VERSION ""

NS_ :

BS_:

BU_: Sound_A Ladegeraet_PAG_PF Motor_EDC17_Pirol PSM_Ant_Derivate GW_Routing_Derivate GW_Applikation_Derivate BMS_Hybrid Getriebe_Derivate LEH_Hybrid Motor_MED17_Hybrid Sound_I Tool Airbag Waehlhebel
VAL_TABLE_ KBI_ASD_Ein_Aus 1 "An" 0 "Aus" ;
VAL_TABLE_ MO_Hybridfahrzeug 3 "PlugIn_Hybrid" 2 "Full_Hybrid" 1 "Mild_Hybrid" 0 "kein_Hybridfahrzeug" ;
VAL_TABLE_ KBI_Automem_inaktiv 1 "Automem nicht aktiv" 0 "Automem aktiv" ;
VAL_TABLE_ QBit 1 "Ersatz-, Init- oder Fehlerwert" 0 "gültiger Wert" ;
VAL_TABLE_ STH_Zusatzheizung 1 "Zuheizer ein" 0 "Zuheizer aus" ;
VAL_TABLE_ xT_Tuer_geoeffnet 1 "Tuer geoeffnet" 0 "Tuer nicht geoeffnet" ;
VAL_TABLE_ KL_Zuheizer_Freigabe 1 "Zuheizerfreigabe" 0 "keine Freigabe Zuheizer" ;
VAL_TABLE_ Fehler_7Bit 127 "Fehler" ;
VAL_TABLE_ AAG_Anhaenger_abgesteckt 1 "Anhaenger wurde bei Kl. 15 aus abgesteckt" ;
VAL_TABLE_ SI_QRS_Mode 0 "QRS_Messmodus_nicht_aktiv" 1 "QRS_Messmodus_aktiv" ;
VAL_TABLE_ KY_WFS_Safe 1 "WFS nicht deaktiviert" ;
VAL_TABLE_ KYL_Warn_kein_Schluessel 0 "kein Schlüssel erkannt" ;
VAL_TABLE_ KY_Keyless_Verbau 1 "Keyless verbaut" 0 "kein Keyless verbaut" ;
VAL_TABLE_ KY_Valet_Parking 1 "Valet Schlüssel erkannt" 0 "kein Valet Schlüssel erkannt" ;
VAL_TABLE_ BCM1_MH_WIV_Schalter 1 "MH offen" 0 "MH geschlossen" ;
VAL_TABLE_ GE_MMom_Status 3 "Änderung mit Sprung" 2 "erhöhender Getriebeeingriff" 1 "reduzierender Getriebeeingriff" 0 "keine Anforderung" ;
VAL_TABLE_ GE_MMom_Soll 1023 "Fehler" 1022 "kein Eingriff" ;
VAL_TABLE_ GE_Status_Kupplung 3 "Fehler" 2 "Kupplung geschlossen" 1 "Kupplung geregelt" 0 "Kupplung geöffnet" ;
VAL_TABLE_ GE_Schaltvorgang 1 "Schaltung aktiv" 0 "keine Schaltung" ;
VAL_TABLE_ WH_Warnung 1 "Waehlhebelfehler_Fahrstufenwechsel_moeglich_(gelbes_Getriebesymbol)" 0 "keine_Anzeige" ;
VAL_TABLE_ WBA_Lampe_Shift_Lock 1 "SL_Lampe_ein" 0 "SL_Lampe_aus" ;
VAL_TABLE_ WBA_Senderkennung 1 "Motor" 0 "Getriebe" ;
VAL_TABLE_ WBA_Getriebevariante 15 "9 Gang Automat Tiptronic" 14 "8 Gang Automat Tiptronic" 13 "7 Gang Automat Tiptronic" 12 "6 Gang Automat Tiptronic" 11 "5 Gang Automat Tiptronic" 10 "tbd." 9 "tbd." 8 "2x3 shift_by_wire" 7 "tbd." 6 "Automat PRNDS" 5 "tbd." 4 "Vorhalt für ASG (Selespeed)" 3 "tbd." 2 "tbd." 1 "Automat PRND" ;
VAL_TABLE_ WBA_eing_Gang 10 "9.Gang" 9 "8.Gang" 8 "7.Gang" 7 "6.Gang" 6 "5.Gang" 5 "4.Gang" 4 "3.Gang" 3 "2.Gang" 2 "1.Gang" 1 "Init" 0 "kein Gang eingelegt / kein Gang empfohlen" ;
VAL_TABLE_ WBA_Blinken 1 "WBA_Blinken" 0 "kein_WBA_Blinken" ;
VAL_TABLE_ WBA_GE_Warnung 7 "Kupplung ueberhitzt, Fahrzeug Stopp (+ rotes Getriebefehlersymbol)" 6 "Kupplung ueberhitzt, Fahrzeug Stopp (+ gelbes Getriebefehlersymbol)" 5 "Wegrollgefahr! P nicht möglich" 4 "Getriebefehler, Weiterfahrt nur in D moeglich, P bei Motor aus" 3 "nur DL-Getriebe: Weiterfahrt nur eingeschränkt möglich. Kein R-Gang" 2 "Weiterfahrt nur eingeschränkt möglich (+ gelbes Getriebefehlersymbol)" 1 "Weiterfahrt möglich (+ gelbes Getriebefehlersymbol)" 0 "keine Anzeige" ;
VAL_TABLE_ WBA_GE_Texte 4 "Achtung_Zeitueberschreitung_P_wird_eingelegt" 3 "Wegrollgefahr_bitte_P_einlegen" 2 "zum_Einlegen_von_R,N,D_Fussbremse_betaetigen_und_Motor_starten" 1 "zum_Einlegen_einer_Fahrstufe_Fussbremse_betaetigen__ShiftLock_Information" 0 "keine Anzeige" ;
VAL_TABLE_ Veraltet_Bit 1 "veraltet" 0 "aktuell" ;
VAL_TABLE_ KBI_Variante_USA 1 "USA-Variante" 0 "keine USA-Variante" ;
VAL_TABLE_ BCM2_Bremsl_durch_ECD 1 "Bremslicht_durch_ECD_aktiv" 0 "Bremslicht_ist_aus" ;
VAL_TABLE_ KL_Thermomanagement 3 "volle Freigabe TMM (kein Heizbedarf)" 2 "mittlere Freigabe TMM" 1 "kleine Freigabe TMM" 0 "keine Freigabe TMM (max. Heizbedarf)" ;
VAL_TABLE_ KL_Atemp_ungef 255 "Fehler" 0 "Initwert" ;
VAL_TABLE_ ACC_Abstandsindex 1023 "Sonderanzeige_Fahrbahn_mit_gruenem_roten_Bereich" 1022 "Sonderanzeige_graue_Fahrbahn" 0 "Sonderanzeige_graue_Fahrbahn" ;
VAL_TABLE_ DGN_Verlernzaehler 255 "ungültiger Zählerstand oder kein gültiger Fahrzyklus" ;
VAL_TABLE_ NMH_GE_N_Haltephase 1 "N_Haltephase_aktiv" 0 "keine_N_Haltephase" ;
VAL_TABLE_ WBA_Schaltschema_Aktiv 1 "Schaltschema_anzeigen" 0 "keine_Anzeige" ;
VAL_TABLE_ MO_HYB_IstStatusK0 3 "Fehler" 2 "zu" 1 "Uebergang" 0 "auf" ;
VAL_TABLE_ NMH_MO_NM_aktiv_HV_Abschaltung 1 "Abschaltung_aktiv" 0 "kein_Nachlauf" ;
VAL_TABLE_ MO_Text_Motorstart 11 "(Belegt bei VW/Audi)" 10 "(Belegt bei VW/Audi)" 9 "(Belegt bei VW/Audi)" 8 "(Vorhalt für Start/Stopp) " 7 "(Vorhalt für Start/Stopp) " 6 "(Vorhalt für Start/Stopp) " 5 "Start/Stopp temporär nicht verfügbar" 4 "Nicht belegt (Vorhalt AUDI)" 15 "Bremse treten" 14 "Waehlhebel in PN Position" 13 "Kupplung betaetigt" 12 "Motor startet" 3 "System fordert Wiederstart" 2 "StartStopp sicherheitsbedingt deaktiviert" 1 "Motor im Stoppbetrieb" 0 "keine Anzeige" ;
VAL_TABLE_ MO_StartStopp_Codiert 1 "StartStopp vorhanden/verbaut" 0 "StartStopp nicht vorhanden/verbaut" ;
VAL_TABLE_ KBI_WV_Entr_Kof 15 "80 Sek." 14 "75 Sek." 13 "70 Sek." 12 "65 Sek." 11 "60 Sek." 10 "55 Sek." 9 "50 Sek." 8 "45 Sek." 7 "40 Sek." 6 "35 Sek." 5 "30 Sek." 4 "25 Sek." 3 "20 Sek." 2 "15 Sek." 1 "10 Sek." 0 "Türen werden nicht entriegelt" ;
VAL_TABLE_ Basiscodierung 1 "Basiscodierung invertiert" 0 "Basiscodierung" ;
VAL_TABLE_ Fehler_Init_13Bit 8191 "Fehlerwert" 8190 "Initwert" ;
VAL_TABLE_ KBI_angez_Geschw 1023 "Fehlerwert" ;
VAL_TABLE_ ESP_SpannungsAnf 1 "Anforderung Spannungswert 1" 0 "keine Anforderung" ;
VAL_TABLE_ LS_Codierung 7 "nicht verwendet" 6 "nicht verwendet" 5 "ACC Hebel, Tiptronic am Lenkrad" 4 "ACC Hebel, keine Tiptronic am Lenkrad" 3 "GRA Hebel, Tiptronic am Lenkrad" 2 "GRA Hebel, keine Tiptronic am Lenkrad" 1 "kein Hebel, Tiptronic am Lenkrad" 0 "kein Hebel, keine Tiptronic am Lenkrad" ;
VAL_TABLE_ LS_Fehler 1 "Fehler Bedienteil" 0 "in Ordnung" ;
VAL_TABLE_ Tippschalter_betaetigt 1 "Tippschalter betaetigt" 0 "Tippschalter nicht betaetigt" ;
VAL_TABLE_ LS_Abbrechen 1 "Tippschalter betätigt" 0 "Tippschalter nicht betätigt" ;
VAL_TABLE_ LS_Hauptschalter 1 "Ein" 0 "Gerastet Aus" ;
VAL_TABLE_ AAG_Bremsl_durch_ECD 1 "Bremslicht durch ECD aktiv" 0 "Bremslicht ist aus" ;
VAL_TABLE_ HU_Fotosensor 511 "Fehler" 510 "Init" 0 "Sensor unbeleuchtet" ;
VAL_TABLE_ PDCC_Last_RKP 255 "Fehlerwert" 0 "Init" ;
VAL_TABLE_ KY_WFS_LZ 3 "LZ 3" 2 "LZ 2" 1 "LZ 1" 0 "nicht def." ;
VAL_TABLE_ Freigabe_angefordert 1 "Freigabe wird angefordert" 0 "Freigabe nicht angefordert" ;
VAL_TABLE_ entriegelt_nicht_entriegelt 1 "entriegelt" 0 "nicht entriegelt" ;
VAL_TABLE_ verriegelt_nicht_verriegelt 1 "verriegelt" 0 "nicht verriegelt" ;
VAL_TABLE_ KY_FFB_Frequenz 3 "868 MHz" 2 "315 MHz" 1 "433 MHz" ;
VAL_TABLE_ KY_ID_Geb_steckt 1 "Schlüssel steckt im Zündschloss" 0 "kein Schlüssel im Zündschloss" ;
VAL_TABLE_ FFB_Taste_betaetigt 1 "Taste am Funkschlüssel betätigt" 0 "Taste nicht betätigt" ;
VAL_TABLE_ authorisiert_nicht_authorisiert 1 "authorisiert" 0 "nicht authorisiert" ;
VAL_TABLE_ OK_Defekt 1 "defekt" 0 "OK" ;
VAL_TABLE_ KL_4_Zonen 1 "4_Zonen_Klimaanlage" 0 "2_Zonen_Klimaanlage" ;
VAL_TABLE_ AB_RGS_Anst 8 "deaktiviert" 7 "aktiv_Niveau_4" 6 "aktiv_Niveau_3" 5 "aktiv_Niveau_2" 4 "aktiv_Niveau_1" ;
VAL_TABLE_ AB_Texte_AKS 2 "AKS_Systemfehler" 1 "AKS_ausgeloest" 0 "keine_AKS_Ausloesung" ;
VAL_TABLE_ SI_NWDF_gueltig 1 "NWDF_wird_unterstuetzt" 0 "NWDF_wird_nicht_unterstuetzt" ;
VAL_TABLE_ SI_NWDF 1 "Ueberwachung_freigeben" 0 "Ueberwachung_nicht_freigeben" ;
VAL_TABLE_ MO_Ext_E_Fahrt_aktiv 1 "Rueckmeldung_E_Taster_ein" 0 "Rueckmeldung_E_Taster_aus" ;
VAL_TABLE_ KL_Geblaese_Status 15 "Fehler" 14 "Init" 10 "Geblaese Stufe 100%" 9 "Geblaese Stufe 90%" 8 "Geblaese Stufe 80%" 7 "Geblaese Stufe 70%" 6 "Geblaese Stufe 60%" 5 "Geblaese Stufe 50%" 4 "Geblaese Stufe 40%" 3 "Geblaese Stufe 30%" 2 "Geblaese Stufe 20%" 1 "Geblaese Stufe 10%" 0 "Geblaese aus" ;
VAL_TABLE_ KBI_Kilometerstand 1048575 "Fehlerwert" 1048574 "Initwert" ;
VAL_TABLE_ Warnmeldung 1 "Warnmeldung" 0 "keine Warnmeldung" ;
VAL_TABLE_ EPB_Anfahrwunsch_erkannt 1 "Anfahrwunsch erkannt" 0 "kein Anfahrwunsch erkannt" ;
VAL_TABLE_ BEM_n_LLA 3 "Stufe 3" 2 "Stufe 2" 1 "Stufe 1" 0 "keine Erhöhung" ;
VAL_TABLE_ ACC_Anhalten 1 "Anhalten gewünscht" 0 "kein Anhalten gewünscht" ;
VAL_TABLE_ ACC_Beeinflussung_ESP 1 "ESP Zwangszuschaltung" 0 "keine ESP Zwangszuschaltung" ;
VAL_TABLE_ ACC_Betaetigung_EPB 1 "EPB Aktuator schliessen" 0 "keine EPB Anforderung" ;
VAL_TABLE_ ACC_Status_ACC 7 "irreversibler_Fehler_im_ACC_System" 6 "reversibler_Fehler_im_ACC_System" 5 "nicht_definiert" 4 "ACC_OVERRIDE" 3 "ACC_AKTIV_regelt" 2 "ACC_STANDBY" 1 "ACC_INIT" 0 "ACC_OFF_Hauptschalter_aus" ;
VAL_TABLE_ ACC_Loeseanforderung 1 "Löseanforderung" 0 "keine Löseanforderung" ;
VAL_TABLE_ ACC_limitierte_Anfahrdyn 1 "Limitierung Anfahrdynamik angefordert" 0 "keine Limitierung" ;
VAL_TABLE_ ACC_Getriebestellung_P 1 "Anforderung P Stellung" 0 "P Stellung nicht angefordert" ;
VAL_TABLE_ ACC_Freigabe_Verzanf 1 "Verzögerungsanforderung freigegeben" 0 "Verzögerungsanforderung nicht freigegeben" ;
VAL_TABLE_ ACC_Freigabe_Momentenanf 1 "Momentenanforderung freigegeben" 0 "Momentenanforderung nicht freigegeben" ;
VAL_TABLE_ SI_T_Mode 1 "Transportmode aktiv" 0 "Transportmode nicht aktiv" ;
VAL_TABLE_ Betaetigt 1 "betätigt" 0 "nicht betätigt" ;
VAL_TABLE_ KBI_MFA_v_Einheit_02 1 "mph" 0 "kmh" ;
VAL_TABLE_ KBI_Einheit_Druck 3 "tbd" 2 "Druckangabe in kPa" 1 "Druckangabe in psi" 0 "Druckangabe in bar" ;
VAL_TABLE_ KL_MSG_valid 1 "Message valid" 0 "Message not valid" ;
VAL_TABLE_ MO_StartStopp_Motorstopp 1 "Motor_Stop_aktiv" 0 "Motor_Stop_inaktiv" ;
VAL_TABLE_ MO_StartStopp_Wiederstart 1 "Wiederstart_aktiv" 0 "Wiederstart_inaktiv" ;
VAL_TABLE_ KBI_Aussen_Temp_gef 255 "Fehler" 254 "Init" 253 "nicht verbaut" ;
VAL_TABLE_ MO_Kraftstoffart 4 "Wasserstoff" 3 "Erdgas" 2 "CNG" 1 "Benzin" 0 "Diesel" ;
VAL_TABLE_ AB_Sitzpos_Sens 3 "Sitz vorne" 2 "Sitz nicht vorne" 1 "Fehler" 0 "nicht verfügbar" ;
VAL_TABLE_ AB_Gurtschloss 3 "gesteckt" 2 "nicht_gesteckt" 1 "nicht_verfügbar (Fehler oder Init)" 0 "nicht_verbaut" ;
VAL_TABLE_ FAS_Wunschgeschw 1023 "nicht definiert" 1022 "keine Anzeige" ;
VAL_TABLE_ FAS_Texte_Primaeranz 66 "ESP PASSIV !" 65 "Bremse haelt !" 64 "Bremse ueberhitzt !" 63 "LIM FEHLER" 62 "LIM PASSIV" 61 "LIM AKTIV " 60 "LIM AUS" 59 "Kupplung betaetigt" 58 "Bremse betaetigen !" 57 "ACC haelt an !" 56 "ACC Fehler" 55 "ACC reinigen" 54 "ACC startet" 53 "ACC aus" 52 "SET / 'GRA Symbol' xxx km/h / mph" 51 "SET / 'GRA Symbol'___xxx km/h / mph" 50 "Stehendes Objekt voraus" 49 "Steigung zu gross" 48 "Uebernehmen !" 47 "braking guard aus" 46 "braking guard aus " 45 "braking guard Bremsruck" 44 "HDC aktiv" 43 "Tempolimit Ende XXX km/h / mph" 42 "Ortsende XXX km/h / mph" 41 "Ortsanfang XXX km/h / mph" 40 "Abbiegeassistent" 39 "Tempolimit aus" 38 "Kurvenassistent aus" 37 "Drehzahl !" 36 "Schalthebelposition !" 35 "Fahrer Gurtschloss offen !" 34 "Tuer offen !" 33 "Ungueltiger Anfahrbefehl" 32 "Im Stand nicht moeglich" 31 "Fahrzeug verloren" 30 "Anfahren bestaetigen" 29 "Lenkradwinkel" 28 "XXX km/h / mph (Schriftart 2)" 27 "--- km/h / mph" 26 "!" 25 "Symbol 'Eieruhr'" 24 "ACC Abschaltung" 23 "Kurve XXX km/h / mph" 22 "Tempolimit XXX km/h / mph" 21 "VDA ACC-Symbol YYY km/h / mph" 20 "Waehlhebelposition !" 19 "Geschwindigkeitsgrenze" 18 "Parkbremse !" 17 "Herunterschalten" 16 "ESP Eingriff" 15 "Hochschalten" 14 "o  o  o" 13 "ACC nicht verfuegbar" 12 "ACC Sensor Sicht !" 11 "keine Abstandsregelung" 10 "ACC bereit" 9 "Auto_ _ _ _Auto Gong (durchgestrichen)" 8 "Auto_ _ _Auto_ Gong (durchgestrichen)" 7 "Auto_ _Auto_ _ Gong (durchgestrichen)" 6 "Auto_Auto_ _ _ Gong (durchgestrichen)" 5 "Auto_ _ _ _Auto" 4 "Auto_ _ _Auto_" 3 "Auto_ _Auto_ _" 2 "Auto_Auto_ _ _" 1 "ACC nicht verfuegbar !" 0 "keine Anzeige " ;
VAL_TABLE_ FAS_Status_Prim_Anz 3 "Farbe 3 (typisch 'gelb')" 2 "Farbe 2 (typisch 'rot')" 1 "Farbe 1 (typisch 'grün')" 0 "Symbol nicht beleuchtet" ;
VAL_TABLE_ FAS_Status_Anzeige 7 "ACC/GRA irreversibel aus" 6 "ACC reversibel aus (nicht bei GRA)" 5 "frei" 4 "ACC/GRA im Hintergrund (übertreten)" 3 "ACCGRA aktiv" 2 "ACC/GRA passiv" 1 "ACC in Init (nicht bei GRA)" 0 "ACC/GRA Hauptschalter aus" ;
VAL_TABLE_ KD_Fehler 1 "mind. ein KD-Fehler vorhanden" 0 "kein KD-Fehler" ;
VAL_TABLE_ AB_Crashdaten 1 "Crashdaten gespeichert" 0 "keine Daten gespeichert" ;
VAL_TABLE_ GE_poshebel_VAG 15 "Fehler" 14 "Tippfunktion" 13 "frei" 12 "frei" 11 "frei" 10 "frei" 9 "Position S" 8 "Position D" 7 "Position N" 6 "Position R" 5 "Position P" 4 "frei" 3 "frei" 2 "frei" 1 "Init" 0 "Zwischenstellung" ;
VAL_TABLE_ KL_St_Heizkreis 1 "Wasserventil geschlossen" 0 "Wasserventil geoeffnet" ;
VAL_TABLE_ FSAktivBit 1 "Fehler speichern" 0 "keine Fehler speichern" ;
VAL_TABLE_ KL_St_Atemp 3 "Unterbrechung" 4 "Sensorsignal unplausibel" 2 "Kurzschluss gegen Spg > 5V" 1 "Kurzschluss nach Masse" 0 "Kein Fehler" ;
VAL_TABLE_ MO_Handshake_STH 1 "EKP-Ansteuerung durch STH-Anforderung" 0 "keine EKP-Ansteuerung durch STH-Anforderung" ;
VAL_TABLE_ MO_StSt_Status 3 "Mindestens ein weiches oder hartes Veto liegt vor" 2 "Alle Vetos besagen,dass langfristig kein Motorlauf notwendig ist" 1 "Reversible Abschaltung aufgrund sicherheitsrelevanter Funktionen oder über einen Taster" 0 "Fehlerstatus erkannt oder Sicherheitsabschaltung aktiv" ;
VAL_TABLE_ StSt_Info 3 "Systemfehler" 2 "Motoranlauf zwingend notwendig (Startanforderung)" 1 "Motoranlauf nicht zwingend notwendig (Stoppverbot, keine Startanforderung, evtl. Komforteinbussen)" 0 "Motorlauf langfristig nicht notwendig (Stoppfreigabe)" ;
VAL_TABLE_ GW_STH_Anf 3 "STH Timer aktiv" 2 "Standheizung AUS" 1 "Standheizung EIN" 0 "keine EIN/AUS-Anf/kein Timer akt" ;
VAL_TABLE_ KBI_Einheit_Verbrauch 1 "mpg USA" 2 "Liter/100km" 0 "mpg UK" 3 "km/Liter" ;
VAL_TABLE_ KBI_Einheit_Volumen 3 "reserviert" 0 "Liter" 1 "Gallonen_UK" 2 "Gallonen_USA" ;
VAL_TABLE_ St_PAO_Leuchte 3 "ungültig" 2 "defekt" 1 "ein" 0 "aus" ;
VAL_TABLE_ verfuegbar 1 "verfuegbar" 0 "nicht verfuegbar" ;
VAL_TABLE_ EPB_Freig_Verzoeg_Anf 0 "Verzögerungsanforderung nicht freigegeben" 1 "Verzögerungsanforderung freigegeben" ;
VAL_TABLE_ EPB_Fehlerstatus 2 "EPB temporär nicht verfügbar - Spannen nicht möglich da Fzg. in Fahrt" 1 "EPB temporär nicht verfügbar - AVH darf nicht aktiv werden, sondern muss bei AVH-Anforderung warnen" 3 "Fehler in EPB - AVH darf von ESP nicht ausgeführt werden" 0 "kein Fehler in EPB - AVH darf von ESP ausgeführt werden" ;
VAL_TABLE_ AB_W_AWS_S 1 "Störung AWS (Sitz verspannt)" 0 "keine Störung" ;
VAL_TABLE_ Gurtwarnung 1 "Gurtwarnung auslösen" 0 "keine Warnung" ;
VAL_TABLE_ AB_PAO_Info 7 "AB BF akt.d.AWS,Schalt. a. AUTO" 6 "AB BF deakt.d.AWS,Schalt.a. AUTO" 5 "AB BF deakt.d.Schalt,AWS o.Einf." 4 "AB BF akt.d. AWS,kein Schalt.v." 3 "AB BF deakt.d.AWS,kein Schalt.v." 2 "AB BF akt.d.Schalt,kein AWS verb" 1 "AB BF deakt.d.Schalt,kein AWS v." 0 "Default / Initialwert" ;
VAL_TABLE_ AB_AWS_Zustand 7 "Fehler" 6 "Störung (Sitz verspannt)" 5 "schwerer Erwachsener" 4 "mittelschwerer Erwachsener" 3 "leichter Erwachener" 2 "Kind" 1 "Sitz leer" 0 "Default / Initialwert" ;
VAL_TABLE_ Klimastyles 3 "nicht definiert" 2 "strong" 1 "medium" 0 "soft" ;
VAL_TABLE_ Ein_Aus 1 "ein" 0 "aus" ;
VAL_TABLE_ KBI_Tankwarnung 1 "Tankwarnung aktiv" 0 "Tankwarnung nicht aktiv" ;
VAL_TABLE_ STH_Ansteuerung 3 "Heizleistung reduziert" 2 "Ein mit Motorvorwaermung" 1 "Ein" 0 "Aus" ;
VAL_TABLE_ Fzg_Antrieb 15 "Reserve" 14 "Reserve" 13 "Reserve" 12 "Reserve" 11 "Reserve" 10 "Reserve" 9 "Reserve" 8 "Reserve" 7 "Reserve" 6 "Reserve" 5 "Reserve" 4 "Reserve" 3 "Reserve" 2 "Reserve" 1 "Vierradantrieb" 0 "Zweiradantrieb" ;
VAL_TABLE_ SI_CAN_ 1 "Busruhe" 0 "keine Busruhe" ;
VAL_TABLE_ Diag_Rx_PCItype 3 "FlowControl (FC)" 2 "ConsecutiveFrame (CF)" 1 "FirstFrame (FF)" 0 "SingleFrame (SF)" ;
VAL_TABLE_ S_Brems 3 "betätigt" 2 "unplausibel" 1 "Reserve" 0 "nicht betätigt" ;
VAL_TABLE_ GE_poshebel 15 "Fehler" 14 "Manuellprog." 13 "kurzz. Manuellprog." 12 "frei" 11 "frei" 10 "frei" 9 "frei" 8 "Pos_P" 7 "Pos_R" 6 "Pos_N" 5 "Pos_D" 4 "Blinken_Pos_P" 3 "Blinken_Pos_R" 2 "Blinken_Pos_N" 1 "Blinken_Pos_D" 0 "Zwischenst." ;
VAL_TABLE_ magnet_pos 3 "nicht definiert" 2 "aktive Magnetstellung" 1 "Zwischenstellung" 0 "passive Magnetstellung" ;
VAL_TABLE_ KBI_Einheit_Sprache 255 "Fehler" 13 "Russisch" 12 "Portugiesisch" 11 "Türkisch" 10 "Schwedisch" 9 "Dänisch" 8 "Holländisch" 7 "Chinesisch (Simplified Chinese)" 6 "Japanisch (Katakana)" 5 "Italienisch" 4 "Spanisch" 3 "Französisch" 2 "US-Englisch" 1 "Englisch" 0 "Deutsch" ;
VAL_TABLE_ Sollverbau 1 "SG verbaut" 0 "SG nicht verbaut" ;
VAL_TABLE_ Schaltbeinfl 1 "Schaltverbot" 0 "keine_Beeinflussung" ;
VAL_TABLE_ Leuchten 1 "Leuchte an" 0 "Leuchte aus" ;
VAL_TABLE_ Lenker 1 "Rechtslenker" 0 "Linkslenker" ;
VAL_TABLE_ Karosserie_Typ 15 "Reserve" 14 "Reserve" 13 "Reserve" 12 "Reserve" 11 "Reserve" 10 "Reserve" 9 "Reserve" 8 "Reserve" 7 "Reserve" 6 "Reserve" 5 "Reserve" 4 "Reserve" 3 "Reserve" 2 "Targa" 1 "Cabrio" 0 "Coupe" ;
VAL_TABLE_ Baureihe 15 "Reserve" 14 "Reserve" 13 "Reserve" 12 "Reserve" 11 "Reserve" 10 "Reserve" 9 "Reserve" 8 "Reserve" 7 "Reserve" 6 "Reserve" 5 "Reserve" 4 "Reserve" 3 "Boxster" 2 "Carrera" 1 "Cayenne" 0 "Panamera" ;
VAL_TABLE_ Fehler_8Bit 255 "Fehler" ;
VAL_TABLE_ Fehler_1Bit 1 "Fehler" 0 "kein Fehler" ;
VAL_TABLE_ An_Aus 1 "an" 0 "aus" ;
VAL_TABLE_ Aktiv 1 "Aktiv" 0 "Inaktiv" ;
VAL_TABLE_ Taster 1 "Taster betätigt" 0 "Taster nicht betätigt" ;
VAL_TABLE_ B_Notbrems 1 "Notbremsung aktiv" 0 "Notbremsung nicht aktiv" ;

BO_ 3221225472 VECTOR__INDEPENDENT_SIG_MSG: 0 Vector__XXX
 SG_ KBI_Trip_E_Std : 0|15@1+ (1,0) [0|9999] "Unit_Hours" Vector__XXX
 SG_ KBI_Trip_E_Min : 0|6@1+ (1,0) [0|59] "Unit_Minut" Vector__XXX
 SG_ KBI_Service_km : 0|10@1+ (100,0) [0|102100] "" Vector__XXX
 SG_ KBI_Service_Zeit : 0|11@1+ (1,0) [0|2045] "" Vector__XXX
 SG_ KBI_Service_Typ : 0|2@1+ (1,0) [0|3] "" Vector__XXX
 SG_ DEV_BMS_Resp_07_Data : 0|64@1+ (1,0) [0|1.84467440737096E+019] "" Vector__XXX
 SG_ DEV_BMS_Resp_06_Data : 0|64@1+ (1,0) [0|1.84467440737096E+019] "" Vector__XXX
 SG_ DEV_BMS_Resp_05_Data : 0|64@1+ (1,0) [0|1.84467440737096E+019] "" Vector__XXX
 SG_ Mo_HVEM_HV_Abschaltanf : 0|1@1+ (1,0) [0|1] "" Vector__XXX
 SG_ MO_HVEM_HV_Maxleistung : 0|8@1+ (0.05,0) [0|12.5] "Unit_KiloWatt" Vector__XXX
 SG_ HVEM_Istleistung_Nebenverbrauch : 0|8@1+ (0.05,0) [0|12.5] "Unit_KiloWatt" Vector__XXX
 SG_ BMS_TauKuehlmittel__Temp_ : 0|8@1+ (1,0) [0|0] "" Vector__XXX
 SG_ SVB_IVB_FS_Fond : 0|1@1+ (1,0) [0|1] "" Vector__XXX
 SG_ SVB_IVB_FS : 0|1@1+ (1,0) [0|1] "" Vector__XXX
 SG_ SVB_IVB_BFS_Fond : 0|1@1+ (1,0) [0|1] "" Vector__XXX
 SG_ SVB_IVB_BFS : 0|1@1+ (1,0) [0|1] "" Vector__XXX
 SG_ SVB_KameraLow_FLA : 0|1@1+ (1,0) [0|1] "" Vector__XXX
 SG_ AWV_Halten : 0|1@1+ (1,0) [0|1] "" Vector__XXX
 SG_ ISO_Getriebe_01_Req_Data : 0|64@1+ (1,0) [0|1] "" Vector__XXX
 SG_ NMH_GW_VNSM_VC5 : 0|1@1+ (1,0) [0|1] "" Vector__XXX
 SG_ NMH_GW_VNSM_Wfpf : 0|1@1+ (1,0) [0|1] "" Vector__XXX

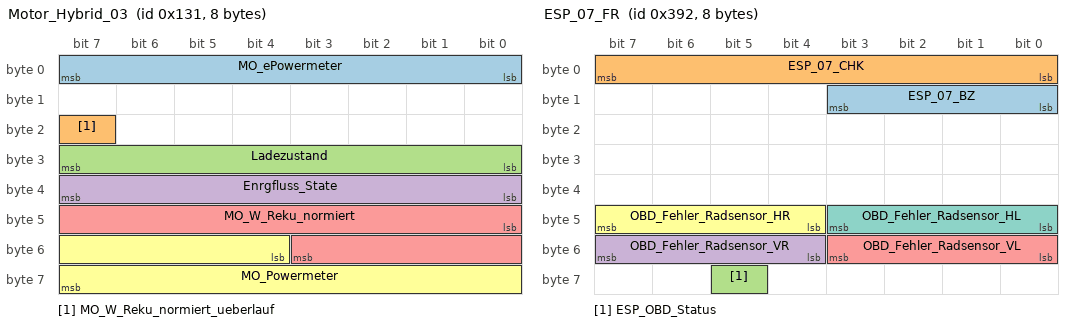
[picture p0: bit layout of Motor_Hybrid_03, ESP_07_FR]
BO_ 305 Motor_Hybrid_03: 8 Motor_MED17_Hybrid
 SG_ MO_ePowermeter : 0|8@1+ (0.4,-0.4) [0|100.8] "Unit_PerCent"  GW_Routing_Derivate
 SG_ MO_W_Reku_normiert_ueberlauf : 23|1@1+ (1,0) [0|1] ""  GW_Routing_Derivate
 SG_ Ladezustand : 24|8@1+ (1,0) [0|100] "Unit_PerCent"  Ladegeraet_PAG_PF,GW_Routing_Derivate,GW_Applikation_Derivate
 SG_ Enrgfluss_State : 32|8@1+ (1,0) [0|255] ""  GW_Routing_Derivate
 SG_ MO_W_Reku_normiert : 40|12@1+ (10,0) [0|40950] "Unit_WattSecond"  GW_Routing_Derivate
 SG_ MO_Powermeter : 52|12@1+ (1,0) [0|4092] ""  GW_Routing_Derivate

BO_ 914 ESP_07_FR: 8 PSM_Ant_Derivate
 SG_ ESP_07_BZ : 8|4@1+ (1,0) [0|15] ""  Motor_MED17_Hybrid
 SG_ ESP_07_CHK : 0|8@1+ (1,0) [0|255] ""  Motor_MED17_Hybrid
 SG_ ESP_OBD_Status : 61|1@1+ (1,0) [0|1] ""  Motor_MED17_Hybrid
 SG_ OBD_Fehler_Radsensor_VR : 52|4@1+ (1,0) [0|15] ""  Motor_MED17_Hybrid
 SG_ OBD_Fehler_Radsensor_VL : 48|4@1+ (1,0) [0|15] ""  Motor_MED17_Hybrid
 SG_ OBD_Fehler_Radsensor_HR : 44|4@1+ (1,0) [0|15] ""  Motor_MED17_Hybrid
 SG_ OBD_Fehler_Radsensor_HL : 40|4@1+ (1,0) [0|15] ""  Motor_MED17_Hybrid

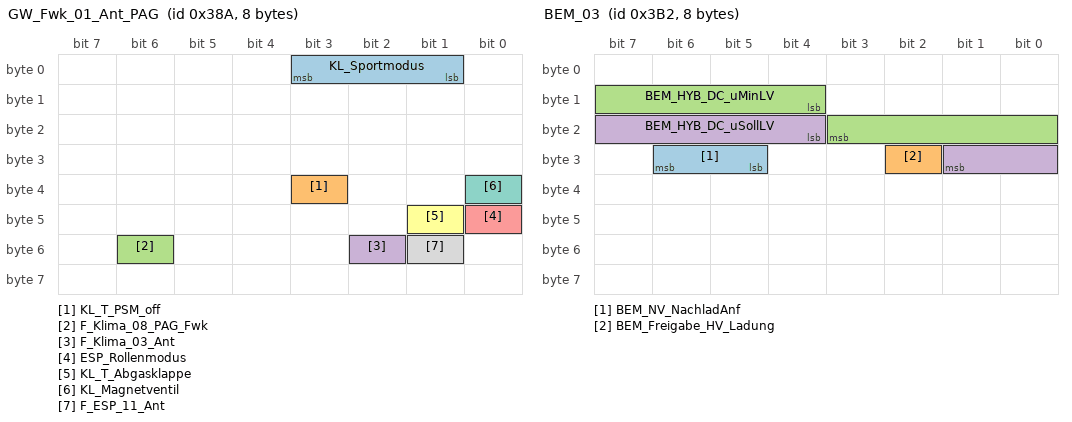
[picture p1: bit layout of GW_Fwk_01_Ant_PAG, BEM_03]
BO_ 906 GW_Fwk_01_Ant_PAG: 8 GW_Routing_Derivate
 SG_ KL_Sportmodus : 1|3@1+ (1,0) [0|7] "" Vector__XXX
 SG_ KL_T_PSM_off : 35|1@1+ (1,0) [0|1] ""  Getriebe_Derivate
 SG_ F_Klima_08_PAG_Fwk : 54|1@1+ (1,0) [0|1] ""  Motor_EDC17_Pirol,Getriebe_Derivate
 SG_ F_Klima_03_Ant : 50|1@1+ (1,0) [0|1] "" Vector__XXX
 SG_ ESP_Rollenmodus : 40|1@1+ (1,0) [0|1] "" Vector__XXX
 SG_ KL_T_Abgasklappe : 41|1@1+ (1,0) [0|1] ""  Motor_EDC17_Pirol
 SG_ KL_Magnetventil : 32|1@1+ (1,0) [0|1] "" Vector__XXX
 SG_ F_ESP_11_Ant : 49|1@1+ (1,0) [0|1] "" Vector__XXX

BO_ 1731 NMH_ESP: 7 PSM_Ant_Derivate
 SG_ NMH_ESP_Start_1 : 0|1@1+ (1,0) [0|1] ""  GW_Applikation_Derivate,Getriebe_Derivate,Motor_MED17_Hybrid,Motor_EDC17_Pirol,LEH_Hybrid,Ladegeraet_PAG_PF,BMS_Hybrid
 SG_ NMH_ESP_Start_2 : 1|1@1+ (1,0) [0|1] "" Vector__XXX
 SG_ NMH_ESP_Normal_Mode_1 : 2|1@1+ (1,0) [0|1] "" Vector__XXX
 SG_ NMH_ESP_Normal_Mode_2 : 3|1@1+ (1,0) [0|1] "" Vector__XXX
 SG_ NMH_ESP_Car_WakeUp : 6|1@1+ (1,0) [0|1] "" Vector__XXX
 SG_ NMH_ESP_Per_WakeUp : 8|5@1+ (1,0) [0|31] "" Vector__XXX
 SG_ NMH_ESP_Fkt_WakeUp : 13|3@1+ (1,0) [0|7] "" Vector__XXX
 SG_ NMH_ESP_NM_aktiv_Klemme_15 : 16|1@1+ (1,0) [0|1] "" Vector__XXX
 SG_ NMH_ESP_NM_aktiv_Diagnose : 17|1@1+ (1,0) [0|1] "" Vector__XXX
 SG_ NMH_ESP_NM_aktiv_Start : 18|1@1+ (1,0) [0|1] "" Vector__XXX
 SG_ NMH_ESP_NM_aktiv_v_groesser_Null : 19|1@1+ (1,0) [0|1] "" Vector__XXX
 SG_ NMH_ESP_Mindestaktivzeit : 21|1@1+ (1,0) [0|1] "" Vector__XXX
 SG_ NMH_ESP_kein_NL : 24|1@1+ (1,0) [0|1] "" Vector__XXX
 SG_ NMH_ESP_NL_Daten_EEPROM : 25|1@1+ (1,0) [0|1] "" Vector__XXX
 SG_ NMH_ESP_TimeOut_Fehler : 33|1@1+ (1,0) [0|1] "" Vector__XXX
 SG_ NMH_ESP_CAN_Diag_deaktiv : 34|1@1+ (1,0) [0|1] "" Vector__XXX
 SG_ NMH_ESP_KompSchutz : 35|1@1+ (1,0) [0|1] "" Vector__XXX
 SG_ NMH_ESP_Mute_Mode : 36|1@1+ (1,0) [0|1] "" Vector__XXX
 SG_ NMH_ESP_Transport_Mode : 37|1@1+ (1,0) [0|1] "" Vector__XXX
 SG_ NMH_ESP_Abschaltstufe_aktiv : 38|1@1+ (1,0) [0|1] "" Vector__XXX
 SG_ NMH_ESP_Eindraht_Fehler : 39|1@1+ (1,0) [0|1] "" Vector__XXX
 SG_ NMH_ESP_interne_Zust : 40|8@1+ (1,0) [0|255] "" Vector__XXX
 SG_ NMH_ESP_Lokalaktiv : 48|1@1+ (1,0) [0|1] "" Vector__XXX
 SG_ NMH_ESP_Subsystemaktiv : 49|1@1+ (1,0) [0|1] "" Vector__XXX

BO_ 946 BEM_03: 8 GW_Applikation_Derivate
 SG_ BEM_NV_NachladAnf : 29|2@1+ (1,0) [0|3] ""  Ladegeraet_PAG_PF
 SG_ BEM_Freigabe_HV_Ladung : 26|1@1+ (1,0) [0|1] "" Vector__XXX
 SG_ BEM_HYB_DC_uMinLV : 12|8@1+ (0.1,0) [0|25.3] "Unit_Volt"  LEH_Hybrid
 SG_ BEM_HYB_DC_uSollLV : 20|6@1+ (0.1,10.6) [10.6|16] "Unit_Volt"  LEH_Hybrid

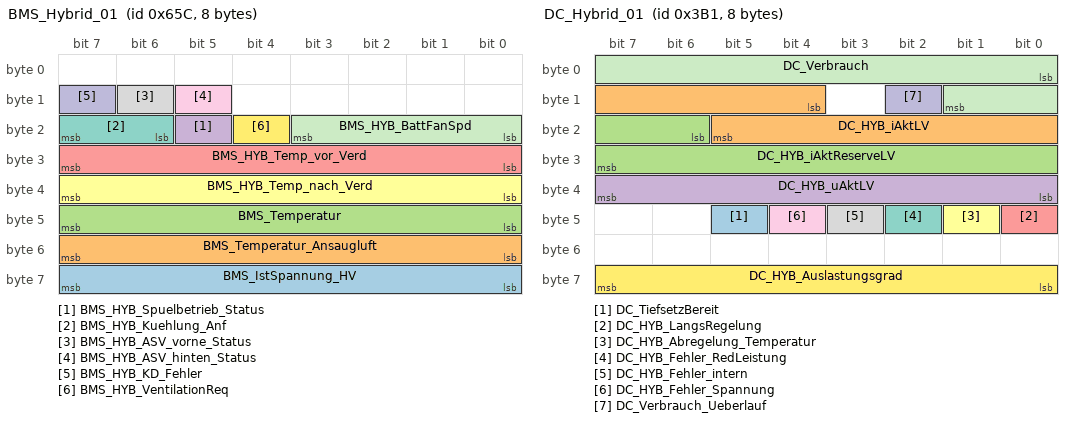
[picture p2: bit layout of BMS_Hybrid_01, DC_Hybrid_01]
BO_ 1628 BMS_Hybrid_01: 8 BMS_Hybrid
 SG_ BMS_IstSpannung_HV : 56|8@1+ (1,100) [100|350] "Unit_Volt"  GW_Routing_Derivate
 SG_ BMS_Temperatur_Ansaugluft : 48|8@1+ (0.5,-40) [-40|86.5] "Unit_DegreCelsi"  GW_Routing_Derivate
 SG_ BMS_Temperatur : 40|8@1+ (0.5,-40) [-40|86.5] "Unit_DegreCelsi"  GW_Routing_Derivate
 SG_ BMS_HYB_Spuelbetrieb_Status : 21|1@1+ (1,0) [0|1] ""  GW_Routing_Derivate
 SG_ BMS_HYB_Temp_vor_Verd : 24|8@1+ (0.5,-40) [-40|86.5] "Unit_DegreCelsi"  GW_Routing_Derivate
 SG_ BMS_HYB_Temp_nach_Verd : 32|8@1+ (0.5,-40) [-40|86.5] "Unit_DegreCelsi"  GW_Routing_Derivate
 SG_ BMS_HYB_Kuehlung_Anf : 22|2@1+ (1,0) [0|3] ""  GW_Applikation_Derivate,GW_Routing_Derivate
 SG_ BMS_HYB_ASV_vorne_Status : 14|1@1+ (1,0) [0|1] ""  GW_Routing_Derivate
 SG_ BMS_HYB_ASV_hinten_Status : 13|1@1+ (1,0) [0|1] ""  GW_Routing_Derivate
 SG_ BMS_HYB_KD_Fehler : 15|1@1+ (1,0) [0|1] ""  GW_Applikation_Derivate,GW_Routing_Derivate
 SG_ BMS_HYB_BattFanSpd : 16|4@1+ (10,0) [0|100] "Unit_PerCent"  GW_Routing_Derivate
 SG_ BMS_HYB_VentilationReq : 20|1@1+ (1,0) [0|1] ""  GW_Routing_Derivate

BO_ 490 CCP_GE_DTO_01: 8 Getriebe_Derivate
 SG_ CCP_GE_DTO_01_Data : 0|64@1+ (1,0) [0|1] ""  Tool

BO_ 488 CCP_MO_DTO_01: 8 Motor_MED17_Hybrid
 SG_ CCP_MO_DTO_01_Data : 0|64@1+ (1,0) [0|1] ""  Tool

BO_ 2616986625 CCP_MO_DTO_02: 8 Motor_MED17_Hybrid
 SG_ CCP_MO_DTO_02_Data : 0|64@1+ (1,0) [0|1] ""  Tool

BO_ 945 DC_Hybrid_01: 8 LEH_Hybrid
 SG_ DC_TiefsetzBereit : 45|1@1+ (1,0) [0|1] ""  GW_Applikation_Derivate
 SG_ DC_HYB_iAktLV : 12|10@1+ (1,-511) [-511|512] "Unit_Amper"  GW_Applikation_Derivate
 SG_ DC_HYB_iAktReserveLV : 22|10@1+ (1,-511) [-511|512] "Unit_Amper"  GW_Applikation_Derivate
 SG_ DC_HYB_uAktLV : 32|8@1+ (0.1,0) [0|25.3] "Unit_Volt"  GW_Applikation_Derivate
 SG_ DC_HYB_LangsRegelung : 40|1@1+ (1,0) [0|1] "" Vector__XXX
 SG_ DC_HYB_Abregelung_Temperatur : 41|1@1+ (1,0) [0|1] ""  GW_Applikation_Derivate
 SG_ DC_HYB_Fehler_RedLeistung : 42|1@1+ (1,0) [0|1] ""  GW_Applikation_Derivate
 SG_ DC_HYB_Fehler_intern : 43|1@1+ (1,0) [0|1] ""  GW_Applikation_Derivate
 SG_ DC_HYB_Fehler_Spannung : 44|1@1+ (1,0) [0|1] ""  GW_Applikation_Derivate
 SG_ DC_Verbrauch_Ueberlauf : 10|1@1+ (1,0) [0|1] "" Vector__XXX
 SG_ DC_Verbrauch : 0|10@1+ (1,0) [0|1023] "Unit_WattSecond" Vector__XXX
 SG_ DC_HYB_Auslastungsgrad : 56|8@1+ (0.4,0) [0|100] "Unit_PerCent"  GW_Applikation_Derivate

BO_ 1627 EM_Hybrid_01: 8 LEH_Hybrid
 SG_ EM_HYB_KD_Fehler : 15|1@1+ (1,0) [0|1] "" Vector__XXX

BO_ 256 ESP_01_VW: 8 PSM_Ant_Derivate
 SG_ ESP_v_Signal : 32|16@1+ (0.01,0) [0|655.32] "km/h"  Motor_EDC17_Pirol,GW_Routing_Derivate,Getriebe_Derivate,Motor_MED17_Hybrid,LEH_Hybrid,BMS_Hybrid,GW_Applikation_Derivate
 SG_ ESP_01_CHK : 0|8@1+ (1,0) [0|255] ""  Motor_EDC17_Pirol,GW_Routing_Derivate,BMS_Hybrid,LEH_Hybrid,Getriebe_Derivate,Motor_MED17_Hybrid
 SG_ ESP_01_BZ : 8|4@1+ (1,0) [0|15] ""  Motor_EDC17_Pirol,GW_Routing_Derivate,LEH_Hybrid,Getriebe_Derivate,Motor_MED17_Hybrid,BMS_Hybrid
 SG_ ASR_Moment_langsam : 12|10@1+ (1,0) [0|1021] ""  Motor_EDC17_Pirol,GW_Routing_Derivate,Motor_MED17_Hybrid
 SG_ ASR_MSR_Moment_schnell : 22|10@1+ (1,0) [0|1021] ""  Motor_EDC17_Pirol,GW_Routing_Derivate,Motor_MED17_Hybrid
 SG_ ASR_Tastung_passiv : 48|1@1+ (1,0) [0|1] ""  Motor_EDC17_Pirol,GW_Routing_Derivate,Getriebe_Derivate,Motor_MED17_Hybrid
 SG_ ESP_Tastung_passiv : 49|1@1+ (1,0) [0|1] ""  Motor_EDC17_Pirol,GW_Routing_Derivate,Getriebe_Derivate,Motor_MED17_Hybrid
 SG_ ESP_Systemstatus : 50|1@1+ (1,0) [0|1] ""  Motor_EDC17_Pirol,GW_Routing_Derivate,Motor_MED17_Hybrid,Getriebe_Derivate
 SG_ ASR_Schalteingriff : 51|2@1+ (1,0) [0|3] ""  GW_Routing_Derivate,Getriebe_Derivate
 SG_ OBD_Schlechtweg : 53|1@1+ (1,0) [0|1] ""  GW_Routing_Derivate
 SG_ OBD_QBit_Schlechtweg : 54|1@1+ (1,0) [0|1] ""  GW_Routing_Derivate
 SG_ ESP_QBit_v_Signal : 55|1@1+ (1,0) [0|1] ""  BMS_Hybrid,Motor_EDC17_Pirol,GW_Routing_Derivate,LEH_Hybrid,Motor_MED17_Hybrid
 SG_ ABS_Bremsung : 56|1@1+ (1,0) [0|1] ""  Motor_EDC17_Pirol,GW_Routing_Derivate,Getriebe_Derivate,Motor_MED17_Hybrid
 SG_ ASR_Anf : 57|1@1+ (1,0) [0|1] ""  Motor_EDC17_Pirol,GW_Routing_Derivate,Getriebe_Derivate,Motor_MED17_Hybrid
 SG_ MSR_Anf : 58|1@1+ (1,0) [0|1] ""  Motor_EDC17_Pirol,GW_Routing_Derivate,Getriebe_Derivate,Motor_MED17_Hybrid
 SG_ EBV_Eingriff : 59|1@1+ (1,0) [0|1] ""  Motor_EDC17_Pirol,GW_Routing_Derivate,Motor_MED17_Hybrid
 SG_ EDS_Eingriff : 60|1@1+ (1,0) [0|1] ""  Motor_EDC17_Pirol,GW_Routing_Derivate,Getriebe_Derivate,Motor_MED17_Hybrid
 SG_ ESP_Eingriff : 61|1@1+ (1,0) [0|1] ""  Motor_EDC17_Pirol,GW_Routing_Derivate,Getriebe_Derivate,Motor_MED17_Hybrid
 SG_ ESP_ASP : 62|1@1+ (1,0) [0|1] ""  Motor_EDC17_Pirol,GW_Routing_Derivate,Motor_MED17_Hybrid
 SG_ ESP_KD_Fehler : 63|1@1+ (1,0) [0|1] ""  GW_Applikation_Derivate,GW_Routing_Derivate

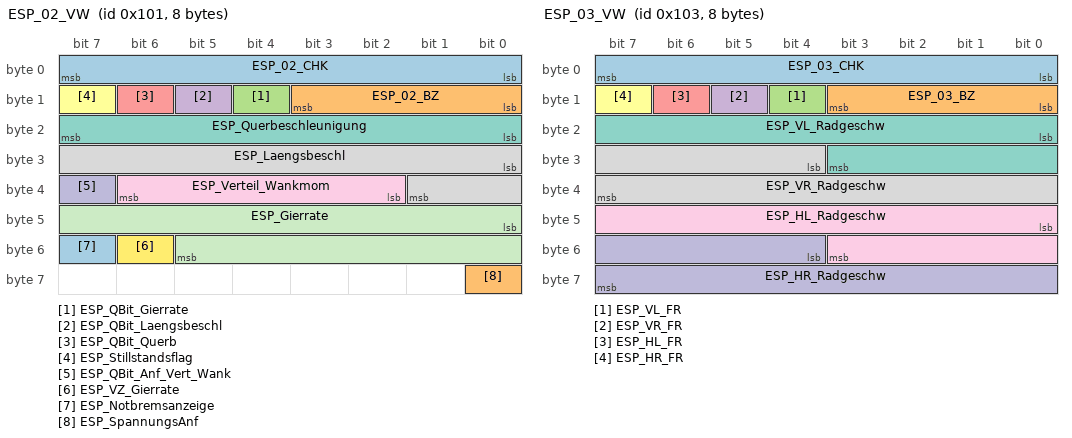
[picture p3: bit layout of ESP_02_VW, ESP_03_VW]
BO_ 257 ESP_02_VW: 8 PSM_Ant_Derivate
 SG_ ESP_02_CHK : 0|8@1+ (1,0) [0|255] ""  Motor_EDC17_Pirol,GW_Routing_Derivate,Getriebe_Derivate,Motor_MED17_Hybrid
 SG_ ESP_02_BZ : 8|4@1+ (1,0) [0|15] ""  Motor_EDC17_Pirol,GW_Routing_Derivate,Getriebe_Derivate,Motor_MED17_Hybrid
 SG_ ESP_QBit_Gierrate : 12|1@1+ (1,0) [0|1] ""  GW_Routing_Derivate
 SG_ ESP_QBit_Laengsbeschl : 13|1@1+ (1,0) [0|1] ""  Motor_EDC17_Pirol,GW_Routing_Derivate,Motor_MED17_Hybrid
 SG_ ESP_QBit_Querb : 14|1@1+ (1,0) [0|1] ""  Motor_EDC17_Pirol,GW_Routing_Derivate,Motor_MED17_Hybrid
 SG_ ESP_Stillstandsflag : 15|1@1+ (1,0) [0|1] ""  Motor_EDC17_Pirol,GW_Routing_Derivate,Motor_MED17_Hybrid
 SG_ ESP_Querbeschleunigung : 16|8@1+ (0.01,-1.27) [-1.27|1.27] "Unit_ForceOfGravi"  Motor_EDC17_Pirol,GW_Routing_Derivate,Getriebe_Derivate,Motor_MED17_Hybrid
 SG_ ESP_Laengsbeschl : 24|10@1+ (0.03125,-16) [-16|15.90625] ""  Motor_EDC17_Pirol,GW_Routing_Derivate,Getriebe_Derivate,Motor_MED17_Hybrid
 SG_ ESP_Verteil_Wankmom : 34|5@1+ (0.1,-1) [-1|1] ""  GW_Routing_Derivate
 SG_ ESP_QBit_Anf_Vert_Wank : 39|1@1+ (1,0) [0|1] ""  GW_Routing_Derivate
 SG_ ESP_Gierrate : 40|14@1+ (0.01,0) [0|163.82] "Unit_DegreOfArcPerSecon"  GW_Routing_Derivate
 SG_ ESP_VZ_Gierrate : 54|1@1+ (1,0) [0|1] ""  GW_Routing_Derivate
 SG_ ESP_Notbremsanzeige : 55|1@1+ (1,0) [0|1] ""  GW_Routing_Derivate
 SG_ ESP_SpannungsAnf : 56|1@1+ (1,0) [0|1] ""  GW_Routing_Derivate

BO_ 1795 ISO_Funktionaler_Req_Abgas: 8 GW_Routing_Derivate
 SG_ ISO_Functionaler_Req_Abgas : 0|64@1+ (1,0) [0|1] ""  Ladegeraet_PAG_PF,BMS_Hybrid,Motor_EDC17_Pirol,Motor_MED17_Hybrid,Getriebe_Derivate,LEH_Hybrid

BO_ 482 CCP_GE_CR0_01: 8 GW_Routing_Derivate
 SG_ CCP_GE_CRO_01_Data : 0|64@1+ (1,0) [0|1] ""  Getriebe_Derivate

BO_ 259 ESP_03_VW: 8 PSM_Ant_Derivate
 SG_ ESP_03_CHK : 0|8@1+ (1,0) [0|255] ""  Motor_EDC17_Pirol,GW_Routing_Derivate,Getriebe_Derivate,Motor_MED17_Hybrid
 SG_ ESP_03_BZ : 8|4@1+ (1,0) [0|15] ""  Motor_EDC17_Pirol,GW_Routing_Derivate,Getriebe_Derivate,Motor_MED17_Hybrid
 SG_ ESP_VL_FR : 12|1@1+ (1,0) [0|1] ""  Motor_EDC17_Pirol,GW_Routing_Derivate,Getriebe_Derivate,Motor_MED17_Hybrid
 SG_ ESP_VR_FR : 13|1@1+ (1,0) [0|1] ""  Motor_EDC17_Pirol,GW_Routing_Derivate,Getriebe_Derivate,Motor_MED17_Hybrid
 SG_ ESP_HL_FR : 14|1@1+ (1,0) [0|1] ""  Motor_EDC17_Pirol,GW_Routing_Derivate,Getriebe_Derivate,Motor_MED17_Hybrid
 SG_ ESP_HR_FR : 15|1@1+ (1,0) [0|1] ""  Motor_EDC17_Pirol,GW_Routing_Derivate,Getriebe_Derivate,Motor_MED17_Hybrid
 SG_ ESP_VL_Radgeschw : 16|12@1+ (0.1,0) [0|409.2] "Unit_KiloMeterPerHour"  Motor_MED17_Hybrid,GW_Routing_Derivate,Motor_EDC17_Pirol,Getriebe_Derivate
 SG_ ESP_VR_Radgeschw : 28|12@1+ (0.1,0) [0|409.2] "Unit_KiloMeterPerHour"  Motor_MED17_Hybrid,GW_Routing_Derivate,Motor_EDC17_Pirol,Getriebe_Derivate
 SG_ ESP_HL_Radgeschw : 40|12@1+ (0.1,0) [0|409.2] "Unit_KiloMeterPerHour"  Motor_MED17_Hybrid,GW_Routing_Derivate,Motor_EDC17_Pirol,Getriebe_Derivate
 SG_ ESP_HR_Radgeschw : 52|12@1+ (0.1,0) [0|409.2] "Unit_KiloMeterPerHour"  Motor_MED17_Hybrid,Motor_EDC17_Pirol,GW_Routing_Derivate,Getriebe_Derivate

BO_ 776 ESP_04_VW: 8 PSM_Ant_Derivate
 SG_ ESP_HDC_FktLampe : 3|1@1+ (1,0) [0|1] "" Vector__XXX
 SG_ ESP_ASR_Lampe : 31|1@1+ (1,0) [0|1] "" Vector__XXX
 SG_ ESP_Meldungen : 0|3@1+ (1,0) [0|7] "" Vector__XXX
 SG_ ESP_Lampe : 4|1@1+ (1,0) [0|1] "" Vector__XXX
 SG_ ABS_Lampe : 5|1@1+ (1,0) [0|1] "" Vector__XXX
 SG_ BK_Lampe : 6|1@1+ (1,0) [0|1] "" Vector__XXX
 SG_ ESP_Akustik : 7|2@1+ (1,0) [0|3] "" Vector__XXX
 SG_ ESP_Diagnose : 9|1@1+ (1,0) [0|1] ""  GW_Routing_Derivate,GW_Applikation_Derivate
 SG_ ESP_Textanzeigen_02 : 10|5@1+ (1,0) [0|31] "" Vector__XXX
 SG_ ESP_Off_Lampe : 15|1@1+ (1,0) [0|1] "" Vector__XXX
 SG_ ESP_m_Raddrehz : 16|15@1+ (0.002,0) [0|65.278] "Unit_Hertz" Vector__XXX
 SG_ ESP_Wegimp_VA : 32|11@1+ (1,0) [0|2047] ""  Getriebe_Derivate
 SG_ ESP_Fehlerstatus_Wegimp : 43|1@1+ (1,0) [0|1] "" Vector__XXX
 SG_ ESP_Wegimp_Ueberlauf : 44|1@1+ (1,0) [0|1] "" Vector__XXX
 SG_ ESP_QBit_Wegimp_VA : 45|1@1+ (1,0) [0|1] "" Vector__XXX
 SG_ ESP_Displaywarnungen : 46|2@1+ (1,0) [0|3] "" Vector__XXX
 SG_ ESP_HDC_Regelgeschw : 48|7@1+ (0.32,0) [0.32|39.68] "Unit_KiloMeterPerHour" Vector__XXX
 SG_ ESP_BKV_Warnung : 55|1@1+ (1,0) [0|1] "" Vector__XXX
 SG_ ESP_Zaehnezahl : 56|8@1+ (1,0) [0|255] ""  Getriebe_Derivate

BO_ 262 ESP_05_VW: 8 PSM_Ant_Derivate
 SG_ ESP_Status_Anfahrhilfe : 40|1@1+ (1,0) [0|1] ""  Motor_EDC17_Pirol,Motor_MED17_Hybrid,GW_Routing_Derivate
 SG_ ESP_Anforderung_EPB : 62|2@1+ (1,0) [0|3] ""  GW_Routing_Derivate
 SG_ ESP_Lenkeingriff_ADS : 28|1@1+ (1,0) [0|1] ""  GW_Routing_Derivate
 SG_ ESP_Bremsruck_AWV2 : 30|1@1+ (1,0) [0|1] ""  GW_Routing_Derivate
 SG_ ESP_Konsistenz_AWV2 : 31|1@1+ (1,0) [0|1] ""  GW_Routing_Derivate
 SG_ ESP_05_CHK : 0|8@1+ (1,0) [0|255] ""  Motor_EDC17_Pirol,Motor_MED17_Hybrid,GW_Routing_Derivate,Getriebe_Derivate
 SG_ ESP_05_BZ : 8|4@1+ (1,0) [0|15] ""  Motor_EDC17_Pirol,Motor_MED17_Hybrid,GW_Routing_Derivate,Getriebe_Derivate
 SG_ ESP_QBit_Bremsdruck : 12|1@1+ (1,0) [0|1] ""  Motor_EDC17_Pirol,Motor_MED17_Hybrid,GW_Routing_Derivate,Getriebe_Derivate
 SG_ ESP_QBit_Fahrer_bremst : 13|1@1+ (1,0) [0|1] ""  Motor_EDC17_Pirol,Motor_MED17_Hybrid,GW_Routing_Derivate
 SG_ ESP_Schwelle_Unterdruck : 14|2@1+ (1,0) [0|3] ""  Motor_EDC17_Pirol,Motor_MED17_Hybrid,GW_Routing_Derivate
 SG_ ESP_Bremsdruck : 16|10@1+ (0.3,-30) [-30|276.6] "Unit_Bar"  Motor_EDC17_Pirol,Motor_MED17_Hybrid,GW_Routing_Derivate,Getriebe_Derivate
 SG_ ESP_Fahrer_bremst : 26|1@1+ (1,0) [0|1] ""  Motor_EDC17_Pirol,Motor_MED17_Hybrid,GW_Routing_Derivate
 SG_ ESP_Verz_TSK_aktiv : 27|1@1+ (1,0) [0|1] ""  Motor_EDC17_Pirol,Getriebe_Derivate,Motor_MED17_Hybrid,GW_Routing_Derivate
 SG_ ESP_Konsistenz_TSK : 29|1@1+ (1,0) [0|1] ""  Motor_EDC17_Pirol,Motor_MED17_Hybrid,GW_Routing_Derivate
 SG_ ECD_Fehler : 32|1@1+ (1,0) [0|1] ""  Motor_EDC17_Pirol,Motor_MED17_Hybrid,GW_Routing_Derivate
 SG_ ECD_nicht_verfuegbar : 33|1@1+ (1,0) [0|1] ""  Motor_EDC17_Pirol,Motor_MED17_Hybrid,GW_Routing_Derivate
 SG_ ESP_Status_Bremsentemp : 34|1@1+ (1,0) [0|1] ""  Motor_EDC17_Pirol,Motor_MED17_Hybrid,GW_Routing_Derivate
 SG_ ESP_Autohold_Standby : 35|1@1+ (1,0) [0|1] ""  GW_Routing_Derivate
 SG_ ESP_HDC_Standby : 36|1@1+ (1,0) [0|1] ""  Motor_EDC17_Pirol,Motor_MED17_Hybrid,GW_Routing_Derivate
 SG_ ESP_HBA_aktiv : 37|1@1+ (1,0) [0|1] ""  GW_Routing_Derivate
 SG_ ESP_Prefill_ausgeloest : 38|1@1+ (1,0) [0|1] ""  GW_Routing_Derivate
 SG_ ESP_Rueckwaertsfahrt_erkannt : 39|1@1+ (1,0) [0|1] ""  GW_Routing_Derivate
 SG_ ESP_StartStopp_Info : 42|2@1+ (1,0) [0|3] ""  Motor_EDC17_Pirol,Motor_MED17_Hybrid,GW_Routing_Derivate
 SG_ ESP_Eingr_HL : 44|1@1+ (1,0) [0|1] ""  GW_Routing_Derivate
 SG_ ESP_Eingr_HR : 45|1@1+ (1,0) [0|1] ""  GW_Routing_Derivate
 SG_ ESP_Eingr_VL : 46|1@1+ (1,0) [0|1] ""  GW_Routing_Derivate
 SG_ ESP_Eingr_VR : 47|1@1+ (1,0) [0|1] ""  GW_Routing_Derivate
 SG_ ESP_BKV_Unterdruck : 48|8@1+ (4,0) [0|256] "Unit_MilliBar"  Motor_EDC17_Pirol,Motor_MED17_Hybrid,GW_Routing_Derivate
 SG_ ESP_Autohold_aktiv : 56|1@1+ (1,0) [0|1] ""  Motor_EDC17_Pirol,Motor_MED17_Hybrid,GW_Routing_Derivate
 SG_ ESP_FStatus_Anfahrhilfe : 57|1@1+ (1,0) [0|1] ""  GW_Routing_Derivate
 SG_ ESP_Verz_EPB_aktiv : 58|1@1+ (1,0) [0|1] ""  GW_Routing_Derivate,Getriebe_Derivate
 SG_ ECD_Bremslicht : 59|1@1+ (1,0) [0|1] ""  Motor_EDC17_Pirol,Motor_MED17_Hybrid,GW_Routing_Derivate
 SG_ ESP_Verzoeg_EPB_verf : 60|1@1+ (1,0) [0|1] ""  GW_Routing_Derivate
 SG_ ESP_Status_Bremsdruck : 61|1@1+ (1,0) [0|1] ""  Motor_EDC17_Pirol,Motor_MED17_Hybrid,GW_Routing_Derivate

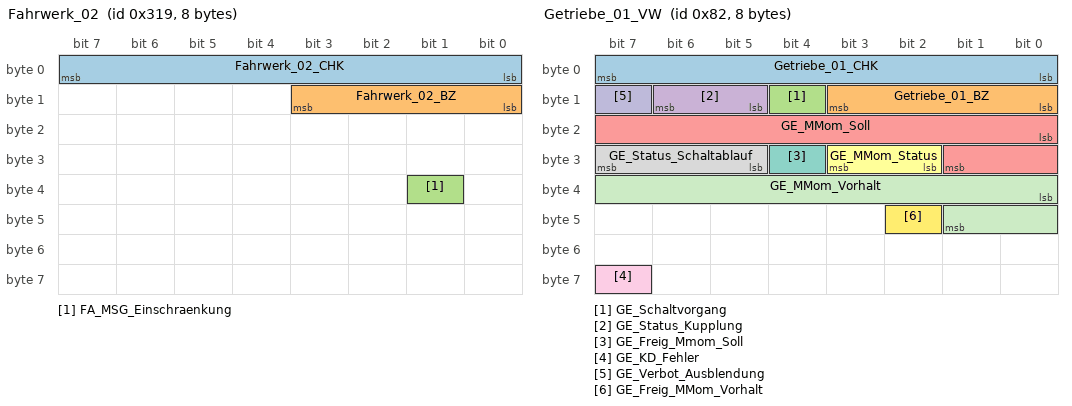
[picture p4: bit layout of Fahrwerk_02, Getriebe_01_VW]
BO_ 793 Fahrwerk_02: 8 GW_Routing_Derivate
 SG_ Fahrwerk_02_CHK : 0|8@1+ (1,0) [0|255] ""  Motor_EDC17_Pirol,Motor_MED17_Hybrid
 SG_ Fahrwerk_02_BZ : 8|4@1+ (1,0) [0|15] ""  Motor_EDC17_Pirol,Motor_MED17_Hybrid
 SG_ FA_MSG_Einschraenkung : 33|1@1+ (1,0) [0|1] ""  Motor_EDC17_Pirol,Motor_MED17_Hybrid

BO_ 924 Gateway_05_VW: 8 GW_Routing_Derivate
 SG_ KL_Beschlagsgefahr : 30|1@1+ (1,0) [0|1] "" Vector__XXX
 SG_ ESP_07_alt : 4|1@1+ (1,0) [0|1] "" Vector__XXX
 SG_ BCM1_GLW_Fernlicht_Anf : 31|1@1+ (1,0) [0|1] "" Vector__XXX
 SG_ BCM1_Gleitende_Leuchtw_Anf : 54|1@1+ (1,0) [0|1] "" Vector__XXX
 SG_ BCM1_Adaptive_Lichtvert_Anf : 53|1@1+ (1,0) [0|1] "" Vector__XXX
 SG_ ESP_Offroad_Modus : 56|1@1+ (1,0) [0|1] ""  Getriebe_Derivate
 SG_ Wischer_vorne_aktiv : 17|1@1+ (1,0) [0|1] ""  Motor_EDC17_Pirol,Motor_MED17_Hybrid
 SG_ HR_Tuer_geoeffnet : 52|1@1+ (1,0) [0|1] ""  Motor_EDC17_Pirol,Motor_MED17_Hybrid
 SG_ HL_Tuer_geoeffnet : 51|1@1+ (1,0) [0|1] ""  Motor_EDC17_Pirol,Motor_MED17_Hybrid
 SG_ FT_Sperrklinke : 35|1@1+ (1,0) [0|1] ""  Motor_EDC17_Pirol,Motor_MED17_Hybrid
 SG_ BT_Tuer_geoeffnet : 50|1@1+ (1,0) [0|1] ""  Motor_EDC17_Pirol,Motor_MED17_Hybrid
 SG_ BCM1_02_alt : 0|1@1+ (1,0) [0|1] ""  Motor_EDC17_Pirol,Motor_MED17_Hybrid
 SG_ BCM1_01_alt : 3|1@1+ (1,0) [0|1] ""  Motor_EDC17_Pirol,Motor_MED17_Hybrid
 SG_ FT_Tuer_geoeffnet : 33|1@1+ (1,0) [0|1] ""  Motor_EDC17_Pirol,Getriebe_Derivate,Motor_MED17_Hybrid
 SG_ BCM1_Rueckfahrlicht_Schalter : 18|1@1+ (1,0) [0|1] ""  Motor_EDC17_Pirol,Motor_MED17_Hybrid
 SG_ BCM1_MH_WIV_Schalter : 16|1@1+ (1,0) [0|1] ""  Motor_EDC17_Pirol,Motor_MED17_Hybrid
 SG_ BCM1_Aussen_Temp_ungef : 40|8@1+ (0.5,-50) [-50|76] "Unit_DegreCelsi"  LEH_Hybrid,BMS_Hybrid,Motor_EDC17_Pirol,Motor_MED17_Hybrid
 SG_ BCM2_03_PAG_alt : 11|1@1+ (1,0) [0|1] "" Vector__XXX
 SG_ Klima_02_alt : 2|1@1+ (1,0) [0|1] "" Vector__XXX
 SG_ KL_Zuheizer_Freigabe : 20|1@1+ (1,0) [0|1] "" Vector__XXX
 SG_ BCM_Handshake_STH : 34|1@1+ (1,0) [0|1] "" Vector__XXX
 SG_ Wischer_01_alt : 1|1@1+ (1,0) [0|1] ""  Motor_EDC17_Pirol,Motor_MED17_Hybrid
 SG_ TSG_BT_1_alt : 5|1@1+ (1,0) [0|1] ""  Motor_EDC17_Pirol,Motor_MED17_Hybrid
 SG_ TSG_HL_1_alt : 6|1@1+ (1,0) [0|1] ""  Motor_EDC17_Pirol,Motor_MED17_Hybrid
 SG_ TSG_HR_1_alt : 7|1@1+ (1,0) [0|1] ""  Motor_EDC17_Pirol,Motor_MED17_Hybrid
 SG_ Klima_Sensor_02_alt : 9|1@1+ (1,0) [0|1] ""  LEH_Hybrid,BMS_Hybrid,Motor_EDC17_Pirol,Motor_MED17_Hybrid
 SG_ TSG_FT_1_alt : 10|1@1+ (1,0) [0|1] ""  Motor_EDC17_Pirol,Getriebe_Derivate,Motor_MED17_Hybrid
 SG_ Parkhilfe_01_alt : 13|1@1+ (1,0) [0|1] ""  Motor_EDC17_Pirol,Motor_MED17_Hybrid
 SG_ Fahrwerk_02_alt : 14|1@1+ (1,0) [0|1] ""  Motor_EDC17_Pirol,Motor_MED17_Hybrid
 SG_ FA_StartStopp_Info : 26|2@1+ (1,0) [0|3] ""  Motor_EDC17_Pirol,Motor_MED17_Hybrid
 SG_ PH_StartStopp_Info : 28|2@1+ (1,0) [0|3] ""  Motor_EDC17_Pirol,Motor_MED17_Hybrid
 SG_ BCM1_OBD_FStatus_ATemp : 36|4@1+ (1,0) [0|15] ""  Motor_EDC17_Pirol,Motor_MED17_Hybrid
 SG_ BCM1_Schalter_StartStopp : 55|1@1+ (1,0) [0|1] ""  Motor_EDC17_Pirol,Motor_MED17_Hybrid

BO_ 1604 Gateway_11_VW: 8 GW_Routing_Derivate
 SG_ ESP_Diagnose : 38|1@1+ (1,0) [0|1] "" Vector__XXX
 SG_ ESP_04_alt : 7|1@1+ (1,0) [0|1] "" Vector__XXX
 SG_ ZV_Tankklappe_offen : 45|1@1+ (1,0) [0|1] "" Vector__XXX
 SG_ BCM_Tankwunsch : 43|2@1+ (1,0) [0|3] "" Vector__XXX
 SG_ ZV_verriegelt_extern_ist : 42|1@1+ (1,0) [0|1] ""  Ladegeraet_PAG_PF
 SG_ BCM2_02_alt : 4|1@1+ (1,0) [0|1] "" Vector__XXX
 SG_ Kessy_01_alt : 8|1@1+ (1,0) [0|1] ""  Ladegeraet_PAG_PF
 SG_ FFB_CarFinder : 41|1@1+ (1,0) [0|1] ""  Ladegeraet_PAG_PF
 SG_ FFB_Auf_Taste : 40|1@1+ (1,0) [0|1] ""  Ladegeraet_PAG_PF
 SG_ Dummy_Blinkmodi_01_alt : 15|1@1+ (1,0) [0|1] "" Vector__XXX
 SG_ BCM1_01_alt : 2|1@1+ (1,0) [0|1] "" Vector__XXX
 SG_ LV_Nebelschlusslicht_Anzeige : 30|1@1+ (1,0) [0|1] "" Vector__XXX
 SG_ LV_Abblendlicht_re_def : 26|1@1+ (1,0) [0|1] "" Vector__XXX
 SG_ LV_Abblendlicht_li_def : 25|1@1+ (1,0) [0|1] "" Vector__XXX
 SG_ BM_Autobahn : 18|1@1+ (1,0) [0|1] "" Vector__XXX
 SG_ BCM1_Touristen_Licht_Anf : 24|1@1+ (1,0) [0|1] "" Vector__XXX
 SG_ BCM1_Linksverkehr : 31|1@1+ (1,0) [0|1] "" Vector__XXX
 SG_ BCM1_Licht_Dunkelheit_aktiv : 29|1@1+ (1,0) [0|1] "" Vector__XXX
 SG_ BCM1_Allwetterlicht_Anf : 36|1@1+ (1,0) [0|1] "" Vector__XXX
 SG_ BCM1_MH_Schalter : 21|1@1+ (1,0) [0|1] ""  Motor_EDC17_Pirol,Motor_MED17_Hybrid
 SG_ BH_Blinker_re : 17|1@1+ (1,0) [0|1] ""  Motor_EDC17_Pirol,Motor_MED17_Hybrid
 SG_ BH_Blinker_li : 16|1@1+ (1,0) [0|1] ""  Motor_EDC17_Pirol,Motor_MED17_Hybrid
 SG_ SMLS_01_alt : 0|1@1+ (1,0) [0|1] ""  Motor_EDC17_Pirol,Motor_MED17_Hybrid
 SG_ BCM1_02_alt : 3|1@1+ (1,0) [0|1] ""  Ladegeraet_PAG_PF,Motor_EDC17_Pirol,Motor_MED17_Hybrid
 SG_ HYB_Anf_E_Mode_alt : 5|1@1+ (1,0) [0|1] ""  Motor_MED17_Hybrid
 SG_ HYB_Anf_E_Mode : 22|1@1+ (1,0) [0|1] ""  Motor_MED17_Hybrid

BO_ 130 Getriebe_01_VW: 8 Getriebe_Derivate
 SG_ Getriebe_01_CHK : 0|8@1+ (1,0) [0|255] ""  Motor_EDC17_Pirol,PSM_Ant_Derivate,GW_Routing_Derivate,Motor_MED17_Hybrid
 SG_ Getriebe_01_BZ : 8|4@1+ (1,0) [0|15] ""  Motor_EDC17_Pirol,PSM_Ant_Derivate,GW_Routing_Derivate,Motor_MED17_Hybrid
 SG_ GE_Schaltvorgang : 12|1@1+ (1,0) [0|1] ""  Motor_EDC17_Pirol,PSM_Ant_Derivate,GW_Routing_Derivate,Motor_MED17_Hybrid
 SG_ GE_Status_Kupplung : 13|2@1+ (1,0) [0|3] ""  Motor_EDC17_Pirol,PSM_Ant_Derivate,GW_Routing_Derivate,Motor_MED17_Hybrid
 SG_ GE_MMom_Soll : 16|10@1+ (1,0) [0|1021] ""  Motor_EDC17_Pirol,PSM_Ant_Derivate,GW_Routing_Derivate,Motor_MED17_Hybrid
 SG_ GE_MMom_Status : 26|2@1+ (1,0) [0|3] ""  Motor_EDC17_Pirol,PSM_Ant_Derivate,GW_Routing_Derivate,Motor_MED17_Hybrid
 SG_ GE_Freig_Mmom_Soll : 28|1@1+ (1,0) [0|1] ""  PSM_Ant_Derivate,GW_Routing_Derivate
 SG_ GE_Status_Schaltablauf : 29|3@1+ (1,0) [0|7] ""  PSM_Ant_Derivate,GW_Routing_Derivate
 SG_ GE_KD_Fehler : 63|1@1+ (1,0) [0|1] ""  PSM_Ant_Derivate,GW_Applikation_Derivate,GW_Routing_Derivate
 SG_ GE_Verbot_Ausblendung : 15|1@1+ (1,0) [0|1] ""  GW_Routing_Derivate,Motor_EDC17_Pirol,Motor_MED17_Hybrid
 SG_ GE_MMom_Vorhalt : 32|10@1+ (1,0) [0|1021] ""  GW_Routing_Derivate,Motor_EDC17_Pirol,Motor_MED17_Hybrid
 SG_ GE_Freig_MMom_Vorhalt : 42|1@1+ (1,0) [0|1] ""  GW_Routing_Derivate,Motor_EDC17_Pirol,Motor_MED17_Hybrid

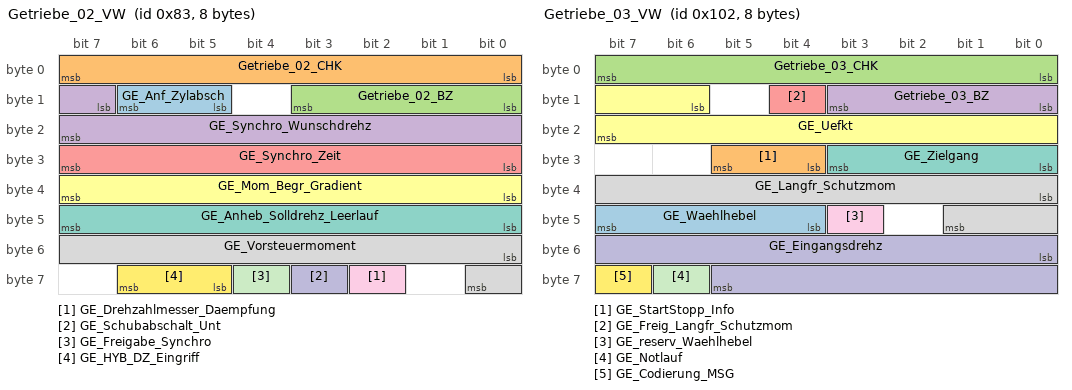
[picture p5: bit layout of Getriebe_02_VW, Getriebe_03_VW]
BO_ 131 Getriebe_02_VW: 8 Getriebe_Derivate
 SG_ GE_Anf_Zylabsch : 13|2@1+ (1,0) [0|3] "" Vector__XXX
 SG_ Getriebe_02_CHK : 0|8@1+ (1,0) [0|255] ""  Motor_EDC17_Pirol,Motor_MED17_Hybrid
 SG_ Getriebe_02_BZ : 8|4@1+ (1,0) [0|15] ""  Motor_EDC17_Pirol,Motor_MED17_Hybrid
 SG_ GE_Synchro_Wunschdrehz : 15|9@1+ (25,0) [0|12750] "Unit_MinutInver"  Motor_EDC17_Pirol,Motor_MED17_Hybrid
 SG_ GE_Synchro_Zeit : 24|8@1+ (20,0) [0|5080] "Unit_MilliSecon"  Motor_EDC17_Pirol,Motor_MED17_Hybrid
 SG_ GE_Mom_Begr_Gradient : 32|8@1+ (10,0) [0|2540] "Unit_NewtoMeterPerSecon"  Motor_EDC17_Pirol,Motor_MED17_Hybrid
 SG_ GE_Anheb_Solldrehz_Leerlauf : 40|8@1+ (10,0) [0|2540] "Unit_MinutInver"  Motor_EDC17_Pirol,Motor_MED17_Hybrid
 SG_ GE_Vorsteuermoment : 48|9@1+ (1,0) [0|509] ""  Motor_EDC17_Pirol,Motor_MED17_Hybrid
 SG_ GE_Drehzahlmesser_Daempfung : 58|1@1+ (1,0) [0|1] ""  Motor_EDC17_Pirol,Motor_MED17_Hybrid
 SG_ GE_Schubabschalt_Unt : 59|1@1+ (1,0) [0|1] ""  Motor_EDC17_Pirol,Motor_MED17_Hybrid
 SG_ GE_Freigabe_Synchro : 60|1@1+ (1,0) [0|1] ""  Motor_EDC17_Pirol,Motor_MED17_Hybrid
 SG_ GE_HYB_DZ_Eingriff : 61|2@1+ (1,0) [0|3] ""  Motor_MED17_Hybrid

BO_ 258 Getriebe_03_VW: 8 Getriebe_Derivate
 SG_ GE_Waehlhebel : 44|4@1+ (1,0) [0|15] ""  Motor_EDC17_Pirol,GW_Routing_Derivate,PSM_Ant_Derivate,Motor_MED17_Hybrid
 SG_ GE_StartStopp_Info : 28|2@1+ (1,0) [0|3] ""  Motor_EDC17_Pirol,GW_Routing_Derivate,PSM_Ant_Derivate,Motor_MED17_Hybrid
 SG_ Getriebe_03_CHK : 0|8@1+ (1,0) [0|255] ""  Motor_EDC17_Pirol,PSM_Ant_Derivate,GW_Routing_Derivate,Motor_MED17_Hybrid
 SG_ Getriebe_03_BZ : 8|4@1+ (1,0) [0|15] ""  Motor_EDC17_Pirol,PSM_Ant_Derivate,GW_Routing_Derivate,Motor_MED17_Hybrid
 SG_ GE_Freig_Langfr_Schutzmom : 12|1@1+ (1,0) [0|1] ""  Motor_EDC17_Pirol,PSM_Ant_Derivate,GW_Routing_Derivate,Motor_MED17_Hybrid
 SG_ GE_Uefkt : 14|10@1+ (0.1,0) [0|102.2] ""  Motor_EDC17_Pirol,PSM_Ant_Derivate,GW_Routing_Derivate,Motor_MED17_Hybrid
 SG_ GE_Zielgang : 24|4@1+ (1,0) [0|15] ""  Motor_EDC17_Pirol,PSM_Ant_Derivate,GW_Routing_Derivate,Motor_MED17_Hybrid
 SG_ GE_Langfr_Schutzmom : 32|10@1+ (1,0) [0|1021] ""  Motor_EDC17_Pirol,PSM_Ant_Derivate,GW_Routing_Derivate,Motor_MED17_Hybrid
 SG_ GE_reserv_Waehlhebel : 43|1@1+ (1,0) [0|1] ""  PSM_Ant_Derivate,GW_Routing_Derivate
 SG_ GE_Eingangsdrehz : 48|14@1+ (1,0) [0|16381] "Unit_MinutInver"  Motor_EDC17_Pirol,PSM_Ant_Derivate,GW_Routing_Derivate,Motor_MED17_Hybrid
 SG_ GE_Notlauf : 62|1@1+ (1,0) [0|1] ""  Motor_EDC17_Pirol,PSM_Ant_Derivate,GW_Routing_Derivate,Motor_MED17_Hybrid
 SG_ GE_Codierung_MSG : 63|1@1+ (1,0) [0|1] ""  PSM_Ant_Derivate,GW_Routing_Derivate

BO_TX_BU_ 488 : Motor_EDC17_Pirol,Motor_MED17_Hybrid;
BO_TX_BU_ 2616986625 : Motor_EDC17_Pirol,Motor_MED17_Hybrid;

CM_ "Version 7.2 Release (G1 II)";
CM_ BU_ Sound_A "Soundaktuator (Außen)";
CM_ BU_ Ladegeraet_PAG_PF "Ladegerät PAG";
CM_ BU_ Motor_EDC17_Pirol "Motor EDC17 Pirol";
CM_ BU_ PSM_Ant_Derivate "Porsche Stability Management Hybrid";
CM_ BU_ GW_Routing_Derivate "Gateway Routing (Derivate)";
CM_ BU_ GW_Applikation_Derivate "Gateway Applikation (Derivate)";
CM_ BU_ BMS_Hybrid "Batteriemanagementsystem Hybrid  (Einsatz nur im Hybrid)";
CM_ BU_ Getriebe_Derivate "Getriebe Aisin 8-Gang";
CM_ BU_ LEH_Hybrid "Leistungselektronik Hybrid  (Einsatz nur im Hybrid)";
CM_ BU_ Motor_MED17_Hybrid "Motor MED17 Hybrid";
CM_ BU_ Sound_I "Soundaktuator (Innen)";
CM_ BU_ Tool "Tool";
CM_ BU_ Airbag "Airbag Steuergerät";
CM_ BU_ Waehlhebel "Wählhebel";
CM_ BO_ 3221225472 "This is a message for not used signals, created by Vector CANdb++ DBC OLE DB Provider.";
CM_ SG_ 3221225472 KBI_Trip_E_Std "Trip-Daten(seit): Stunden
";
CM_ SG_ 3221225472 KBI_Trip_E_Min "Trip-Daten(seit): Minuten
";
CM_ SG_ 3221225472 KBI_Service_km "Anzeige der verbleibenden km bis zum nächsten Service
";
CM_ SG_ 3221225472 KBI_Service_Zeit "Anzeige der verbleibenden Zeit bis zum nächsten Service
";
CM_ SG_ 3221225472 KBI_Service_Typ "Anzeige, ob nächster Service eine Zwischen-, Hauptwartung oder ein Ölservice ist
";
CM_ SG_ 3221225472 Mo_HVEM_HV_Abschaltanf "Maximale vom MSG freigegebene Leistung für alle HV-Komfortverbraucher.
(ausgenommen DC/DC-Wandler).";
CM_ SG_ 3221225472 MO_HVEM_HV_Maxleistung "Maximale vom MSG freigegebene Leistung für alle HV-Komfortverbraucher.
(ausgenommen DC/DC-Wandler).";
CM_ SG_ 3221225472 HVEM_Istleistung_Nebenverbrauch "Istleistung der HV-Nebenverbraucher";
CM_ SG_ 3221225472 BMS_TauKuehlmittel__Temp_ "Zeitkonstante Tau Kühlmittel zur Bestimmung der Soll-Vorlauftemperatur als Integral über diese Zeit.";
CM_ SG_ 3221225472 SVB_IVB_FS_Fond "Sollverbau Verdeck SG
";
CM_ SG_ 3221225472 SVB_IVB_FS "Sollverbau Verdeck SG
";
CM_ SG_ 3221225472 SVB_IVB_BFS_Fond "Sollverbau Verdeck SG
";
CM_ SG_ 3221225472 SVB_IVB_BFS "Sollverbau Verdeck SG
";
CM_ SG_ 3221225472 SVB_KameraLow_FLA "Sollverbau Kamera Low";
CM_ SG_ 3221225472 AWV_Halten "Anforderung an das ESP, das Fahrzeug nach erfolgter automatischer Bremsung bis in den Stillstand im Stillstand zu halten und eine Fahrer-Überwachung zu aktivieren.";
CM_ SG_ 3221225472 NMH_GW_VNSM_VC5 "NMH Gateway Byte 6 
VC5, Komfort bus activation from diagnostic command";
CM_ SG_ 3221225472 NMH_GW_VNSM_Wfpf "NMH Gateway Byte 6 
VNSM, Weckfortpflanzung VNSM (general)
GW wakes bus due to WFP (e.g. from Komfort, MMI, ...)";
CM_ SG_ 305 MO_ePowermeter "Anzeige ePowermeter (Fahrreserve elektrisch bis Start Verbrennungsmotor (Verbrenner startet bei 100%))";
CM_ SG_ 305 MO_W_Reku_normiert_ueberlauf "Motorsteuergeräteinterner Rekuperationszähler, der vom Kombi ausgewertet wird, um die Rekuperierte Arbeit/Leistung zu erfassen.";
CM_ SG_ 305 Ladezustand "Ladezustand der Batterie
";
CM_ SG_ 305 Enrgfluss_State "Energiefluss zwischen den Achsen, Batterie, Elektromotor und Verbrennungsmotor";
CM_ SG_ 305 MO_W_Reku_normiert "Motorsteuergeräteinterner Rekuperationszähler, der vom Kombi ausgewertet wird, um die Rekuperierte Arbeit/Leistung zu erfassen.";
CM_ SG_ 305 MO_Powermeter "Anzeigewerte im Kombi
0       = Unteres Ende Bremsen/grau;
340   = Unteres Ende CHARGE;
1020 = READY;
1870 = Oberes Ende EFFICIENCY;
3400 = 100%;
4080 = MAX;";
CM_ SG_ 914 ESP_07_CHK "Berechnung siehe Lastenheft 'Kommunikationsabsicherung für FlexRay und CAN'
Endwerte siehe 'Kommunikationsabsicherung für FlexRay und CAN / Anhang C: Tabelle S-PDU Kennungen'";
CM_ SG_ 914 ESP_OBD_Status "Dieses Bit steuert die MIL-Lampe an (Motorsteuergerät reicht diese Info an Kombi weiter).";
CM_ SG_ 914 OBD_Fehler_Radsensor_VR "Für Motor-SG (gesetzliche Vorgabe)";
CM_ SG_ 914 OBD_Fehler_Radsensor_VL "Für Motor-SG (gesetzliche Vorgabe)";
CM_ SG_ 914 OBD_Fehler_Radsensor_HR "Für Motor-SG (gesetzliche Vorgabe)";
CM_ SG_ 914 OBD_Fehler_Radsensor_HL "Für Motor-SG (gesetzliche Vorgabe)";
CM_ SG_ 906 KL_Sportmodus "Sportmodus";
CM_ SG_ 906 KL_T_PSM_off "PSM-Off Taster (Anforderung ESP passiv schalten)";
CM_ SG_ 906 F_Klima_08_PAG_Fwk "Ungueltige Signale: KL_Sportmodus,KL_T_Lift,KL_T_PASM_1,KL_T_PASM_2, KL_T_PASM_3, KL_St_FSM, KL_Niv_up, KL_Niv_down, KL_T_Sport, KL_T_PSM_Off, KL_T_Range, KL_T_Sperre, KL_Atemp_ungef, KL_T_HDC,KL_T_Abgasklappe




";
CM_ SG_ 906 F_Klima_03_Ant "Ungueltige Signale: KL_Magnetventil,KL_STH_aktiv,KL_STH_Ansteuerung";
CM_ SG_ 906 ESP_Rollenmodus "Rollenmodus aktiv, Fzg auf Rollenpruefstand
";
CM_ SG_ 906 KL_T_Abgasklappe "Taster Sportabgasklappenanlage";
CM_ SG_ 906 KL_Magnetventil "Wasserventil zum Waermetauscher geoeffnet/geschlossen";
CM_ SG_ 906 F_ESP_11_Ant "Ungueltige Signale: ESP_Rollenmodus";
CM_ BO_ 1731 "200ms";
CM_ SG_ 1731 NMH_ESP_Start_1 "Zustand Start (<--Sleep)";
CM_ SG_ 1731 NMH_ESP_Start_2 "Zustand Start (<--Prepare to Sleep)";
CM_ SG_ 1731 NMH_ESP_Normal_Mode_1 "Zustand Normal Mode (<-- Start)";
CM_ SG_ 1731 NMH_ESP_Normal_Mode_2 "Zustand Normal Mode (<-- Ready to Sleep)";
CM_ SG_ 1731 NMH_ESP_Car_WakeUp "Car WakeUp (optional), wird vom ESP nicht gesendet";
CM_ SG_ 1731 NMH_ESP_Per_WakeUp "Weckurasche Peripherie
";
CM_ SG_ 1731 NMH_ESP_Fkt_WakeUp "Weckursache Funktion
";
CM_ SG_ 1731 NMH_ESP_NM_aktiv_Klemme_15 "Kl.15 EIN (Nachlaufursache, nicht 'Ready To Sleep')";
CM_ SG_ 1731 NMH_ESP_NM_aktiv_Diagnose "Diagnose bei Kl 15 aus (Nachlaufursache, nicht 'Ready To Sleep')";
CM_ SG_ 1731 NMH_ESP_NM_aktiv_Start "Mindestaktivzeit Zustand 'Start' (Nachlaufursache, nicht 'Ready To Sleep')";
CM_ SG_ 1731 NMH_ESP_NM_aktiv_v_groesser_Null "v>0 (wird im Initfall mit 1 gesendet, da die Drehzahlfuehler erst nach ca. 1,1s diagnostizierbar ist --> aus Sicherheitsgruenden wird von v>0 in diesem Fall ausgegangen)
(Nachlaufursache, nicht 'Ready To Sleep')";
CM_ SG_ 1731 NMH_ESP_Mindestaktivzeit "Mindestaktivzeit ESP (ca. 1,1s --> Diagnose Drehzahlfuehler)
(Nachlaufursache, nicht 'Ready To Sleep')";
CM_ SG_ 1731 NMH_ESP_kein_NL "kein lokaler / SG interner Nachlauf vor Wakeup";
CM_ SG_ 1731 NMH_ESP_NL_Daten_EEPROM "EEPROM Datenspeicherung (kein lokaler / SG interner Nachlauf vor Wakeup)";
CM_ SG_ 1731 NMH_ESP_TimeOut_Fehler "Aktiver Timeout Fehlerspeichereintrag";
CM_ SG_ 1731 NMH_ESP_CAN_Diag_deaktiv "CAN Bus bezogene Eigendiagnose deaktiviert (Überspannung, Unterspannung, Hochlaufphase, ...) ";
CM_ SG_ 1731 NMH_ESP_KompSchutz "Funktionseinschränung aufgrund Komponentenschutz aktiv";
CM_ SG_ 1731 NMH_ESP_Mute_Mode "Funktionseinschränung aufgrund Mute Mode aktiv, nur VW";
CM_ SG_ 1731 NMH_ESP_Transport_Mode "Funktionseinschränung aufgrund Transport Mode aktiv";
CM_ SG_ 1731 NMH_ESP_Abschaltstufe_aktiv "Funktionsabschaltung wegen Abschaltschaltstufe";
CM_ SG_ 1731 NMH_ESP_Eindraht_Fehler "Erkennung Eindrahtfehler";
CM_ SG_ 1731 NMH_ESP_interne_Zust "interne ESP-Systemzustände";
CM_ SG_ 1731 NMH_ESP_Lokalaktiv "Zeigt an ob das SG nach Klemme15 AUS und nach entsprechender MAX Aktivzeit noch aktiv war";
CM_ SG_ 1731 NMH_ESP_Subsystemaktiv "Zeigt an ob ein Subsystem des SGs nach Klemme15 AUS und nach entsprechender MAX Aktivzeit noch aktiv war";
CM_ SG_ 946 BEM_NV_NachladAnf "Bei Energiedefizit auf der Niedervoltseite wird der Lademanager aufgefordert, die Niedervoltseite nachzuladen.";
CM_ SG_ 946 BEM_Freigabe_HV_Ladung "Signalisierung, dass ein Aufladen der HV-Batterie aus der 12V-Seite heraus möglich ist.
Prämissen: 
Ladegerät an 12V-Seite oder
guter Ladezustand der 12V-Batterie";
CM_ SG_ 946 BEM_HYB_DC_uMinLV "Abregelgrenze: minimal erlaubte Bordnetzspannung im Hochsetzbetrieb";
CM_ SG_ 946 BEM_HYB_DC_uSollLV "Sollwert für die Bordnetzspannung im Tiefsetzbetrieb vom Traktionsnetz ins Bordnetz";
CM_ SG_ 1628 BMS_IstSpannung_HV "HV Spannungswert";
CM_ SG_ 1628 BMS_Temperatur_Ansaugluft "Temperature of inlet air / Momentanwert: Ansauglufttemperatur der Batteriekühlung";
CM_ SG_ 1628 BMS_Temperatur "battery temperature / Momentanwert: Temperatur der Traktionsbatterie";
CM_ SG_ 1628 BMS_HYB_Spuelbetrieb_Status "Status Betriebsart der Batterielüftung (Umluft-/Spülbetrieb)";
CM_ SG_ 1628 BMS_HYB_Temp_vor_Verd "Lufttemperatur im Klimagerät BMS vor Verdampfer";
CM_ SG_ 1628 BMS_HYB_Temp_nach_Verd "Lufttemperatur im Klimagerät BMS nach Verdampfer";
CM_ SG_ 1628 BMS_HYB_Kuehlung_Anf "Anforderung für aktive Batteriekühlung in vier Stufen:
Stufe 0: keine Kühlanforderung
Stufe 1: 10 °C Verdampfertemperatur Klima
Stufe 2: 3 °C Verdampfertemperatur Klima
Stufe 3: maximale Kühlleistung Klima";
CM_ SG_ 1628 BMS_HYB_ASV_vorne_Status "Status Absperrventil des Kältemittelkreislaufs zur Innenraumklimatisierung";
CM_ SG_ 1628 BMS_HYB_ASV_hinten_Status "Status Absperrventil des Kältemittelkreislaufs zur Batteriekühlung";
CM_ SG_ 1628 BMS_HYB_KD_Fehler "Bei gesetztem Bit ist mindestens ein Kundendienstfehler eingetragen";
CM_ SG_ 1628 BMS_HYB_BattFanSpd "Relativwert der Batterielüfter-Ansteuerung bezogen auf Maximalwert";
CM_ SG_ 1628 BMS_HYB_VentilationReq "BMS fordert bei Climatronic die Öffnung der Umluftklappe an";
CM_ BO_ 490 "CCP in Serie mit 11Bit - Sendekanal";
CM_ BO_ 488 "CCP in Serie mit 11Bit - Sendekanal";
CM_ SG_ 945 DC_TiefsetzBereit "Kennzeichnung, dass der DC/DC-Wandler im Sollmodus Tiefsetzbetrieb ist und auf Spannungsvorgabe wartet. Fehler werden über das Signal DC_HYB_Fehler_intern signalisiert.";
CM_ SG_ 945 DC_HYB_iAktLV "Momentanwert: Strom vom DC/DC-Wandler in das Bordnetz";
CM_ SG_ 945 DC_HYB_iAktReserveLV "Momentanwert: Stromreserve vom DC/DC-Wandler in Richtung 12V-Bordnetz";
CM_ SG_ 945 DC_HYB_uAktLV "Momentanwert: NV-Bordnetzspannung am DC/DC-Wandler";
CM_ SG_ 945 DC_HYB_LangsRegelung "aktueller Regelmode des DC/DC-Wandlers.
1: langsame Regelung
0: normale Regelung";
CM_ SG_ 945 DC_HYB_Abregelung_Temperatur "Abregelung aufgrund Übertemperatur im Leistungsteil (Hochtemperatur-Abregelung)";
CM_ SG_ 945 DC_HYB_Fehler_RedLeistung "Fehler: eingeschränkte Leistungsfähigkeit des DC/DC-Wandlers aufgrund eines internen Fehlers";
CM_ SG_ 945 DC_HYB_Fehler_intern "Fehler: DC/DC-Wandler ist aufgrund eines internen Hardware-Fehlers abgeschaltet";
CM_ SG_ 945 DC_HYB_Fehler_Spannung "Abschaltung aufgrund Unter-/Überspannung auf der Ein-/Ausgangsseite";
CM_ SG_ 945 DC_Verbrauch_Ueberlauf "Überlauf-Bit für das Signal DC_Verbrauch";
CM_ SG_ 945 DC_Verbrauch "Energieverbrauch vom DCDC für Versorgung 12V-Bordnetz inkl. seines eigenen Wirkungsgrads (bspw.: HV_Strom*HV_Spannung*t)";
CM_ SG_ 945 DC_HYB_Auslastungsgrad "Momentanwert: Auslastung DC/DC (DFM Signal), entspricht I_akt / I_max
(Vorhalt für MQB)";
CM_ SG_ 1627 EM_HYB_KD_Fehler "Bei gesetztem Bit ist mindestens ein Kundendienstfehler eingetragen";
CM_ SG_ 256 ESP_v_Signal "Geschwindigkeitssignal vom PSM. Mittelwert der angetriebenen Räder.
";
CM_ SG_ 256 ESP_01_CHK "Berechnung siehe Lastenheft 'Kommunikationsabsicherung für FlexRay und CAN'
Endwerte siehe 'Kommunikationsabsicherung für FlexRay und CAN / Anhang C: Tabelle S-PDU Kennungen'";
CM_ SG_ 256 ASR_Moment_langsam "Achtung:
Einheitenloser CAN-Wert.
Faktor in MO_Faktor_Momente in Motor_Code_01 beachten!

Langsame reduzierende (ASR) Momentenanforderung an der Motor";
CM_ SG_ 256 ASR_MSR_Moment_schnell "Achtung:
Einheitenloser CAN-Wert.
Faktor in MO_Faktor_Momente in Motor_Code_01 beachten!

Schnelle reduzierende (ASR) oder erhöhende (MSR) Momentanforderung an den Motor, Eingriffsart wird über das Signal 'ASR_MSR_Eingriffsart' qualifiziert";
CM_ SG_ 256 ASR_Tastung_passiv "ASR passiv getastet.
AUDI B8 front: Ab 70km/h wird das Bit automatisiert zurückgesetzt.
AUDI B8 quattro: Ab 70km/h wird das Bit automatisiert zurückgesetzt, ab 50km/h wieder zugeschalten.

Im B8 gilt die Funktionsspezifikation: LAH 8K0614D_V1.0.pdf - ";
CM_ SG_ 256 ESP_Tastung_passiv "ESP passiv getastet

Im B8 gilt die Funktionsspezifikation: LAH 8K0614D_V1.0.pdf - Passivtasterkonzept";
CM_ SG_ 256 ESP_Systemstatus "Fehler steht für Stillegung ESP mit Fehlereintrag.
AUDI B8: Flag wird bei Unterspannung im Stand bis einmalig 6km/h überschritten wurden nicht gesetzt (Ausblendung Startvorgang)";
CM_ SG_ 256 ASR_Schalteingriff "Wunsch an das Getriebe während einer ASR Regelung, bei Audi nur 0x0 und 0x1 genutzt

";
CM_ SG_ 256 OBD_Schlechtweg "Für Ausblendung der Zündaussetzererkennung im Motorsteuergerät (Otto). Bit wird gesetzt, wenn Rad-Drehbeschleunigung im ESP > Grenzwert ist. Vorteil gegenüber Radgeschwindigkeiten, dass ESP alle 2 ms dynamisch die Rad-Drehbeschleunigung errechnet und dem ";
CM_ SG_ 256 ESP_QBit_v_Signal "Geschwindigkeit wird vom ESP aus Ersatzwerten errechnet, wenn Bit gesetzt ist. Güte des Signals ist verändert.

Im B8 gilt die Signalspezifikation: LAH 8K0907AG_V1.3.pdf - Geschwindigkeitausgabe BOSCH ESP ";
CM_ SG_ 256 ABS_Bremsung "Antiblockiersystem, Bit zeigt auch Druckabbau an (z.B. ESP hat zuviel Druck aufgebaut oder ungebremste Regelung auf Bahnübergang)";
CM_ SG_ 256 ASR_Anf "Die Momentenanforderung 'ASR_MSR_Moment_schnell' und 'ASR_Moment_langsam' sind auszuführen";
CM_ SG_ 256 MSR_Anf "Die Momentenanforderung 'ASR_MSR_Moment_schnell' ist auszuführen.";
CM_ SG_ 256 EBV_Eingriff "Elektronische Bremskraftverteilung, aktueller Eingriff (Druckhalten, Druckabbau), kein ABS / ESP-Eingriff";
CM_ SG_ 256 EDS_Eingriff "Elektronische Differentialsperre";
CM_ SG_ 256 ESP_Eingriff "Eingriff des Fahrdynamikreglers";
CM_ SG_ 256 ESP_ASP "Gilt nicht für PAG G1 Hybrid.
ASP = Anhaenger-Stabilisierungs-Programm";
CM_ SG_ 257 ESP_02_CHK "Berechnung siehe Lastenheft 'Kommunikationsabsicherung für FlexRay und CAN'
Endwerte siehe 'Kommunikationsabsicherung für FlexRay und CAN / Anhang C: Tabelle S-PDU Kennungen'";
CM_ SG_ 257 ESP_QBit_Gierrate "QBit der Giergeschwindigkeit, keine Filterung; ungültiger Wert kann bspw. aufgrund einer Unterspannung oder in der Initialisierungsphase ausgegeben werden.

Im D4 gilt das Dokument: 'Signaldefinition zwischen SARA und ESP im D4'";
CM_ SG_ 257 ESP_QBit_Laengsbeschl "Vorhalt VW / nicht AUDI:
QBit der Längsbeschleunigung

Im D4 gilt das Dokument: 'Signaldefinition zwischen SARA und ESP im D4'";
CM_ SG_ 257 ESP_QBit_Querb "Querbeschleunigung wird vom ESP aus Ersatzwerten errechnet, wenn Bit gesetzt ist. Güte des Signals ist verändert.

AUDI B8: Es wird kein Ersatzwert berechnet

Im D4 gilt das Dokument: 'Signaldefinition zwischen SARA und ESP im D4'";
CM_ SG_ 257 ESP_Stillstandsflag "Bei RB-Projekten wird das Stillstandsflag gesetzt, wenn der absolute Stillstand der Raddrehzahlsensoren erkannt wurde, d.h. kein Zahn bewegt sich mehr. Dieses Bit wird bspw. im MOST für TV-Tuner-Abschaltung Australien verwendet, d.h. leichte Erschütterung";
CM_ SG_ 257 ESP_Querbeschleunigung "In ESP-Projekten bspw. ContiTEVES und RB wird ein Sensor-Cluster verwendet, welcher den gemessenen Sensorwert ausgibt. 0xFF bedeutet hier die Größe kann nicht errechnet werden.

Im D4 erfolgt die Bereitstellung der Sensorwerte durch SARA-SG!";
CM_ SG_ 257 ESP_Laengsbeschl "Sensorwert Längsbeschleunigung vom Sensorcluster
Im D4 erfolgt die Bereitstellung der Sensorwerte durch SARA-SG!";
CM_ SG_ 257 ESP_Verteil_Wankmom "Gilt nicht für PAG G1 Hybrid.
Anforderung einer Wankmomentenverteilung an CDC (Exklusivnutzung!)";
CM_ SG_ 257 ESP_QBit_Anf_Vert_Wank "Gilt nicht für PAG G1 Hybrid.
QBit der Wankmomentenverteilung";
CM_ SG_ 257 ESP_Gierrate "Winkelgeschwindigkeit um die z-Achse

MLB: gemessener Wert
tatsächliche Auflösung Bosch ESP: 0,27 Grad/s";
CM_ SG_ 257 ESP_VZ_Gierrate "Vorzeichen der Gierrate";
CM_ SG_ 257 ESP_Notbremsanzeige "Im B8 gilt das Lastenheft Adaptives Bremslicht V18.0.doc

Im D4 gilt das Konzern-Funktions-LAH 'Notbremsanzeige Spezifikation V3.0 070620.doc'. In Pata0 setzt das ESP das NBA-Bit generell bei Vorliegen der definierten Eintrittsbedingungen (in Pata1 wird";
CM_ SG_ 257 ESP_SpannungsAnf "Die Rekuperation kann mit der Anforderung einer höheren Spannung eingeschränkt werden.";
CM_ BO_ 482 "CCP in Serie mit 11Bit - Empfangskanal";
CM_ SG_ 259 ESP_03_CHK "Berechnung siehe Lastenheft 'Kommunikationsabsicherung für FlexRay und CAN'
Endwerte siehe 'Kommunikationsabsicherung für FlexRay und CAN / Anhang C: Tabelle S-PDU Kennungen'";
CM_ SG_ 259 ESP_VL_FR "Fahrtrichtungserkennung Rad Vorne Links

Im B8 gilt die Signalspezifikation: LAH 8K0907AG_V1.3.pdf - Geschwindigkeitausgabe BOSCH ESP

Im D4 gilt die Spezifikation v-Signal im D4 v1.1";
CM_ SG_ 259 ESP_VR_FR "Fahrtrichtungserkennung Rad Vorne Rechts

Im B8 gilt die Signalspezifikation: LAH 8K0907AG_V1.3.pdf - Geschwindigkeitausgabe BOSCH ESP

Im D4 gilt die Spezifikation v-Signal im D4 v1.1";
CM_ SG_ 259 ESP_HL_FR "Fahrtrichtungserkennung Rad Hinten Links

Im B8 gilt die Signalspezifikation: LAH 8K0907AG_V1.3.pdf - Geschwindigkeitausgabe BOSCH ESP

Im D4 gilt die Spezifikation v-Signal im D4 v1.1";
CM_ SG_ 259 ESP_HR_FR "Fahrtrichtungserkennung Rad Hinten Rechts

Im B8 gilt die Signalspezifikation: LAH 8K0907AG_V1.3.pdf - Geschwindigkeitausgabe BOSCH ESP

Im D4 gilt die Spezifikation v-Signal im D4 v1.1";
CM_ SG_ 259 ESP_VL_Radgeschw "Im B8 gilt die Signalspezifikation: LAH 8K0907AG_V1.3.pdf - Geschwindigkeitausgabe BOSCH ESP

Im D4 gilt die Spezifikation v-Signal im D4 v1.1";
CM_ SG_ 259 ESP_VR_Radgeschw "Im B8 gilt die Signalspezifikation: LAH 8K0907AG_V1.3.pdf - Geschwindigkeitausgabe BOSCH ESP

Im D4 gilt die Spezifikation v-Signal im D4 v1.1";
CM_ SG_ 259 ESP_HL_Radgeschw "Im B8 gilt die Signalspezifikation: LAH 8K0907AG_V1.3.pdf - Geschwindigkeitausgabe BOSCH ESP

Im D4 gilt die Spezifikation v-Signal im D4 v1.1";
CM_ SG_ 259 ESP_HR_Radgeschw "Im B8 gilt die Signalspezifikation: LAH 8K0907AG_V1.3.pdf - Geschwindigkeitausgabe BOSCH ESP

Im D4 gilt die Spezifikation v-Signal im D4 v1.1";
CM_ SG_ 776 ESP_HDC_FktLampe "Funktionslampe Bergabfahrassistent.
(Sender blinkt mit dem Bit 3,3Hz)";
CM_ SG_ 776 ESP_ASR_Lampe "Signal wir nur im B8/Q5 verwendet um den Fehlerzustand des ESPs darzustellen.
In allen nachfolge Projekten werden für diese Funktion die alten Signale verwendet und dieses Signal ist ungültig. 

ESP_ASR_Lampe == 0
kein Stabilisierungseingriff, kein Fe";
CM_ SG_ 776 ESP_Meldungen "Gilt nicht für PAG G1 Hybrid (Kombischittstelle über CAN Fwk wie G1 Basisfzg.)
ESP sendet im Hinweis- /Störungsfall an das Kombi Informationen zum Anzeigen (Text + Akustik)";
CM_ SG_ 776 ESP_Lampe "Zustand der Fahrdynamikregelungslampe (ASR und/oder ESP)

Im B8 gilt LAH 8T0.907.B.pdf - Warn-Anzeigekonzept Bremssysteme

Im D4 gilt die Spezifikation Warn-Anzeige-LH D4";
CM_ SG_ 776 ABS_Lampe "Sicherheitswarnlampe

Im B8 gilt LAH 8T0.907.B.pdf - Warn-Anzeigekonzept Bremssysteme

Im D4 gilt die Spezifikation Warn-Anzeige-LH D4";
CM_ SG_ 776 BK_Lampe "Rote Lampe wird angesteuert, bspw. bei EBV-Ausfall; Sicherheitswarnlampe im Audi C6/D3/AU716. (Blinktakt wird wie bisher vom Kombi generiert). Separate Bremskontroll-Lampe (Audi ab D3/C6) wird als Sicherheitswarnlampe aufgeprüft (Initwert 1); Kombinierte ";
CM_ SG_ 776 ESP_Akustik "Gilt nicht für PAG G1 Hybrid (Kombischittstelle über CAN Fwk wie G1 Basisfzg.)
Akustik der Fahrdynamikregelung im Kombiinstrument";
CM_ SG_ 776 ESP_Diagnose "Nach Diagnoseende wird ein SW-Reset ausgelöst welcher einen Kommunikatiosausfall für max. 150ms verursacht. Dies ist bei SG mit verschärfter Timeoutüberwachung (nicht nach Konzern-LH) zu beachten.";
CM_ SG_ 776 ESP_Textanzeigen_02 "Gilt nicht für PAG G1 Hybrid (Kombischittstelle über CAN Fwk wie G1 Basisfzg.)
Textanzeigen der Fahrdynamikregelung im Kombiinstrument";
CM_ SG_ 776 ESP_Off_Lampe "Bit zur Ansteuerung der separaten ESP-off-Lampe im Kombi (Gesetzesforderung USA)";
CM_ SG_ 776 ESP_m_Raddrehz "Exklusiver Empfänger ist das Kombiinstrument! Radumdrehungen pro Sekunde sind Eingangsgröße für die Geschwindigkeitsberechnung im Kombi. Aus dieser Raddrehzahl und dem Radumfang wird die Fahrzeuggeschwindigkeit errechnet.

Im B8 gilt die Signalspezifika";
CM_ SG_ 776 ESP_Wegimp_VA "Die Wegimpulse Vorderachse sind die gemittelten Werte (reine mathematische Operation: Addition und Division durch zwei, keine Filterung) der Wegimpulse der Ränder VL und VR.

Im B8 gilt die Signalspezifikation: LAH 8K0907AG_V1.3.pdf - Geschwindigkeitaus";
CM_ SG_ 776 ESP_Fehlerstatus_Wegimp "Fehler wird gesetzt, wenn beide ESP-Drehzahlfühler an der Vorderachse defekt sind.

Im B8 gilt die Signalspezifikation: LAH 8K0907AG_V1.3.pdf - Geschwindigkeitausgabe BOSCH ESP

Im D4 gilt die Spezifikation v-Signal im D4 v1.1";
CM_ SG_ 776 ESP_Wegimp_Ueberlauf "Der Wegimpulszähler ist mindestens einmal übergelaufen

Im B8 gilt die Signalspezifikation: LAH 8K0907AG_V1.3.pdf - Geschwindigkeitausgabe BOSCH ESP

Im D4 gilt die Spezifikation v-Signal im D4 v1.1";
CM_ SG_ 776 ESP_QBit_Wegimp_VA "Im B8 gilt die Signalspezifikation: LAH 8K0907AG_V1.3.pdf - Geschwindigkeitausgabe BOSCH ESP

Im D4 gilt die Spezifikation v-Signal im D4 v1.1";
CM_ SG_ 776 ESP_Displaywarnungen "Prio1-Warnungen
Automatisch gekoppelt an diese Bremsenwarnung ist ein dreimaliger Warnton, der durch das Kombi selbstständig angesteuert wird, sobald eines der belegten Bits gesetzt ist.

0x2 - 0x3 = tbd.

Im B8 gilt LAH 8T0.907.B.pdf - Warn-Anzeigek";
CM_ SG_ 776 ESP_HDC_Regelgeschw "Gilt nicht für PAG G1 Hybrid (Kombischittstelle über CAN Fwk wie G1 Basisfzg.)
HDC-Geschwindigkeit
Dient der Anzeige der HDC-Geschwindigkeit und eines Bergabfahrsymbols im Kombi.";
CM_ SG_ 776 ESP_BKV_Warnung "ESP sendet im Hinweis- /Störungsfall an das Kombi Informationen zum Anzeigen (Text + Akustik)

- der Signalwert 1 wurde aus dem Signal ESP_Textanzeigen_02 (Wert 0xA) extrahiert und soll 
zukünftig über dieses Signal angezeigt werden  (ESP kann dadurch ";
CM_ SG_ 776 ESP_Zaehnezahl "Konstanter Wert der Zähnezahl des verwendeten Impulsrades wird ausgegeben, jeder Empfänger der Wegimpulse muss die Zähnezahl einlesen, um eine volle Umdrehung des Rades zu erkennen. 

Im B8 gilt die Signalspezifikation: LAH 8K0907AG_V1.3.pdf - Geschwind";
CM_ SG_ 262 ESP_Status_Anfahrhilfe "Funktionsstatus des Berganfahrassistenten
MQB: Auswertung im Getriebe zwecks Standabkopplung";
CM_ SG_ 262 ESP_Anforderung_EPB "ESP fordert von der EPB Öffnen bzw. Schliessen an. Notwendig wegen Hillholder-Funktion im ESP.
";
CM_ SG_ 262 ESP_Lenkeingriff_ADS "Gilt nicht für PAG G1 Hybrid.
Im Falle eines fahrzeugstabilisierenden Lenkeingriffs des ADS-Systems soll ACC/GRA deaktiviert werden.";
CM_ SG_ 262 ESP_Bremsruck_AWV2 "Das Signal dient als Rückmeldung zum ACC, dass ein angeforderter AWV2-Bremsruck durchgeführt wird. Die positive Rückmeldung löst u.a. eine entsprechende Fahrerinformation im Kombiinstrument aus";
CM_ SG_ 262 ESP_Konsistenz_AWV2 "Rückmeldung zum Sender einer AWV-Anforderung (ACC-Steuergerät) bezüglich Prüfung der Checksumme, des Botschaftszählers, des langen Timeout und DLC.
";
CM_ SG_ 262 ESP_05_CHK "Berechnung siehe Lastenheft 'Kommunikationsabsicherung für FlexRay und CAN'
Endwerte siehe 'Kommunikationsabsicherung für FlexRay und CAN / Anhang C: Tabelle S-PDU Kennungen'";
CM_ SG_ 262 ESP_QBit_Bremsdruck "QBit des Bremsdrucks";
CM_ SG_ 262 ESP_QBit_Fahrer_bremst "Gültigkeit der redundanten Bremspedalinformation vom ESP SG

0x1 = eingeschränkte Signalgüte

Im B8 gilt die Signalspezifikation LAH8K0907AF: 05-08-23_Lastenheft_Bremslichtinfo_B8_V6.4_yellow.pdf - Bremslichtinfo

Im D4 gilt die Signalspezifikation ";
CM_ SG_ 262 ESP_Schwelle_Unterdruck "Gilt nicht für PAG G1 Hybrid.
Vorhalt VW für HBV-Projekte";
CM_ SG_ 262 ESP_Bremsdruck "Bremsdruck / Vordruck durch Fahrervorgabe (Pvor). Bei aktivem Druckaufbau (Stabilisierungseingriffe) kein Pvor
";
CM_ SG_ 262 ESP_Fahrer_bremst "Bit gibt die Information aus, ob der Fahrer gebremst hat oder nicht. Redundante Bremsinformation vom ESP, wird bei Audi im B8 bedient!

Schwelle außerhalb Regelung 12bar, in Regelung 30bar

Im B8 gilt die Signalspezifikation LAH8K0907AF: 05-08-23_Last";
CM_ SG_ 262 ESP_Verz_TSK_aktiv "Rückmeldeinformation an den Triebsstrangkoordinator/ACC, dass die ECD-Verzögerungsanforderung aktuell umgesetzt wird";
CM_ SG_ 262 ESP_Konsistenz_TSK "Rückmeldung zum Sender einer Verzögerungsanforderung (Triebstrangskoordinator) bezüglich Prüfung der Checksumme, des Botschaftszählers, des langen Timeout und DLC. Wird auch gesetzt bei Verzögerungsanforderung größer einer applizierbaren Schwelle.
";
CM_ SG_ 262 ECD_Fehler "ESP kann die Verzögerungsregelung/Bremsenregelung aufgrund eines internen Fehlers nicht ausführen, mit Fehlereintrag im ESP.
";
CM_ SG_ 262 ECD_nicht_verfuegbar "ESP kann die Verzögerungsregelung/Bremsenregelung temporär nicht ausführen (z.B. Netzwerkmanagement-Betriebe - KL15 Aus; v<18km/h; ESP in Diagnose, ...), ohne Fehlereintrag im ESP.

";
CM_ SG_ 262 ESP_Status_Bremsentemp "ECD-Bremsscheibentemperaturmodell. Rückmeldung für Sender einer ECD Verzögerungsanforderung, ohne Fehlereintrag im ESP";
CM_ SG_ 262 ESP_Autohold_Standby "Rückmeldung an EPB, dass der Fahrer die Funktion Autohold mindestens einmal angefordert hat. Im Fall eines ESP-Ausfalles oder einer Übernahmeaufforderung erfolgt die EPB-Zuschaltung nur nach Setzen dieses Bits. Bit wird gesetzt nach Betätigung des Autohol";
CM_ SG_ 262 ESP_HDC_Standby "für Q5 und B8 allroad:
Flag wird vom ESP gesetzt, wenn über den HDC-Taster die HDC-Funktion eingeschalten wurde";
CM_ SG_ 262 ESP_HBA_aktiv "Signal gibt an, ob der hydraulische Bremsassistent im Regler aktiviert wurde";
CM_ SG_ 262 ESP_Prefill_ausgeloest "zeigt, ob die Funktion Prefill (aufgrund Fahrpedalgradient) ausgelöst wird; zeigt keinen Funktionszustand bezüglich Fehlerstilllegung";
CM_ SG_ 262 ESP_Rueckwaertsfahrt_erkannt "nur im Q5: ESP gibt Info, ob Rückwärtsfahrt über internen Algorithmus sicher erkannt";
CM_ SG_ 262 ESP_StartStopp_Info "Stopp-Freigabe und Start-Anforderung an den Start-Stopp-Koordinator";
CM_ SG_ 262 ESP_Eingr_HL "Flag wird vom ESP gesetzt, sobald aufgrund eines ESP-Eingriffs am Rad aktiv Druck aufgebaut wird.
Frühestens mit öffnen des Ventils und spätestens bei einem Bremsmoment von 100Nm. Flag bleibt solange gesetzt wie ein Bremsmoment von mehr als 100Nm anliegt";
CM_ SG_ 262 ESP_Eingr_HR "Flag wird vom ESP gesetzt, sobald aufgrund eines ESP-Eingriffs am Rad aktiv Druck aufgebaut wird.
Frühestens mit öffnen des Ventils und spätestens bei einem Bremsmoment von 100Nm. Flag bleibt solange gesetzt wie ein Bremsmoment von mehr als 100Nm anliegt";
CM_ SG_ 262 ESP_Eingr_VL "Flag wird vom ESP gesetzt, sobald aufgrund eines ESP-Eingriffs am Rad aktiv Druck aufgebaut wird.
Frühestens mit öffnen des Ventils und spätestens bei einem Bremsmoment von 100Nm. Flag bleibt solange gesetzt wie ein Bremsmoment von mehr als 100Nm anliegt";
CM_ SG_ 262 ESP_Eingr_VR "Flag wird vom ESP gesetzt, sobald aufgrund eines ESP-Eingriffs am Rad aktiv Druck aufgebaut wird.
Frühestens mit öffnen des Ventils und spätestens bei einem Bremsmoment von 100Nm. Flag bleibt solange gesetzt wie ein Bremsmoment von mehr als 100Nm anliegt";
CM_ SG_ 262 ESP_BKV_Unterdruck "Der maximale Wert wird auf 1016 mbar begrenzr (Vorhalt für HBV-Projekte VW)";
CM_ SG_ 262 ESP_Autohold_aktiv "Rückmeldung an EPB, dass Autohold aktiv ist. Einführung mit Hillholder-Konzept im B8.";
CM_ SG_ 262 ESP_FStatus_Anfahrhilfe "Bei gesetztem Fehler steht die Hillhold-Funktion nicht zur Verfügung
B8: Bit wird nur im Fehlerfall HHC in VL300-Fzg. gesetzt";
CM_ SG_ 262 ESP_Verz_EPB_aktiv "Bei gesetztem Bit wird die Verzögerungsanforderung von EPB umgesetzt.";
CM_ SG_ 262 ECD_Bremslicht "Bremslichtansteuerung durch ECD-Funktion.
Im B8 gilt die Signalspezifikation LAH8K0907AF: 05-08-23_Lastenheft_Bremslichtinfo_B8_V6.4_yellow.pdf - Bremslichtinfo
(in Gateway_01_VW: Signal wird nur im Panamera H/P bedient)";
CM_ SG_ 262 ESP_Verzoeg_EPB_verf "Bei gesetztem Bit ist der Verzögerungsregeler für EPB verfügbar.";
CM_ SG_ 262 ESP_Status_Bremsdruck "Bei gesetztem Bit liegt p > ca. 2 bar an, hervorgerufen durch Fahrer, ASR, FZR, ECD, Bremsregler ... bei Abfall des Bits ist p < X bar, bei aktivem ECD-Eingriff Ende des Eingriffs 
";
CM_ BO_ 793 "wird im G1P+G1H von MED/EDC nicht verwendet";
CM_ SG_ 793 Fahrwerk_02_CHK "Berechnung siehe Lastenheft 'Kommunikationsabsicherung für FlexRay und CAN'
Endwerte siehe 'Kommunikationsabsicherung für FlexRay und CAN / Anhang C: Tabelle S-PDU Kennungen'";
CM_ SG_ 793 FA_MSG_Einschraenkung "Eingriff im Motor-SG (z.B.: v-Begrenzung im Hochniveau)

Wird im D4 nicht bedient";
CM_ SG_ 924 KL_Beschlagsgefahr "Beschlagsgefahr auf der Frontscheibe im Bereich des Spiegelfusses. Dient zur präventiven Ansteuerung der  Kamera-Scheibenheizung, um Kamera-Blindheit zu vermeiden
PHEV: volle Leistungsfreigabe HV Heizer und HV EKK bei Scheibenbeschlag ";
CM_ SG_ 924 ESP_07_alt "Veraltet Bit für die Signale:

Botschaft Gateway_05:
ESP_Codierung_ADS

Botschaft Gateway_06:
ESP_Codierung_ADS
";
CM_ SG_ 924 BCM1_GLW_Fernlicht_Anf "Harte Fernlichtanforderung von BCM1 an die Funktion 'gleitende Leuchtweite' im AFS-SG
(Signal wird im Panamera nicht bedient)";
CM_ SG_ 924 BCM1_Gleitende_Leuchtw_Anf "Funktion 'Gleitende Leuchtweite' im AFS-SG  freischalten
(Signal wird im Panamera nicht bedient)";
CM_ SG_ 924 BCM1_Adaptive_Lichtvert_Anf "Funktion 'Adaptive Lichtverteilung' im AFS-SG  Ein- und Ausschalten
(Signal wird im Panamera nicht bedient)";
CM_ SG_ 924 ESP_Offroad_Modus "Nur VW526: Bei Offroad-Fahrzeugen kann über einen Schalter ein Offroadmodus gewählt werden, dieser wird hier angezeigt. Bei Offroad Plus- Fahrzeugen wird hier der Offroadmodus indirekt durch das Verteilergetriebe vorgegeben (ALR_Offroad = 1) und eingespie";
CM_ SG_ 924 Wischer_vorne_aktiv "Status: Wischer vorne";
CM_ SG_ 924 HR_Tuer_geoeffnet "Tuer HR geoeffnet";
CM_ SG_ 924 HL_Tuer_geoeffnet "Tuer HL geoeffnet";
CM_ SG_ 924 BT_Tuer_geoeffnet "Beifahrertuer geoeffnet";
CM_ SG_ 924 BCM1_02_alt "Veraltet Bit für die Signale:

Botschaft Gateway_05:
BCM1_MH_WIV_Schalter
BCM1_Oeldruck_Schalter
BCM1_Oeldruck_Schalter_2

Botschaft Gateway_11:
LV_Abblendlicht_Anzeige
LV_Abblendlicht_li_def
LV_Abblendlicht_re_def

Botschaft Gateway_07:
LV_F";
CM_ SG_ 924 BCM1_01_alt "Veraltet Bit für die Signale:

Botschaft Gateway_04:
BCM1_Charisma_Text_1
BCM1_Charisma_Text_2

Botschaft Gateway_05:
BCM1_Rueckfahrlicht_Schalter
BCM1_Vorwaertsgang_eingelegt
BCM1_RFahrlicht_Fzg_Anf

Botschaft Gateway_07:
BCM1_Rueckfahrlicht_";
CM_ SG_ 924 FT_Tuer_geoeffnet "Fahrertuer geoeffnet";
CM_ SG_ 924 BCM1_Rueckfahrlicht_Schalter "Rückwärtsganginformation (unabhängig von Automatikgetriebe oder Handschalter)
(Quellsignal ist das Signal 'S_RF_Licht' vom BCM2. Es wird im BCM2 aus dem Signal 'Poshebel' und dem HW-Eingang S_RF_Licht gebildet.)";
CM_ SG_ 924 BCM1_MH_WIV_Schalter "Gilt nicht für PAG Panamera Basis. Wird konstant mit 0 gesendet.
Bewerteter Motorhaubenkontakt fuer WIV";
CM_ SG_ 924 BCM1_Aussen_Temp_ungef "ungefilterter Wert des Aussentemperatursensors
Quelle der Information ist die Bedien-Klimaeinheit BKE mit dem Signal 'KL_Atemp_ungef'
Das BCM1 muss dieses Signal weiterverarbeiten um die Wohlfühlumgebung für die Empfänger (TSG) zu ermöglichen";
CM_ SG_ 924 BCM2_03_PAG_alt "Ungültige Signale

für Botschaft: Gateway_05
BCM_Handshake_STH";
CM_ SG_ 924 Klima_02_alt "Ungueltige Signale:  KL_Zuheizer_Freigabe";
CM_ SG_ 924 KL_Zuheizer_Freigabe "Freigabe Zuheizer";
CM_ SG_ 924 BCM_Handshake_STH "Bestätigung für Kraftstoffpumpenanst
CAN Antr. im G1 nicht weckfähig->Handshake mit STH kann nicht stattfinden
Workaround für Panamera: Signal wird vom BCM2 gesendet
Zum E2 ist CAN Antrieb weckfähig->Signal kann direkt von der DME gesendet werden";
CM_ SG_ 924 Wischer_01_alt "Veraltet Bit für die Signale:

Botschaft Gateway_04:
Wischer_vorne_defekt

Botschaft Gateway_05:
Wischer_vorne_aktiv

Botschaft Gateway_07:
Wischer_vorne_aktiv";
CM_ SG_ 924 TSG_BT_1_alt "Veraltet Bit für die Signale:

Botschaft Gateway_05:
BT_Tuer_geoeffnet";
CM_ SG_ 924 TSG_HL_1_alt "Veraltet Bit für die Signale:

Botschaft Gateway_05:
HL_Tuer_geoeffnet";
CM_ SG_ 924 TSG_HR_1_alt "Veraltet Bit für die Signale:

Botschaft Gateway_05:
HR_Tuer_geoeffnet

MOST:";
CM_ SG_ 924 Klima_Sensor_02_alt "Veraltet Bit für die Signale:
Gateway_04:
BCM1_FStatus_Aussentemp_ungef
BCM1_Aussen_Temp_ungef
Gateway_05:
BCM1_FStatus_Aussentemp_ungef
BCM1_Aussen_Temp_ungef
BCM1_OBD_FStatus_ATemp
Gateway_07:
BCM1_Aussen_Temp_ungef
BCM1_FStatus_Au..";
CM_ SG_ 924 TSG_FT_1_alt "Veraltet Bit für die Signale:

Botschaft Gateway_04:
FT_Kisi_Fehler

Botschaft Gateway_05:
FT_Tuer_geoeffnet
FT_Sperrklinke

Botschaft Gateway_09:
FT_Tuer_geoeffnet";
CM_ SG_ 924 Parkhilfe_01_alt "Veraltet Bit für die Signale:

Botschaft Gateway_09:
PH_Anf_Audioabsenkung
";
CM_ SG_ 924 Fahrwerk_02_alt "Veraltet-Bit für die Signale:

Botschaft Charisma_02:
QS_Charisma_FahrPr
QS_Charisma_Status
QS_Charisma_Umschaltung";
CM_ SG_ 924 FA_StartStopp_Info "Stopp-Freigabe und Start-Anforderung an den Start-Stopp-Koordinator";
CM_ SG_ 924 PH_StartStopp_Info "Stopp-Freigabe und Start-Anforderung an den Start-Stopp-Koordinator";
CM_ SG_ 924 BCM1_OBD_FStatus_ATemp "Fehlerstatus Umgebungstemperatursensor (OBD relevanter Sensor)
";
CM_ SG_ 924 BCM1_Schalter_StartStopp "Deaktivierung Start/Stopp über Fahrer";
CM_ BO_ 1604 "langsame Gatewaybotschaft für den ACAN";
CM_ SG_ 1604 ESP_Diagnose "Nach Diagnoseende wird ein SW-Reset ausgelöst welcher einen Kommunikatiosausfall für max. 150ms verursacht. Dies ist bei SG mit verschärfter Timeoutüberwachung (nicht nach Konzern-LH) zu beachten.";
CM_ SG_ 1604 ESP_04_alt "Veraltet Bit für die Signale:

Botschaft Gateway_02:
ESP_Wegimp_VA
ESP_QBit_Wegimp_VA
ESP_Wegimp_Ueberlauf
ESP_Zaehnezahl
ESP_Diagnose
";
CM_ SG_ 1604 ZV_Tankklappe_offen "Öffnungsstatus der Tankklappe";
CM_ SG_ 1604 BCM_Tankwunsch "Tankwunsch (Fahrer betätigt Tankdeckeltaster)";
CM_ SG_ 1604 ZV_verriegelt_extern_ist "Istzustand: Verriegelung Fahrzeug aussen";
CM_ SG_ 1604 BCM2_02_alt "Veraltet Bit für die Signale:

Botschaft Gateway_11:
BCM2_P_verriegelt
ZV_verriegelt_extern_ist
ZV_Tankklappe_offen
BCM_Tankwunsch";
CM_ SG_ 1604 Kessy_01_alt "Veraltet Bit für die Signale: FFB_Auf_Taste, FFB_CarFinder
";
CM_ SG_ 1604 FFB_CarFinder "Car Finder Funktion (Blinken ohne zu entriegeln)";
CM_ SG_ 1604 FFB_Auf_Taste "Auf-Taste Funkschluessel";
CM_ SG_ 1604 Dummy_Blinkmodi_01_alt "Dummy-Veraltet-Bit für Ausfall Signal BM_Autobahn.
Grund: PAG Gateway benötigt Veraltet-Bit für Ausfall Botschaft Blinkmodi_01, die aber nicht zyklisch gesendet wird
";
CM_ SG_ 1604 BCM1_01_alt "Veraltet Bit für die Signale:

Botschaft Gateway_04:
BCM1_Charisma_Text_1
BCM1_Charisma_Text_2

Botschaft Gateway_05:
BCM1_Rueckfahrlicht_Schalter
BCM1_Vorwaertsgang_eingelegt
BCM1_RFahrlicht_Fzg_Anf

Botschaft Gateway_07:
BCM1_Rueckfahrlicht_";
CM_ SG_ 1604 LV_Nebelschlusslicht_Anzeige "Nebelschlusslicht aktiv";
CM_ SG_ 1604 LV_Abblendlicht_re_def "Fehlerstatus Abblendlicht vorne rechts";
CM_ SG_ 1604 LV_Abblendlicht_li_def "Fehlerstatus Abblendlicht vorne links";
CM_ SG_ 1604 BM_Autobahn "Status Autobahnblinken";
CM_ SG_ 1604 BCM1_Touristen_Licht_Anf "Anforderung: Touristenlicht (Sollzustand)
(Signal wird im Panamera nicht bedient)";
CM_ SG_ 1604 BCM1_Linksverkehr "Information über Aufbauzustand des Fzg:
(Signal wird im Panamera nicht bedient)";
CM_ SG_ 1604 BCM1_Licht_Dunkelheit_aktiv "Licht aktiv aufgrund von Dunkelheit (nicht bei Autobahn-, Tagfahr- oder Regenlicht)
(Signal wird im Panamera nicht bedient)";
CM_ SG_ 1604 BCM1_Allwetterlicht_Anf "Anforderung eines Allwetterlichts (über AFS-SG realisiert) bei AUDI: Licht für schlechte Sichtverhältnisse
(Signal wird im Panamera nicht bedient)";
CM_ SG_ 1604 BCM1_MH_Schalter "Motorhaubenkontakt";
CM_ SG_ 1604 BH_Blinker_re "Blinkerhebel Richtung rechts";
CM_ SG_ 1604 BH_Blinker_li "Blinkerhebel Richtung links";
CM_ SG_ 1604 SMLS_01_alt "Veraltet Bit für die Signale:

Botschaft Gateway_07:
BH_Blinker_li
BH_Blinker_re
LDW_Taster
LDW_Taster_Fehler
LDW_Vib_Lenkrad_Fehler
BH_Fernlicht

Botschaft Gateway_11:
BH_Blinker_li
BH_Blinker_re
";
CM_ SG_ 1604 BCM1_02_alt "Veraltet Bit für die Signale:

Botschaft Gateway_05:
BCM1_MH_WIV_Schalter
BCM1_Oeldruck_Schalter
BCM1_Oeldruck_Schalter_2

Botschaft Gateway_11:
LV_Abblendlicht_Anzeige
LV_Abblendlicht_li_def
LV_Abblendlicht_re_def

Botschaft Gateway_07:
LV_F";
CM_ SG_ 1604 HYB_Anf_E_Mode_alt "funktionales Veraltet-Bit für Hybrid-Taster
Ungueltige Signale: HYB_Anf_E_Mode
";
CM_ SG_ 1604 HYB_Anf_E_Mode "E-Taste (Hybrid)
(Signal wird im Panamera nicht vom BCM1 bedient, sondern von der BKE (Klima_08_PAG))";
CM_ SG_ 130 Getriebe_01_CHK "Berechnung siehe Lastenheft 'Kommunikationsabsicherung für FlexRay und CAN'
Endwerte siehe 'Kommunikationsabsicherung für FlexRay und CAN / Anhang C: Tabelle S-PDU Kennungen'";
CM_ SG_ 130 GE_Status_Kupplung "Auch für Anfahrkupplung beim VL30 und Kupplung beim Ecodrive (geregelt bedeutet in diesem Fall die Kupplung ist nicht vollständig getrennt bzw. hat Schlupf) genutzt; bei starken Verstellwegen wird 'geöffnet' gesendet (VQ250)";
CM_ SG_ 130 GE_MMom_Soll "Achtung:
Einheitenloser CAN-Wert.
Faktor in MO_Faktor_Momente in Motor_Code_01 beachten!

Getriebeeingriff an den Motor. Indiziertes Moment.";
CM_ SG_ 130 GE_MMom_Status "Qualifiziert GE_MMom_Soll";
CM_ SG_ 130 GE_Freig_Mmom_Soll "Entfall des Signals in v698, da nicht mehr benötigt";
CM_ SG_ 130 GE_Verbot_Ausblendung "Verbot Einspritzausblendung für komfortable Schaltungen";
CM_ SG_ 130 GE_MMom_Vorhalt "Anforderung einer Momentenreserve durch das Getriebe, inneres Moment, gilt nur mit Freigabe durch 
GE_Freig_MMom_Vorhalt

Achtung!
Einheitenloser CAN-Wert.
Faktor in MO_Faktor_Momente in Motor_Code_01 beachten!";
CM_ SG_ 130 GE_Freig_MMom_Vorhalt "Freigabe für die Anforderung einer Momentenreserve durch das Getriebe über das Signal GE_MMom_Vorhalt";
CM_ SG_ 131 GE_Anf_Zylabsch "GE_Anforderung_Zylinderabschaltung
Getriebe-Koordination Zylinderumschaltung TMB / VMB (Teilmotorbetrieb / Vollmotorbetrieb)";
CM_ SG_ 131 Getriebe_02_CHK "Berechnung siehe Lastenheft 'Kommunikationsabsicherung für FlexRay und CAN'
Endwerte siehe 'Kommunikationsabsicherung für FlexRay und CAN / Anhang C: Tabelle S-PDU Kennungen'";
CM_ SG_ 131 GE_Mom_Begr_Gradient "Drehmomenten-Gradientenbegrenzung für Teillastanfahrten mit dem VL30-Getriebe und Standabkopplung beim 5HPx, 6HPx. Wird auch während Schaltungen verwendet.";
CM_ SG_ 131 GE_Anheb_Solldrehz_Leerlauf "Wunschvorgabewert des Getriebes an den Motor, die Leerlaufdrehzahl auf den gesendeten Betrag x anzuheben (Vorgabe des Absolutwertes)";
CM_ SG_ 131 GE_Vorsteuermoment "Achtung:
Einheitenloser CAN-Wert.
Faktor in MO_Faktor_Momente in Motor_Code_01 beachten!

Vorsteuermoment für Leerlaufdrehzahlregler im Motor";
CM_ SG_ 131 GE_Drehzahlmesser_Daempfung "Beim DQ-Getriebe kann die Anzeigedämpfung des Drehzahlmessers beim Schalten geändert werden.";
CM_ SG_ 131 GE_Schubabschalt_Unt "Wenn die Schubabschalt-Unterstützung aktiv ist, wird vom VL300-Steuergerät sichergestellt, daß die Kupplung nicht schlagartig geöffnet wird.";
CM_ SG_ 131 GE_Freigabe_Synchro "Freigabe Synchronisations-Wunschdrehzahl und Synchronisationszeit";
CM_ SG_ 131 GE_HYB_DZ_Eingriff "Freigabebedingung für Drehzahleingriff-Hybrid";
CM_ SG_ 258 GE_Waehlhebel "Getriebeposition (Nicht Wählhebelposition!)
Die im Getriebe aktive Fahrstufe entspricht nicht unter allen Umständen der phy. Wählhebelpos.
Unterschied zu 'GE_poshebel' in Getriebe_01 ist die Wertetabelle (= wie VW/Audi für Wohlfuehlumgebung Komf.-SG)";
CM_ SG_ 258 GE_StartStopp_Info "Start/Stop-Info, Veto";
CM_ SG_ 258 Getriebe_03_CHK "Berechnung siehe Lastenheft 'Kommunikationsabsicherung für FlexRay und CAN'
Endwerte siehe 'Kommunikationsabsicherung für FlexRay und CAN / Anhang C: Tabelle S-PDU Kennungen'";
CM_ SG_ 258 GE_Freig_Langfr_Schutzmom "Freigabeflag für das langfristige Schutzmoment";
CM_ SG_ 258 GE_Uefkt "Übertragungsfunktion vom Getriebe

Wandlerverstärkung x Drehzahlverhältnis

Beim Kupplungsautomat (VL, DL) ist der Faktor 1";
CM_ SG_ 258 GE_Zielgang "Zielgang, wenn Schaltung aktiv ist. Ansonsten wird der aktuell eingelegte Gang ausgegeben. 

0x9 - 0xA = tbd
0xD = tbd.
";
CM_ SG_ 258 GE_Langfr_Schutzmom "Achtung:
Einheitenloser CAN-Wert.
Faktor in MO_Faktor_Momente in Motor_Code_01 beachten!

geführter Getriebeschutz";
CM_ SG_ 258 GE_reserv_Waehlhebel "reserviert falls künftig Erweiterung von GE_Waehlhebel nötig";
CM_ SG_ 258 GE_Eingangsdrehz "Wird gesendet, um das Lastschlagverhalten bei Schaltvorgängen zu verbessern.";
CM_ SG_ 258 GE_Codierung_MSG "Wenn das Getriebe bei der Codierplausibilisierung zum Motor einen Fehler erkennt wird das Bit auf 0x1 gesetzt. ESP wirft daraufhin die Funktion ab.";
BA_DEF_  "BusType" STRING ;
BA_DEF_ SG_  "DERIVATE_Pruefung" ENUM  "offen","geprüft";
BA_DEF_ SG_  "HYB_Rx_Baureihe" ENUM  "G1+Derivate","nur G1","nur Derivate";
BA_DEF_ SG_  "HYB_Rx_Verwendung" ENUM  "DERIV_Rout","DERIV_Calc","DERIV_Rout+DERIV_Calc";
BA_DEF_ SG_  "GenSigSwitchedByIgnition" ENUM  "No","Yes";
BA_DEF_ SG_  "GenSigEnvVarType" ENUM  "int","float","undef";
BA_DEF_ SG_  "GenSigAutoGenSnd" ENUM  "No","Yes";
BA_DEF_ SG_  "GenSigAutoGenDsp" ENUM  "No","Yes";
BA_DEF_ SG_  "GenSigActiveRepetitions" INT -2147483648 2147483647;
BA_DEF_ SG_  "GenSigFuncType" ENUM  "NoFunction","MsgCounter","CRC-8","XOR","XOR-2","DatedBit","SW-Kl15","CHK","Constant","Protocol";
BA_DEF_ SG_  "Info_BCM_HutHut_Kommunikation" ENUM  "Nein","Ja";
BA_DEF_ SG_  "NWM-WakeupAllowed" ENUM  "No","Yes";
BA_DEF_ SG_  "GenSigInactiveValue" STRING ;
BA_DEF_ SG_  "GenSigMissingSourceValue" INT 0 2147483647;
BA_DEF_ SG_  "GenSigStartValue" INT 0 0;
BA_DEF_ SG_  "Fehlerwert" HEX 0 2147483647;
BA_DEF_ SG_  "Bemerkung" STRING ;
BA_DEF_ SG_  "GenSigSendType" ENUM  "Cyclic","OnWrite","OnWriteWithRepetition","OnChange","OnChangeWithRepetition","IfActive","IfActiveWithRepetition","NoSigSendType";
BA_DEF_ BO_  "NmMessage" ENUM  "No","Yes";
BA_DEF_ BO_  "GenMsgAutoGenSnd" ENUM  "No","Yes";
BA_DEF_ BO_  "GenMsgAutoGenDsp" ENUM  "No","Yes";
BA_DEF_ BO_  "MsgType" ENUM  "Broadcast","Event","NM ","NMH","TP2.0","ISO-TP ","BAP","EID";
BA_DEF_ BO_  "GenMsgChkConstant" HEX 0 4095;
BA_DEF_ BO_  "sim_GenMsgILSupport" ENUM  "No","Yes";
BA_DEF_ BO_  "NWM-Botschaft" ENUM  "No","Yes";
BA_DEF_ BO_  "VAGTP20_StatConnection" ENUM  "No","Yes";
BA_DEF_ BO_  "VAGTP20_DynSetup" ENUM  "No","Yes";
BA_DEF_ BO_  "VAGTP20_DynConnection" ENUM  "No","Yes";
BA_DEF_ BO_  "VAGTP20_API" HEX 0 255;
BA_DEF_ BO_  "Direkt_1zu1" ENUM  "Nein","Ja";
BA_DEF_ BO_  "GenMsgSendType" ENUM  "Cyclic","NotUsed","NotUsed","NotUsed","NotUsed","NotUsed","NotUsed","IfActive","NoMsgSendType","NotUsed";
BA_DEF_ BO_  "DiagResponse" ENUM  "No","Yes";
BA_DEF_ BO_  "DiagRequest" ENUM  "No","Yes";
BA_DEF_ BO_  "GenMsgDelayTime" INT 0 65535;
BA_DEF_ BO_  "GenMsgStartDelayTime" INT 0 65535;
BA_DEF_ BO_  "GenMsgILSupport" ENUM  "No","Yes";
BA_DEF_ BO_  "NmhMessage" ENUM  "No","Yes";
BA_DEF_ BO_  "GenMsgNrOfRepetition" INT 0 65535;
BA_DEF_ BO_  "GenMsgCycleTimeFast" INT 0 65535;
BA_DEF_ BO_  "DiagState" ENUM  "No","Yes";
BA_DEF_ BO_  "GenMsgCycleTime" INT 0 65535;
BA_DEF_ BU_  "ECUVariantDefault" ENUM  "No","Yes";
BA_DEF_ BU_  "GenNodAutoGenSnd" ENUM  "No","Yes";
BA_DEF_ BU_  "GenNodAutoGenDsp" ENUM  "No","Yes";
BA_DEF_ BU_  "sim_ILUsed" ENUM  "No","Yes";
BA_DEF_ BU_  "NodeLayerModules" STRING ;
BA_DEF_ BU_  "ILUsed" ENUM  "No","Yes";
BA_DEF_ BU_  "NmhNode" ENUM  "No","Yes","vector_leerstring";
BA_DEF_ BU_  "SG_Bauteilverantwortlicher" STRING ;
BA_DEF_  "NmhLongTimer" INT 0 65535;
BA_DEF_  "NmhPrepareBussleepTimer" INT 0 65535;
BA_DEF_  "NmhWaitBusSleepTimer" INT 0 65535;
BA_DEF_  "NmhTimeoutTimer" INT 0 65535;
BA_DEF_  "VersionMonth" INT 0 12;
BA_DEF_  "VersionDay" INT 0 31;
BA_DEF_  "GenNWMSleepTime" INT 0 1000000;
BA_DEF_  "VersionYear" INT 2005 2050;
BA_DEF_  "VersionWeek" INT 0 53;
BA_DEF_  "VersionNumber" INT 0 65535;
BA_DEF_  "Manufacturer" STRING ;
BA_DEF_  "NmhMessageCount" INT 1 256;
BA_DEF_  "NmhBaseAddress" HEX 0 536870911;
BA_DEF_  "NmType" STRING ;
BA_DEF_  "DBName" STRING ;
BA_DEF_  "Baudrate" INT 0 1000000;
BA_DEF_  "SamplePointMin" INT 0 100;
BA_DEF_  "SamplePointMax" INT 0 100;
BA_DEF_  "SyncJumpWidthMin" INT 2 2;
BA_DEF_  "SyncJumpWidthMax" INT 3 3;
BA_DEF_REL_ BU_BO_REL_  "HYB_Tx_Verwendung" ENUM  "Rout","Calc";
BA_DEF_REL_ BU_BO_REL_  "HYB_Tx_Baureihe" ENUM  "G1+Derivate","G1","Derivate","vector_leerstring";
BA_DEF_REL_ BU_SG_REL_  "GenSigTimeoutTime" INT 0 65535;
BA_DEF_DEF_  "BusType" "";
BA_DEF_DEF_  "DERIVATE_Pruefung" "offen";
BA_DEF_DEF_  "HYB_Rx_Baureihe" "G1+Derivate";
BA_DEF_DEF_  "HYB_Rx_Verwendung" "DERIV_Rout";
BA_DEF_DEF_  "GenSigSwitchedByIgnition" "No";
BA_DEF_DEF_  "GenSigEnvVarType" "undef";
BA_DEF_DEF_  "GenSigAutoGenSnd" "No";
BA_DEF_DEF_  "GenSigAutoGenDsp" "No";
BA_DEF_DEF_  "GenSigActiveRepetitions" 0;
BA_DEF_DEF_  "GenSigFuncType" "NoFunction";
BA_DEF_DEF_  "Info_BCM_HutHut_Kommunikation" "Nein";
BA_DEF_DEF_  "NWM-WakeupAllowed" "Yes";
BA_DEF_DEF_  "GenSigInactiveValue" "0";
BA_DEF_DEF_  "GenSigMissingSourceValue" 0;
BA_DEF_DEF_  "GenSigStartValue" 0;
BA_DEF_DEF_  "Fehlerwert" 0;
BA_DEF_DEF_  "Bemerkung" "";
BA_DEF_DEF_  "GenSigSendType" "Cyclic";
BA_DEF_DEF_  "NmMessage" "No";
BA_DEF_DEF_  "GenMsgAutoGenSnd" "Yes";
BA_DEF_DEF_  "GenMsgAutoGenDsp" "Yes";
BA_DEF_DEF_  "MsgType" "Broadcast";
BA_DEF_DEF_  "GenMsgChkConstant" 0;
BA_DEF_DEF_  "sim_GenMsgILSupport" "No";
BA_DEF_DEF_  "NWM-Botschaft" "No";
BA_DEF_DEF_  "VAGTP20_StatConnection" "No";
BA_DEF_DEF_  "VAGTP20_DynSetup" "No";
BA_DEF_DEF_  "VAGTP20_DynConnection" "No";
BA_DEF_DEF_  "VAGTP20_API" 1;
BA_DEF_DEF_  "Direkt_1zu1" "Nein";
BA_DEF_DEF_  "GenMsgSendType" "Cyclic";
BA_DEF_DEF_  "DiagResponse" "No";
BA_DEF_DEF_  "DiagRequest" "No";
BA_DEF_DEF_  "GenMsgDelayTime" 0;
BA_DEF_DEF_  "GenMsgStartDelayTime" 0;
BA_DEF_DEF_  "GenMsgILSupport" "No";
BA_DEF_DEF_  "NmhMessage" "No";
BA_DEF_DEF_  "GenMsgNrOfRepetition" 0;
BA_DEF_DEF_  "GenMsgCycleTimeFast" 0;
BA_DEF_DEF_  "DiagState" "No";
BA_DEF_DEF_  "GenMsgCycleTime" 0;
BA_DEF_DEF_  "ECUVariantDefault" "Yes";
BA_DEF_DEF_  "GenNodAutoGenSnd" "Yes";
BA_DEF_DEF_  "GenNodAutoGenDsp" "Yes";
BA_DEF_DEF_  "sim_ILUsed" "No";
BA_DEF_DEF_  "NodeLayerModules" "CANoeILNLVector.dll";
BA_DEF_DEF_  "ILUsed" "No";
BA_DEF_DEF_  "NmhNode" "No";
BA_DEF_DEF_  "SG_Bauteilverantwortlicher" "";
BA_DEF_DEF_  "NmhLongTimer" 100;
BA_DEF_DEF_  "NmhPrepareBussleepTimer" 500;
BA_DEF_DEF_  "NmhWaitBusSleepTimer" 750;
BA_DEF_DEF_  "NmhTimeoutTimer" 1000;
BA_DEF_DEF_  "VersionMonth" 0;
BA_DEF_DEF_  "VersionDay" 0;
BA_DEF_DEF_  "GenNWMSleepTime" 5000;
BA_DEF_DEF_  "VersionYear" 2005;
BA_DEF_DEF_  "VersionWeek" 0;
BA_DEF_DEF_  "VersionNumber" 0;
BA_DEF_DEF_  "Manufacturer" "PAG";
BA_DEF_DEF_  "NmhMessageCount" 64;
BA_DEF_DEF_  "NmhBaseAddress" 1728;
BA_DEF_DEF_  "NmType" "None";
BA_DEF_DEF_  "DBName" "";
BA_DEF_DEF_  "Baudrate" 500000;
BA_DEF_DEF_  "SamplePointMin" 75;
BA_DEF_DEF_  "SamplePointMax" 85;
BA_DEF_DEF_  "SyncJumpWidthMin" 2;
BA_DEF_DEF_  "SyncJumpWidthMax" 3;
BA_DEF_DEF_REL_ "HYB_Tx_Verwendung" "Rout";
BA_DEF_DEF_REL_ "HYB_Tx_Baureihe" "G1+Derivate";
BA_DEF_DEF_REL_ "GenSigTimeoutTime" 0;
BA_ "BusType" "CAN";
BA_ "NmType" "NM-High";
BA_ "VersionNumber" 1200;
BA_ "VersionWeek" 22;
BA_ "VersionYear" 2012;
BA_ "VersionDay" 1;
BA_ "VersionMonth" 6;
BA_ "NmhLongTimer" 200;
BA_ "DBName" "CAN_Antrieb_Derivate";
BA_ "ILUsed" BU_ Sound_A 1;
BA_ "sim_ILUsed" BU_ Sound_A 1;
BA_ "NmhNode" BU_ Ladegeraet_PAG_PF 1;
BA_ "ILUsed" BU_ Ladegeraet_PAG_PF 1;
BA_ "NodeLayerModules" BU_ Ladegeraet_PAG_PF "CANoeILNLVAG.dll, NMHigh.DLL";
BA_ "sim_ILUsed" BU_ Ladegeraet_PAG_PF 1;
BA_ "SG_Bauteilverantwortlicher" BU_ Ladegeraet_PAG_PF "Dirk Herke";
BA_ "NmhNode" BU_ Motor_EDC17_Pirol 1;
BA_ "ILUsed" BU_ Motor_EDC17_Pirol 1;
BA_ "NodeLayerModules" BU_ Motor_EDC17_Pirol "CANoeILNLVAG.dll, NMHigh.DLL";
BA_ "sim_ILUsed" BU_ Motor_EDC17_Pirol 1;
BA_ "SG_Bauteilverantwortlicher" BU_ Motor_EDC17_Pirol "Tobias Berr";
BA_ "NmhNode" BU_ PSM_Ant_Derivate 1;
BA_ "ILUsed" BU_ PSM_Ant_Derivate 1;
BA_ "NodeLayerModules" BU_ PSM_Ant_Derivate "CANoeILNLVAG.dll, NMHigh.DLL";
BA_ "sim_ILUsed" BU_ PSM_Ant_Derivate 1;
BA_ "SG_Bauteilverantwortlicher" BU_ PSM_Ant_Derivate "Ralf Eichele";
BA_ "NmhNode" BU_ GW_Routing_Derivate 1;
BA_ "ILUsed" BU_ GW_Routing_Derivate 1;
BA_ "NodeLayerModules" BU_ GW_Routing_Derivate "CANoeILNLVAG.dll, NMHigh.DLL";
BA_ "sim_ILUsed" BU_ GW_Routing_Derivate 1;
BA_ "SG_Bauteilverantwortlicher" BU_ GW_Routing_Derivate "Karl-Peter Spring";
BA_ "NmhNode" BU_ GW_Applikation_Derivate 1;
BA_ "ILUsed" BU_ GW_Applikation_Derivate 1;
BA_ "NodeLayerModules" BU_ GW_Applikation_Derivate "CANoeILNLVAG.dll, NMHigh.DLL";
BA_ "sim_ILUsed" BU_ GW_Applikation_Derivate 1;
BA_ "SG_Bauteilverantwortlicher" BU_ GW_Applikation_Derivate "Karl-Peter Spring";
BA_ "NmhNode" BU_ BMS_Hybrid 1;
BA_ "ILUsed" BU_ BMS_Hybrid 1;
BA_ "NodeLayerModules" BU_ BMS_Hybrid "CANoeILNLVAG.dll, NMHigh.DLL";
BA_ "sim_ILUsed" BU_ BMS_Hybrid 1;
BA_ "SG_Bauteilverantwortlicher" BU_ BMS_Hybrid "Thomas Fritz";
BA_ "NmhNode" BU_ Getriebe_Derivate 1;
BA_ "ILUsed" BU_ Getriebe_Derivate 1;
BA_ "NodeLayerModules" BU_ Getriebe_Derivate "CANoeILNLVAG.dll, NMHigh.DLL";
BA_ "sim_ILUsed" BU_ Getriebe_Derivate 1;
BA_ "SG_Bauteilverantwortlicher" BU_ Getriebe_Derivate "Hans-Jürgen Renk";
BA_ "NmhNode" BU_ LEH_Hybrid 1;
BA_ "ILUsed" BU_ LEH_Hybrid 1;
BA_ "NodeLayerModules" BU_ LEH_Hybrid "CANoeILNLVAG.dll, NMHigh.DLL";
BA_ "sim_ILUsed" BU_ LEH_Hybrid 1;
BA_ "SG_Bauteilverantwortlicher" BU_ LEH_Hybrid "Wolfgang Steck";
BA_ "NmhNode" BU_ Motor_MED17_Hybrid 1;
BA_ "ILUsed" BU_ Motor_MED17_Hybrid 1;
BA_ "NodeLayerModules" BU_ Motor_MED17_Hybrid "CANoeILNLVAG.dll, NMHigh.DLL";
BA_ "sim_ILUsed" BU_ Motor_MED17_Hybrid 1;
BA_ "SG_Bauteilverantwortlicher" BU_ Motor_MED17_Hybrid "Christian Wiedenbrügge";
BA_ "ILUsed" BU_ Sound_I 1;
BA_ "sim_ILUsed" BU_ Sound_I 1;
BA_ "ILUsed" BU_ Tool 1;
BA_ "NodeLayerModules" BU_ Tool "CANoeILNLVAG.dll";
BA_ "SG_Bauteilverantwortlicher" BU_ Tool "Thomas Krause";
BA_ "ILUsed" BU_ Airbag 1;
BA_ "NodeLayerModules" BU_ Airbag "CANoeILNLVAG.dll";
BA_ "sim_ILUsed" BU_ Airbag 1;
BA_ "SG_Bauteilverantwortlicher" BU_ Airbag "John Hasenclever";
BA_ "ILUsed" BU_ Waehlhebel 1;
BA_ "NodeLayerModules" BU_ Waehlhebel "CANoeILNLVAG.dll";
BA_ "sim_ILUsed" BU_ Waehlhebel 1;
BA_ "SG_Bauteilverantwortlicher" BU_ Waehlhebel "Peter Knysch";
BA_ "GenMsgCycleTime" BO_ 305 20;
BA_ "GenMsgILSupport" BO_ 305 1;
BA_ "VAGTP20_API" BO_ 305 0;
BA_ "GenMsgCycleTime" BO_ 914 80;
BA_ "GenMsgILSupport" BO_ 914 1;
BA_ "GenMsgChkConstant" BO_ 914 145;
BA_ "GenMsgCycleTime" BO_ 906 100;
BA_ "GenMsgCycleTimeFast" BO_ 906 100;
BA_ "GenMsgILSupport" BO_ 906 1;
BA_ "VAGTP20_API" BO_ 906 0;
BA_ "GenMsgCycleTime" BO_ 1731 200;
BA_ "NmhMessage" BO_ 1731 1;
BA_ "GenMsgSendType" BO_ 1731 8;
BA_ "VAGTP20_API" BO_ 1731 0;
BA_ "MsgType" BO_ 1731 3;
BA_ "GenMsgCycleTime" BO_ 946 100;
BA_ "GenMsgILSupport" BO_ 946 1;
BA_ "VAGTP20_API" BO_ 946 0;
BA_ "sim_GenMsgILSupport" BO_ 946 1;
BA_ "GenMsgCycleTime" BO_ 1628 500;
BA_ "GenMsgILSupport" BO_ 1628 1;
BA_ "VAGTP20_API" BO_ 1628 0;
BA_ "sim_GenMsgILSupport" BO_ 1628 1;
BA_ "GenMsgSendType" BO_ 490 8;
BA_ "VAGTP20_API" BO_ 490 0;
BA_ "MsgType" BO_ 490 7;
BA_ "GenMsgSendType" BO_ 488 8;
BA_ "VAGTP20_API" BO_ 488 0;
BA_ "MsgType" BO_ 488 7;
BA_ "GenMsgSendType" BO_ 2616986625 8;
BA_ "VAGTP20_API" BO_ 2616986625 0;
BA_ "MsgType" BO_ 2616986625 7;
BA_ "GenMsgCycleTime" BO_ 945 100;
BA_ "GenMsgILSupport" BO_ 945 1;
BA_ "VAGTP20_API" BO_ 945 0;
BA_ "sim_GenMsgILSupport" BO_ 945 1;
BA_ "GenMsgCycleTime" BO_ 1627 500;
BA_ "GenMsgILSupport" BO_ 1627 1;
BA_ "VAGTP20_API" BO_ 1627 0;
BA_ "sim_GenMsgILSupport" BO_ 1627 1;
BA_ "GenMsgCycleTime" BO_ 256 20;
BA_ "GenMsgILSupport" BO_ 256 1;
BA_ "Direkt_1zu1" BO_ 256 1;
BA_ "VAGTP20_API" BO_ 256 0;
BA_ "sim_GenMsgILSupport" BO_ 256 1;
BA_ "GenMsgChkConstant" BO_ 256 171;
BA_ "GenMsgCycleTime" BO_ 257 20;
BA_ "GenMsgILSupport" BO_ 257 1;
BA_ "Direkt_1zu1" BO_ 257 1;
BA_ "VAGTP20_API" BO_ 257 0;
BA_ "sim_GenMsgILSupport" BO_ 257 1;
BA_ "GenMsgChkConstant" BO_ 257 170;
BA_ "DiagState" BO_ 1795 1;
BA_ "GenMsgSendType" BO_ 1795 8;
BA_ "Direkt_1zu1" BO_ 1795 1;
BA_ "VAGTP20_API" BO_ 1795 0;
BA_ "MsgType" BO_ 1795 5;
BA_ "GenMsgSendType" BO_ 482 8;
BA_ "VAGTP20_API" BO_ 482 0;
BA_ "MsgType" BO_ 482 7;
BA_ "GenMsgCycleTime" BO_ 259 20;
BA_ "GenMsgILSupport" BO_ 259 1;
BA_ "Direkt_1zu1" BO_ 259 1;
BA_ "VAGTP20_API" BO_ 259 0;
BA_ "sim_GenMsgILSupport" BO_ 259 1;
BA_ "GenMsgChkConstant" BO_ 259 2;
BA_ "GenMsgCycleTime" BO_ 776 50;
BA_ "GenMsgILSupport" BO_ 776 1;
BA_ "VAGTP20_API" BO_ 776 0;
BA_ "sim_GenMsgILSupport" BO_ 776 1;
BA_ "GenMsgCycleTime" BO_ 262 20;
BA_ "GenMsgILSupport" BO_ 262 1;
BA_ "Direkt_1zu1" BO_ 262 1;
BA_ "VAGTP20_API" BO_ 262 0;
BA_ "sim_GenMsgILSupport" BO_ 262 1;
BA_ "GenMsgChkConstant" BO_ 262 7;
BA_ "GenMsgCycleTime" BO_ 793 40;
BA_ "GenMsgILSupport" BO_ 793 1;
BA_ "Direkt_1zu1" BO_ 793 1;
BA_ "VAGTP20_API" BO_ 793 0;
BA_ "GenMsgChkConstant" BO_ 793 26;
BA_ "GenMsgCycleTime" BO_ 924 100;
BA_ "GenMsgILSupport" BO_ 924 1;
BA_ "GenMsgDelayTime" BO_ 924 10;
BA_ "VAGTP20_API" BO_ 924 0;
BA_ "GenMsgCycleTime" BO_ 1604 500;
BA_ "GenMsgILSupport" BO_ 1604 1;
BA_ "GenMsgDelayTime" BO_ 1604 50;
BA_ "VAGTP20_API" BO_ 1604 0;
BA_ "GenMsgCycleTime" BO_ 130 10;
BA_ "GenMsgILSupport" BO_ 130 1;
BA_ "Direkt_1zu1" BO_ 130 1;
BA_ "VAGTP20_API" BO_ 130 0;
BA_ "sim_GenMsgILSupport" BO_ 130 1;
BA_ "GenMsgChkConstant" BO_ 130 130;
BA_ "GenMsgCycleTime" BO_ 131 10;
BA_ "GenMsgILSupport" BO_ 131 1;
BA_ "Direkt_1zu1" BO_ 131 1;
BA_ "VAGTP20_API" BO_ 131 0;
BA_ "sim_GenMsgILSupport" BO_ 131 1;
BA_ "GenMsgChkConstant" BO_ 131 131;
BA_ "GenMsgCycleTime" BO_ 258 20;
BA_ "GenMsgILSupport" BO_ 258 1;
BA_ "Direkt_1zu1" BO_ 258 1;
BA_ "VAGTP20_API" BO_ 258 0;
BA_ "sim_GenMsgILSupport" BO_ 258 1;
BA_ "GenMsgChkConstant" BO_ 258 3;
BA_ "Bemerkung" SG_ 3221225472 KBI_Trip_E_Std "Kurzzeitzähler / Fahrdaten seit hh::mm";
BA_ "NWM-WakeupAllowed" SG_ 3221225472 KBI_Trip_E_Std 0;
BA_ "Bemerkung" SG_ 3221225472 KBI_Trip_E_Min "Kurzzeitzähler / Fahrdaten seit hh::mm";
BA_ "NWM-WakeupAllowed" SG_ 3221225472 KBI_Trip_E_Min 0;
BA_ "Fehlerwert" SG_ 3221225472 KBI_Service_km 1023;
BA_ "GenSigStartValue" SG_ 3221225472 KBI_Service_km 1022;
BA_ "NWM-WakeupAllowed" SG_ 3221225472 KBI_Service_km 0;
BA_ "Fehlerwert" SG_ 3221225472 KBI_Service_Zeit 2047;
BA_ "GenSigStartValue" SG_ 3221225472 KBI_Service_Zeit 2046;
BA_ "NWM-WakeupAllowed" SG_ 3221225472 KBI_Service_Zeit 0;
BA_ "NWM-WakeupAllowed" SG_ 3221225472 KBI_Service_Typ 0;
BA_ "NWM-WakeupAllowed" SG_ 3221225472 DEV_BMS_Resp_07_Data 0;
BA_ "NWM-WakeupAllowed" SG_ 3221225472 DEV_BMS_Resp_06_Data 0;
BA_ "NWM-WakeupAllowed" SG_ 3221225472 DEV_BMS_Resp_05_Data 0;
BA_ "NWM-WakeupAllowed" SG_ 3221225472 Mo_HVEM_HV_Abschaltanf 0;
BA_ "Fehlerwert" SG_ 3221225472 MO_HVEM_HV_Maxleistung 255;
BA_ "GenSigStartValue" SG_ 3221225472 MO_HVEM_HV_Maxleistung 254;
BA_ "NWM-WakeupAllowed" SG_ 3221225472 MO_HVEM_HV_Maxleistung 0;
BA_ "Fehlerwert" SG_ 3221225472 HVEM_Istleistung_Nebenverbrauch 255;
BA_ "GenSigStartValue" SG_ 3221225472 HVEM_Istleistung_Nebenverbrauch 254;
BA_ "NWM-WakeupAllowed" SG_ 3221225472 HVEM_Istleistung_Nebenverbrauch 0;
BA_ "NWM-WakeupAllowed" SG_ 3221225472 BMS_TauKuehlmittel__Temp_ 0;
BA_ "NWM-WakeupAllowed" SG_ 3221225472 SVB_IVB_FS_Fond 0;
BA_ "NWM-WakeupAllowed" SG_ 3221225472 SVB_IVB_FS 0;
BA_ "NWM-WakeupAllowed" SG_ 3221225472 SVB_IVB_BFS_Fond 0;
BA_ "NWM-WakeupAllowed" SG_ 3221225472 SVB_IVB_BFS 0;
BA_ "NWM-WakeupAllowed" SG_ 3221225472 AWV_Halten 0;
BA_ "NWM-WakeupAllowed" SG_ 305 MO_ePowermeter 0;
BA_ "NWM-WakeupAllowed" SG_ 305 MO_W_Reku_normiert_ueberlauf 0;
BA_ "Fehlerwert" SG_ 305 Ladezustand 255;
BA_ "NWM-WakeupAllowed" SG_ 305 Ladezustand 0;
BA_ "Fehlerwert" SG_ 305 Enrgfluss_State 255;
BA_ "NWM-WakeupAllowed" SG_ 305 Enrgfluss_State 0;
BA_ "NWM-WakeupAllowed" SG_ 305 MO_W_Reku_normiert 0;
BA_ "GenSigStartValue" SG_ 305 MO_Powermeter 4093;
BA_ "NWM-WakeupAllowed" SG_ 305 MO_Powermeter 0;
BA_ "NWM-WakeupAllowed" SG_ 914 ESP_07_BZ 0;
BA_ "GenSigFuncType" SG_ 914 ESP_07_BZ 1;
BA_ "NWM-WakeupAllowed" SG_ 914 ESP_07_CHK 0;
BA_ "GenSigFuncType" SG_ 914 ESP_07_CHK 3;
BA_ "NWM-WakeupAllowed" SG_ 914 ESP_OBD_Status 0;
BA_ "NWM-WakeupAllowed" SG_ 914 OBD_Fehler_Radsensor_VR 0;
BA_ "NWM-WakeupAllowed" SG_ 914 OBD_Fehler_Radsensor_VL 0;
BA_ "NWM-WakeupAllowed" SG_ 914 OBD_Fehler_Radsensor_HR 0;
BA_ "NWM-WakeupAllowed" SG_ 914 OBD_Fehler_Radsensor_HL 0;
BA_ "GenSigSendType" SG_ 906 KL_Sportmodus 3;
BA_ "GenSigSendType" SG_ 906 KL_T_PSM_off 3;
BA_ "GenSigStartValue" SG_ 906 F_Klima_08_PAG_Fwk 1;
BA_ "GenSigStartValue" SG_ 906 F_Klima_03_Ant 1;
BA_ "GenSigStartValue" SG_ 906 F_ESP_11_Ant 1;
BA_ "GenSigStartValue" SG_ 1731 NMH_ESP_Start_1 1;
BA_ "GenSigStartValue" SG_ 1731 NMH_ESP_NM_aktiv_v_groesser_Null 1;
BA_ "Fehlerwert" SG_ 946 BEM_NV_NachladAnf 3;
BA_ "GenSigStartValue" SG_ 946 BEM_NV_NachladAnf 2;
BA_ "NWM-WakeupAllowed" SG_ 946 BEM_NV_NachladAnf 0;
BA_ "NWM-WakeupAllowed" SG_ 946 BEM_Freigabe_HV_Ladung 0;
BA_ "GenSigStartValue" SG_ 946 BEM_HYB_DC_uMinLV 254;
BA_ "GenSigStartValue" SG_ 946 BEM_HYB_DC_uSollLV 37;
BA_ "Fehlerwert" SG_ 1628 BMS_IstSpannung_HV 255;
BA_ "GenSigStartValue" SG_ 1628 BMS_IstSpannung_HV 254;
BA_ "NWM-WakeupAllowed" SG_ 1628 BMS_IstSpannung_HV 0;
BA_ "Fehlerwert" SG_ 1628 BMS_Temperatur_Ansaugluft 255;
BA_ "GenSigStartValue" SG_ 1628 BMS_Temperatur_Ansaugluft 254;
BA_ "NWM-WakeupAllowed" SG_ 1628 BMS_Temperatur_Ansaugluft 0;
BA_ "Fehlerwert" SG_ 1628 BMS_Temperatur 255;
BA_ "GenSigStartValue" SG_ 1628 BMS_Temperatur 254;
BA_ "NWM-WakeupAllowed" SG_ 1628 BMS_Temperatur 0;
BA_ "NWM-WakeupAllowed" SG_ 1628 BMS_HYB_Spuelbetrieb_Status 0;
BA_ "Fehlerwert" SG_ 1628 BMS_HYB_Temp_vor_Verd 255;
BA_ "GenSigStartValue" SG_ 1628 BMS_HYB_Temp_vor_Verd 254;
BA_ "NWM-WakeupAllowed" SG_ 1628 BMS_HYB_Temp_vor_Verd 0;
BA_ "Fehlerwert" SG_ 1628 BMS_HYB_Temp_nach_Verd 255;
BA_ "GenSigStartValue" SG_ 1628 BMS_HYB_Temp_nach_Verd 254;
BA_ "NWM-WakeupAllowed" SG_ 1628 BMS_HYB_Temp_nach_Verd 0;
BA_ "NWM-WakeupAllowed" SG_ 1628 BMS_HYB_Kuehlung_Anf 0;
BA_ "NWM-WakeupAllowed" SG_ 1628 BMS_HYB_ASV_vorne_Status 0;
BA_ "NWM-WakeupAllowed" SG_ 1628 BMS_HYB_ASV_hinten_Status 0;
BA_ "Fehlerwert" SG_ 1628 BMS_HYB_BattFanSpd 15;
BA_ "GenSigStartValue" SG_ 1628 BMS_HYB_BattFanSpd 14;
BA_ "NWM-WakeupAllowed" SG_ 945 DC_TiefsetzBereit 0;
BA_ "Fehlerwert" SG_ 945 DC_HYB_iAktLV 1023;
BA_ "GenSigStartValue" SG_ 945 DC_HYB_iAktLV 1022;
BA_ "Fehlerwert" SG_ 945 DC_HYB_iAktReserveLV 1023;
BA_ "GenSigStartValue" SG_ 945 DC_HYB_iAktReserveLV 1022;
BA_ "Fehlerwert" SG_ 945 DC_HYB_uAktLV 255;
BA_ "GenSigStartValue" SG_ 945 DC_HYB_uAktLV 254;
BA_ "NWM-WakeupAllowed" SG_ 945 DC_Verbrauch_Ueberlauf 0;
BA_ "NWM-WakeupAllowed" SG_ 945 DC_Verbrauch 0;
BA_ "Fehlerwert" SG_ 945 DC_HYB_Auslastungsgrad 255;
BA_ "GenSigStartValue" SG_ 945 DC_HYB_Auslastungsgrad 254;
BA_ "Bemerkung" SG_ 256 ESP_v_Signal "Signal ist eine aus den Radgeschwindigkeiten gebildete Geschwindigkeit";
BA_ "Fehlerwert" SG_ 256 ESP_v_Signal 65535;
BA_ "GenSigStartValue" SG_ 256 ESP_v_Signal 65534;
BA_ "GenSigMissingSourceValue" SG_ 256 ESP_v_Signal 65535;
BA_ "GenSigFuncType" SG_ 256 ESP_01_CHK 4;
BA_ "GenSigFuncType" SG_ 256 ESP_01_BZ 1;
BA_ "Fehlerwert" SG_ 256 ASR_Moment_langsam 1023;
BA_ "GenSigStartValue" SG_ 256 ASR_Moment_langsam 1022;
BA_ "Fehlerwert" SG_ 256 ASR_MSR_Moment_schnell 1023;
BA_ "GenSigStartValue" SG_ 256 ASR_MSR_Moment_schnell 1022;
BA_ "GenSigStartValue" SG_ 256 OBD_QBit_Schlechtweg 1;
BA_ "GenSigStartValue" SG_ 256 ESP_QBit_v_Signal 1;
BA_ "GenSigFuncType" SG_ 257 ESP_02_CHK 4;
BA_ "GenSigFuncType" SG_ 257 ESP_02_BZ 1;
BA_ "GenSigStartValue" SG_ 257 ESP_QBit_Gierrate 1;
BA_ "GenSigStartValue" SG_ 257 ESP_QBit_Laengsbeschl 1;
BA_ "GenSigStartValue" SG_ 257 ESP_QBit_Querb 1;
BA_ "Fehlerwert" SG_ 257 ESP_Querbeschleunigung 255;
BA_ "GenSigStartValue" SG_ 257 ESP_Querbeschleunigung 127;
BA_ "Fehlerwert" SG_ 257 ESP_Laengsbeschl 1023;
BA_ "GenSigStartValue" SG_ 257 ESP_Laengsbeschl 512;
BA_ "Fehlerwert" SG_ 257 ESP_Verteil_Wankmom 31;
BA_ "GenSigStartValue" SG_ 257 ESP_Verteil_Wankmom 30;
BA_ "GenSigStartValue" SG_ 257 ESP_QBit_Anf_Vert_Wank 1;
BA_ "Fehlerwert" SG_ 257 ESP_Gierrate 1023;
BA_ "GenSigSendType" SG_ 1795 ISO_Functionaler_Req_Abgas 7;
BA_ "GenSigFuncType" SG_ 259 ESP_03_CHK 4;
BA_ "GenSigFuncType" SG_ 259 ESP_03_BZ 1;
BA_ "Fehlerwert" SG_ 259 ESP_VL_Radgeschw 4095;
BA_ "GenSigStartValue" SG_ 259 ESP_VL_Radgeschw 4094;
BA_ "Fehlerwert" SG_ 259 ESP_VR_Radgeschw 4095;
BA_ "GenSigStartValue" SG_ 259 ESP_VR_Radgeschw 4094;
BA_ "Fehlerwert" SG_ 259 ESP_HL_Radgeschw 4095;
BA_ "GenSigStartValue" SG_ 259 ESP_HL_Radgeschw 4094;
BA_ "Fehlerwert" SG_ 259 ESP_HR_Radgeschw 4095;
BA_ "GenSigStartValue" SG_ 259 ESP_HR_Radgeschw 4094;
BA_ "NWM-WakeupAllowed" SG_ 776 ESP_HDC_FktLampe 0;
BA_ "NWM-WakeupAllowed" SG_ 776 ESP_ASR_Lampe 0;
BA_ "GenSigStartValue" SG_ 776 ESP_Lampe 1;
BA_ "GenSigStartValue" SG_ 776 ABS_Lampe 1;
BA_ "GenSigStartValue" SG_ 776 BK_Lampe 1;
BA_ "Fehlerwert" SG_ 776 ESP_m_Raddrehz 32767;
BA_ "GenSigStartValue" SG_ 776 ESP_m_Raddrehz 32766;
BA_ "GenSigStartValue" SG_ 776 ESP_QBit_Wegimp_VA 1;
BA_ "Fehlerwert" SG_ 776 ESP_HDC_Regelgeschw 127;
BA_ "GenSigStartValue" SG_ 776 ESP_HDC_Regelgeschw 126;
BA_ "NWM-WakeupAllowed" SG_ 262 ESP_Status_Anfahrhilfe 0;
BA_ "GenSigFuncType" SG_ 262 ESP_05_CHK 3;
BA_ "GenSigFuncType" SG_ 262 ESP_05_BZ 1;
BA_ "GenSigStartValue" SG_ 262 ESP_QBit_Bremsdruck 1;
BA_ "GenSigStartValue" SG_ 262 ESP_QBit_Fahrer_bremst 1;
BA_ "Fehlerwert" SG_ 262 ESP_Bremsdruck 1023;
BA_ "GenSigStartValue" SG_ 262 ESP_Bremsdruck 100;
BA_ "GenSigStartValue" SG_ 262 ECD_nicht_verfuegbar 1;
BA_ "Fehlerwert" SG_ 262 ESP_BKV_Unterdruck 255;
BA_ "GenSigFuncType" SG_ 793 Fahrwerk_02_CHK 4;
BA_ "GenSigFuncType" SG_ 793 Fahrwerk_02_BZ 1;
BA_ "NWM-WakeupAllowed" SG_ 924 KL_Beschlagsgefahr 0;
BA_ "GenSigStartValue" SG_ 924 ESP_07_alt 1;
BA_ "NWM-WakeupAllowed" SG_ 924 ESP_07_alt 0;
BA_ "GenSigFuncType" SG_ 924 ESP_07_alt 5;
BA_ "NWM-WakeupAllowed" SG_ 924 BCM1_GLW_Fernlicht_Anf 0;
BA_ "NWM-WakeupAllowed" SG_ 924 BCM1_Gleitende_Leuchtw_Anf 0;
BA_ "NWM-WakeupAllowed" SG_ 924 BCM1_Adaptive_Lichtvert_Anf 0;
BA_ "NWM-WakeupAllowed" SG_ 924 ESP_Offroad_Modus 0;
BA_ "GenSigSendType" SG_ 924 Wischer_vorne_aktiv 3;
BA_ "GenSigSendType" SG_ 924 HR_Tuer_geoeffnet 3;
BA_ "GenSigSendType" SG_ 924 HL_Tuer_geoeffnet 3;
BA_ "GenSigSendType" SG_ 924 BT_Tuer_geoeffnet 3;
BA_ "GenSigStartValue" SG_ 924 BCM1_02_alt 1;
BA_ "GenSigStartValue" SG_ 924 BCM1_01_alt 1;
BA_ "GenSigSendType" SG_ 924 FT_Tuer_geoeffnet 3;
BA_ "GenSigSendType" SG_ 924 BCM1_MH_WIV_Schalter 3;
BA_ "Fehlerwert" SG_ 924 BCM1_Aussen_Temp_ungef 255;
BA_ "GenSigStartValue" SG_ 924 BCM1_Aussen_Temp_ungef 254;
BA_ "GenSigStartValue" SG_ 924 BCM2_03_PAG_alt 1;
BA_ "GenSigStartValue" SG_ 924 Klima_02_alt 1;
BA_ "GenSigSendType" SG_ 924 KL_Zuheizer_Freigabe 3;
BA_ "GenSigSendType" SG_ 924 BCM_Handshake_STH 3;
BA_ "GenSigStartValue" SG_ 924 Wischer_01_alt 1;
BA_ "GenSigStartValue" SG_ 924 TSG_BT_1_alt 1;
BA_ "GenSigStartValue" SG_ 924 TSG_HL_1_alt 1;
BA_ "GenSigStartValue" SG_ 924 TSG_HR_1_alt 1;
BA_ "GenSigStartValue" SG_ 924 Klima_Sensor_02_alt 1;
BA_ "GenSigStartValue" SG_ 924 TSG_FT_1_alt 1;
BA_ "GenSigStartValue" SG_ 924 Parkhilfe_01_alt 1;
BA_ "GenSigStartValue" SG_ 924 Fahrwerk_02_alt 1;
BA_ "GenSigSendType" SG_ 924 PH_StartStopp_Info 3;
BA_ "GenSigStartValue" SG_ 924 BCM1_Schalter_StartStopp 1;
BA_ "GenSigStartValue" SG_ 1604 ESP_04_alt 1;
BA_ "NWM-WakeupAllowed" SG_ 1604 ESP_04_alt 0;
BA_ "NWM-WakeupAllowed" SG_ 1604 ZV_Tankklappe_offen 0;
BA_ "GenSigSendType" SG_ 1604 ZV_Tankklappe_offen 3;
BA_ "NWM-WakeupAllowed" SG_ 1604 BCM_Tankwunsch 0;
BA_ "GenSigSendType" SG_ 1604 BCM_Tankwunsch 3;
BA_ "GenSigSendType" SG_ 1604 ZV_verriegelt_extern_ist 3;
BA_ "GenSigStartValue" SG_ 1604 BCM2_02_alt 1;
BA_ "GenSigStartValue" SG_ 1604 Kessy_01_alt 1;
BA_ "NWM-WakeupAllowed" SG_ 1604 Kessy_01_alt 0;
BA_ "NWM-WakeupAllowed" SG_ 1604 FFB_CarFinder 0;
BA_ "GenSigActiveRepetitions" SG_ 1604 FFB_CarFinder 10;
BA_ "GenSigSendType" SG_ 1604 FFB_CarFinder 3;
BA_ "GenSigActiveRepetitions" SG_ 1604 FFB_Auf_Taste 10;
BA_ "GenSigSendType" SG_ 1604 FFB_Auf_Taste 3;
BA_ "GenSigStartValue" SG_ 1604 Dummy_Blinkmodi_01_alt 1;
BA_ "GenSigStartValue" SG_ 1604 BCM1_01_alt 1;
BA_ "NWM-WakeupAllowed" SG_ 1604 BCM1_Linksverkehr 0;
BA_ "NWM-WakeupAllowed" SG_ 1604 BCM1_Licht_Dunkelheit_aktiv 0;
BA_ "NWM-WakeupAllowed" SG_ 1604 BCM1_Allwetterlicht_Anf 0;
BA_ "GenSigSendType" SG_ 1604 BCM1_MH_Schalter 3;
BA_ "GenSigSendType" SG_ 1604 BH_Blinker_re 3;
BA_ "GenSigSendType" SG_ 1604 BH_Blinker_li 3;
BA_ "GenSigStartValue" SG_ 1604 SMLS_01_alt 1;
BA_ "GenSigStartValue" SG_ 1604 BCM1_02_alt 1;
BA_ "GenSigStartValue" SG_ 1604 HYB_Anf_E_Mode_alt 1;
BA_ "GenSigSendType" SG_ 1604 HYB_Anf_E_Mode 3;
BA_ "GenSigFuncType" SG_ 130 Getriebe_01_CHK 4;
BA_ "GenSigFuncType" SG_ 130 Getriebe_01_BZ 1;
BA_ "Fehlerwert" SG_ 130 GE_Status_Kupplung 3;
BA_ "Fehlerwert" SG_ 130 GE_MMom_Soll 1023;
BA_ "GenSigStartValue" SG_ 130 GE_MMom_Soll 1022;
BA_ "NWM-WakeupAllowed" SG_ 130 GE_Verbot_Ausblendung 0;
BA_ "Fehlerwert" SG_ 130 GE_MMom_Vorhalt 1023;
BA_ "GenSigStartValue" SG_ 130 GE_MMom_Vorhalt 1022;
BA_ "NWM-WakeupAllowed" SG_ 130 GE_MMom_Vorhalt 0;
BA_ "NWM-WakeupAllowed" SG_ 130 GE_Freig_MMom_Vorhalt 0;
BA_ "NWM-WakeupAllowed" SG_ 131 GE_Anf_Zylabsch 0;
BA_ "GenSigFuncType" SG_ 131 Getriebe_02_CHK 4;
BA_ "GenSigFuncType" SG_ 131 Getriebe_02_BZ 1;
BA_ "Fehlerwert" SG_ 131 GE_Synchro_Wunschdrehz 511;
BA_ "Fehlerwert" SG_ 131 GE_Synchro_Zeit 255;
BA_ "GenSigStartValue" SG_ 131 GE_Mom_Begr_Gradient 255;
BA_ "Fehlerwert" SG_ 131 GE_Anheb_Solldrehz_Leerlauf 255;
BA_ "Fehlerwert" SG_ 131 GE_Vorsteuermoment 511;
BA_ "GenSigStartValue" SG_ 131 GE_Vorsteuermoment 510;
BA_ "Bemerkung" SG_ 258 GE_Waehlhebel "Die im Getriebe aktive Fahrstufe entspricht nicht unter allen Umständen der physikalischen Wählhebelposition.";
BA_ "Fehlerwert" SG_ 258 GE_Waehlhebel 15;
BA_ "GenSigStartValue" SG_ 258 GE_Waehlhebel 1;
BA_ "GenSigMissingSourceValue" SG_ 258 GE_Waehlhebel 15;
BA_ "GenSigFuncType" SG_ 258 Getriebe_03_CHK 4;
BA_ "GenSigFuncType" SG_ 258 Getriebe_03_BZ 1;
BA_ "Fehlerwert" SG_ 258 GE_Uefkt 1023;
BA_ "Fehlerwert" SG_ 258 GE_Zielgang 15;
BA_ "Fehlerwert" SG_ 258 GE_Langfr_Schutzmom 1023;
BA_ "GenSigStartValue" SG_ 258 GE_Langfr_Schutzmom 1022;
BA_ "Fehlerwert" SG_ 258 GE_Eingangsdrehz 16383;
BA_ "GenSigStartValue" SG_ 258 GE_Eingangsdrehz 16382;
BA_REL_ "GenSigTimeoutTime" BU_SG_REL_ GW_Routing_Derivate SG_ 305 MO_ePowermeter 500;
BA_REL_ "GenSigTimeoutTime" BU_SG_REL_ GW_Routing_Derivate SG_ 305 MO_W_Reku_normiert_ueberlauf 500;
BA_REL_ "GenSigTimeoutTime" BU_SG_REL_ Ladegeraet_PAG_PF SG_ 305 Ladezustand 500;
BA_REL_ "GenSigTimeoutTime" BU_SG_REL_ GW_Routing_Derivate SG_ 305 Ladezustand 500;
BA_REL_ "GenSigTimeoutTime" BU_SG_REL_ GW_Applikation_Derivate SG_ 305 Ladezustand 500;
BA_REL_ "GenSigTimeoutTime" BU_SG_REL_ GW_Routing_Derivate SG_ 305 Enrgfluss_State 500;
BA_REL_ "GenSigTimeoutTime" BU_SG_REL_ GW_Routing_Derivate SG_ 305 MO_W_Reku_normiert 500;
BA_REL_ "GenSigTimeoutTime" BU_SG_REL_ GW_Routing_Derivate SG_ 305 MO_Powermeter 500;
BA_REL_ "GenSigTimeoutTime" BU_SG_REL_ Motor_MED17_Hybrid SG_ 914 ESP_07_BZ 800;
BA_REL_ "GenSigTimeoutTime" BU_SG_REL_ Motor_MED17_Hybrid SG_ 914 ESP_07_CHK 800;
BA_REL_ "GenSigTimeoutTime" BU_SG_REL_ Motor_MED17_Hybrid SG_ 914 ESP_OBD_Status 800;
BA_REL_ "GenSigTimeoutTime" BU_SG_REL_ Motor_MED17_Hybrid SG_ 914 OBD_Fehler_Radsensor_VR 800;
BA_REL_ "GenSigTimeoutTime" BU_SG_REL_ Motor_MED17_Hybrid SG_ 914 OBD_Fehler_Radsensor_VL 800;
BA_REL_ "GenSigTimeoutTime" BU_SG_REL_ Motor_MED17_Hybrid SG_ 914 OBD_Fehler_Radsensor_HR 800;
BA_REL_ "GenSigTimeoutTime" BU_SG_REL_ Motor_MED17_Hybrid SG_ 914 OBD_Fehler_Radsensor_HL 800;
BA_REL_ "GenSigTimeoutTime" BU_SG_REL_ Getriebe_Derivate SG_ 906 KL_T_PSM_off 1000;
BA_REL_ "GenSigTimeoutTime" BU_SG_REL_ Motor_EDC17_Pirol SG_ 906 F_Klima_08_PAG_Fwk 1000;
BA_REL_ "GenSigTimeoutTime" BU_SG_REL_ Getriebe_Derivate SG_ 906 F_Klima_08_PAG_Fwk 1000;
BA_REL_ "GenSigTimeoutTime" BU_SG_REL_ Motor_EDC17_Pirol SG_ 906 KL_T_Abgasklappe 1000;
BA_REL_ "GenSigTimeoutTime" BU_SG_REL_ GW_Applikation_Derivate SG_ 1731 NMH_ESP_Start_1 2000;
BA_REL_ "GenSigTimeoutTime" BU_SG_REL_ Getriebe_Derivate SG_ 1731 NMH_ESP_Start_1 2000;
BA_REL_ "GenSigTimeoutTime" BU_SG_REL_ Motor_MED17_Hybrid SG_ 1731 NMH_ESP_Start_1 2000;
BA_REL_ "GenSigTimeoutTime" BU_SG_REL_ Motor_EDC17_Pirol SG_ 1731 NMH_ESP_Start_1 2000;
BA_REL_ "GenSigTimeoutTime" BU_SG_REL_ LEH_Hybrid SG_ 1731 NMH_ESP_Start_1 2000;
BA_REL_ "GenSigTimeoutTime" BU_SG_REL_ Ladegeraet_PAG_PF SG_ 1731 NMH_ESP_Start_1 2000;
BA_REL_ "GenSigTimeoutTime" BU_SG_REL_ BMS_Hybrid SG_ 1731 NMH_ESP_Start_1 2000;
BA_REL_ "GenSigTimeoutTime" BU_SG_REL_ Ladegeraet_PAG_PF SG_ 946 BEM_NV_NachladAnf 1000;
BA_REL_ "GenSigTimeoutTime" BU_SG_REL_ LEH_Hybrid SG_ 946 BEM_HYB_DC_uMinLV 1000;
BA_REL_ "GenSigTimeoutTime" BU_SG_REL_ LEH_Hybrid SG_ 946 BEM_HYB_DC_uSollLV 1000;
BA_REL_ "GenSigTimeoutTime" BU_SG_REL_ GW_Routing_Derivate SG_ 1628 BMS_IstSpannung_HV 5000;
BA_REL_ "GenSigTimeoutTime" BU_SG_REL_ GW_Routing_Derivate SG_ 1628 BMS_Temperatur_Ansaugluft 5000;
BA_REL_ "GenSigTimeoutTime" BU_SG_REL_ GW_Routing_Derivate SG_ 1628 BMS_Temperatur 5000;
BA_REL_ "GenSigTimeoutTime" BU_SG_REL_ GW_Routing_Derivate SG_ 1628 BMS_HYB_Spuelbetrieb_Status 5000;
BA_REL_ "GenSigTimeoutTime" BU_SG_REL_ GW_Routing_Derivate SG_ 1628 BMS_HYB_Temp_vor_Verd 5000;
BA_REL_ "GenSigTimeoutTime" BU_SG_REL_ GW_Routing_Derivate SG_ 1628 BMS_HYB_Temp_nach_Verd 5000;
BA_REL_ "GenSigTimeoutTime" BU_SG_REL_ GW_Applikation_Derivate SG_ 1628 BMS_HYB_Kuehlung_Anf 5000;
BA_REL_ "GenSigTimeoutTime" BU_SG_REL_ GW_Routing_Derivate SG_ 1628 BMS_HYB_Kuehlung_Anf 5000;
BA_REL_ "GenSigTimeoutTime" BU_SG_REL_ GW_Routing_Derivate SG_ 1628 BMS_HYB_ASV_vorne_Status 5000;
BA_REL_ "GenSigTimeoutTime" BU_SG_REL_ GW_Routing_Derivate SG_ 1628 BMS_HYB_ASV_hinten_Status 5000;
BA_REL_ "GenSigTimeoutTime" BU_SG_REL_ GW_Applikation_Derivate SG_ 1628 BMS_HYB_KD_Fehler 5000;
BA_REL_ "GenSigTimeoutTime" BU_SG_REL_ GW_Routing_Derivate SG_ 1628 BMS_HYB_KD_Fehler 5000;
BA_REL_ "GenSigTimeoutTime" BU_SG_REL_ GW_Routing_Derivate SG_ 1628 BMS_HYB_BattFanSpd 5000;
BA_REL_ "GenSigTimeoutTime" BU_SG_REL_ GW_Routing_Derivate SG_ 1628 BMS_HYB_VentilationReq 5000;
BA_REL_ "GenSigTimeoutTime" BU_SG_REL_ Tool SG_ 490 CCP_GE_DTO_01_Data 500;
BA_REL_ "GenSigTimeoutTime" BU_SG_REL_ Tool SG_ 488 CCP_MO_DTO_01_Data 500;
BA_REL_ "GenSigTimeoutTime" BU_SG_REL_ Tool SG_ 2616986625 CCP_MO_DTO_02_Data 500;
BA_REL_ "GenSigTimeoutTime" BU_SG_REL_ GW_Applikation_Derivate SG_ 945 DC_TiefsetzBereit 1000;
BA_REL_ "GenSigTimeoutTime" BU_SG_REL_ GW_Applikation_Derivate SG_ 945 DC_HYB_iAktLV 1000;
BA_REL_ "GenSigTimeoutTime" BU_SG_REL_ GW_Applikation_Derivate SG_ 945 DC_HYB_iAktReserveLV 1000;
BA_REL_ "GenSigTimeoutTime" BU_SG_REL_ GW_Applikation_Derivate SG_ 945 DC_HYB_uAktLV 1000;
BA_REL_ "GenSigTimeoutTime" BU_SG_REL_ GW_Applikation_Derivate SG_ 945 DC_HYB_Abregelung_Temperatur 1000;
BA_REL_ "GenSigTimeoutTime" BU_SG_REL_ GW_Applikation_Derivate SG_ 945 DC_HYB_Fehler_RedLeistung 1000;
BA_REL_ "GenSigTimeoutTime" BU_SG_REL_ GW_Applikation_Derivate SG_ 945 DC_HYB_Fehler_intern 1000;
BA_REL_ "GenSigTimeoutTime" BU_SG_REL_ GW_Applikation_Derivate SG_ 945 DC_HYB_Fehler_Spannung 1000;
BA_REL_ "GenSigTimeoutTime" BU_SG_REL_ GW_Applikation_Derivate SG_ 945 DC_HYB_Auslastungsgrad 1000;
BA_REL_ "GenSigTimeoutTime" BU_SG_REL_ Motor_EDC17_Pirol SG_ 256 ESP_v_Signal 500;
BA_REL_ "GenSigTimeoutTime" BU_SG_REL_ GW_Routing_Derivate SG_ 256 ESP_v_Signal 500;
BA_REL_ "GenSigTimeoutTime" BU_SG_REL_ Getriebe_Derivate SG_ 256 ESP_v_Signal 500;
BA_REL_ "GenSigTimeoutTime" BU_SG_REL_ Motor_MED17_Hybrid SG_ 256 ESP_v_Signal 500;
BA_REL_ "GenSigTimeoutTime" BU_SG_REL_ LEH_Hybrid SG_ 256 ESP_v_Signal 500;
BA_REL_ "GenSigTimeoutTime" BU_SG_REL_ BMS_Hybrid SG_ 256 ESP_v_Signal 500;
BA_REL_ "GenSigTimeoutTime" BU_SG_REL_ GW_Applikation_Derivate SG_ 256 ESP_v_Signal 500;
BA_REL_ "GenSigTimeoutTime" BU_SG_REL_ Motor_EDC17_Pirol SG_ 256 ESP_01_CHK 500;
BA_REL_ "GenSigTimeoutTime" BU_SG_REL_ GW_Routing_Derivate SG_ 256 ESP_01_CHK 500;
BA_REL_ "GenSigTimeoutTime" BU_SG_REL_ BMS_Hybrid SG_ 256 ESP_01_CHK 500;
BA_REL_ "GenSigTimeoutTime" BU_SG_REL_ LEH_Hybrid SG_ 256 ESP_01_CHK 500;
BA_REL_ "GenSigTimeoutTime" BU_SG_REL_ Getriebe_Derivate SG_ 256 ESP_01_CHK 500;
BA_REL_ "GenSigTimeoutTime" BU_SG_REL_ Motor_MED17_Hybrid SG_ 256 ESP_01_CHK 500;
BA_REL_ "GenSigTimeoutTime" BU_SG_REL_ Motor_EDC17_Pirol SG_ 256 ESP_01_BZ 500;
BA_REL_ "GenSigTimeoutTime" BU_SG_REL_ GW_Routing_Derivate SG_ 256 ESP_01_BZ 500;
BA_REL_ "GenSigTimeoutTime" BU_SG_REL_ LEH_Hybrid SG_ 256 ESP_01_BZ 500;
BA_REL_ "GenSigTimeoutTime" BU_SG_REL_ Getriebe_Derivate SG_ 256 ESP_01_BZ 500;
BA_REL_ "GenSigTimeoutTime" BU_SG_REL_ Motor_MED17_Hybrid SG_ 256 ESP_01_BZ 500;
BA_REL_ "GenSigTimeoutTime" BU_SG_REL_ BMS_Hybrid SG_ 256 ESP_01_BZ 500;
BA_REL_ "GenSigTimeoutTime" BU_SG_REL_ Motor_EDC17_Pirol SG_ 256 ASR_Moment_langsam 500;
BA_REL_ "GenSigTimeoutTime" BU_SG_REL_ GW_Routing_Derivate SG_ 256 ASR_Moment_langsam 500;
BA_REL_ "GenSigTimeoutTime" BU_SG_REL_ Motor_MED17_Hybrid SG_ 256 ASR_Moment_langsam 500;
BA_REL_ "GenSigTimeoutTime" BU_SG_REL_ Motor_EDC17_Pirol SG_ 256 ASR_MSR_Moment_schnell 500;
BA_REL_ "GenSigTimeoutTime" BU_SG_REL_ GW_Routing_Derivate SG_ 256 ASR_MSR_Moment_schnell 500;
BA_REL_ "GenSigTimeoutTime" BU_SG_REL_ Motor_MED17_Hybrid SG_ 256 ASR_MSR_Moment_schnell 500;
BA_REL_ "GenSigTimeoutTime" BU_SG_REL_ Motor_EDC17_Pirol SG_ 256 ASR_Tastung_passiv 500;
BA_REL_ "GenSigTimeoutTime" BU_SG_REL_ GW_Routing_Derivate SG_ 256 ASR_Tastung_passiv 500;
BA_REL_ "GenSigTimeoutTime" BU_SG_REL_ Getriebe_Derivate SG_ 256 ASR_Tastung_passiv 500;
BA_REL_ "GenSigTimeoutTime" BU_SG_REL_ Motor_MED17_Hybrid SG_ 256 ASR_Tastung_passiv 500;
BA_REL_ "GenSigTimeoutTime" BU_SG_REL_ Motor_EDC17_Pirol SG_ 256 ESP_Tastung_passiv 500;
BA_REL_ "GenSigTimeoutTime" BU_SG_REL_ GW_Routing_Derivate SG_ 256 ESP_Tastung_passiv 500;
BA_REL_ "GenSigTimeoutTime" BU_SG_REL_ Getriebe_Derivate SG_ 256 ESP_Tastung_passiv 500;
BA_REL_ "GenSigTimeoutTime" BU_SG_REL_ Motor_MED17_Hybrid SG_ 256 ESP_Tastung_passiv 500;
BA_REL_ "GenSigTimeoutTime" BU_SG_REL_ Motor_EDC17_Pirol SG_ 256 ESP_Systemstatus 500;
BA_REL_ "GenSigTimeoutTime" BU_SG_REL_ GW_Routing_Derivate SG_ 256 ESP_Systemstatus 500;
BA_REL_ "GenSigTimeoutTime" BU_SG_REL_ Motor_MED17_Hybrid SG_ 256 ESP_Systemstatus 500;
BA_REL_ "GenSigTimeoutTime" BU_SG_REL_ Getriebe_Derivate SG_ 256 ESP_Systemstatus 500;
BA_REL_ "GenSigTimeoutTime" BU_SG_REL_ GW_Routing_Derivate SG_ 256 ASR_Schalteingriff 500;
BA_REL_ "GenSigTimeoutTime" BU_SG_REL_ Getriebe_Derivate SG_ 256 ASR_Schalteingriff 500;
BA_REL_ "GenSigTimeoutTime" BU_SG_REL_ GW_Routing_Derivate SG_ 256 OBD_Schlechtweg 500;
BA_REL_ "GenSigTimeoutTime" BU_SG_REL_ GW_Routing_Derivate SG_ 256 OBD_QBit_Schlechtweg 500;
BA_REL_ "GenSigTimeoutTime" BU_SG_REL_ BMS_Hybrid SG_ 256 ESP_QBit_v_Signal 500;
BA_REL_ "GenSigTimeoutTime" BU_SG_REL_ Motor_EDC17_Pirol SG_ 256 ESP_QBit_v_Signal 500;
BA_REL_ "GenSigTimeoutTime" BU_SG_REL_ GW_Routing_Derivate SG_ 256 ESP_QBit_v_Signal 500;
BA_REL_ "GenSigTimeoutTime" BU_SG_REL_ LEH_Hybrid SG_ 256 ESP_QBit_v_Signal 500;
BA_REL_ "GenSigTimeoutTime" BU_SG_REL_ Motor_MED17_Hybrid SG_ 256 ESP_QBit_v_Signal 500;
BA_REL_ "GenSigTimeoutTime" BU_SG_REL_ Motor_EDC17_Pirol SG_ 256 ABS_Bremsung 500;
BA_REL_ "GenSigTimeoutTime" BU_SG_REL_ GW_Routing_Derivate SG_ 256 ABS_Bremsung 500;
BA_REL_ "GenSigTimeoutTime" BU_SG_REL_ Getriebe_Derivate SG_ 256 ABS_Bremsung 500;
BA_REL_ "GenSigTimeoutTime" BU_SG_REL_ Motor_MED17_Hybrid SG_ 256 ABS_Bremsung 500;
BA_REL_ "GenSigTimeoutTime" BU_SG_REL_ Motor_EDC17_Pirol SG_ 256 ASR_Anf 500;
BA_REL_ "GenSigTimeoutTime" BU_SG_REL_ GW_Routing_Derivate SG_ 256 ASR_Anf 500;
BA_REL_ "GenSigTimeoutTime" BU_SG_REL_ Getriebe_Derivate SG_ 256 ASR_Anf 500;
BA_REL_ "GenSigTimeoutTime" BU_SG_REL_ Motor_MED17_Hybrid SG_ 256 ASR_Anf 500;
BA_REL_ "GenSigTimeoutTime" BU_SG_REL_ Motor_EDC17_Pirol SG_ 256 MSR_Anf 500;
BA_REL_ "GenSigTimeoutTime" BU_SG_REL_ GW_Routing_Derivate SG_ 256 MSR_Anf 500;
BA_REL_ "GenSigTimeoutTime" BU_SG_REL_ Getriebe_Derivate SG_ 256 MSR_Anf 500;
BA_REL_ "GenSigTimeoutTime" BU_SG_REL_ Motor_MED17_Hybrid SG_ 256 MSR_Anf 500;
BA_REL_ "GenSigTimeoutTime" BU_SG_REL_ Motor_EDC17_Pirol SG_ 256 EBV_Eingriff 500;
BA_REL_ "GenSigTimeoutTime" BU_SG_REL_ GW_Routing_Derivate SG_ 256 EBV_Eingriff 500;
BA_REL_ "GenSigTimeoutTime" BU_SG_REL_ Motor_MED17_Hybrid SG_ 256 EBV_Eingriff 500;
BA_REL_ "GenSigTimeoutTime" BU_SG_REL_ Motor_EDC17_Pirol SG_ 256 EDS_Eingriff 500;
BA_REL_ "GenSigTimeoutTime" BU_SG_REL_ GW_Routing_Derivate SG_ 256 EDS_Eingriff 500;
BA_REL_ "GenSigTimeoutTime" BU_SG_REL_ Getriebe_Derivate SG_ 256 EDS_Eingriff 500;
BA_REL_ "GenSigTimeoutTime" BU_SG_REL_ Motor_MED17_Hybrid SG_ 256 EDS_Eingriff 500;
BA_REL_ "GenSigTimeoutTime" BU_SG_REL_ Motor_EDC17_Pirol SG_ 256 ESP_Eingriff 500;
BA_REL_ "GenSigTimeoutTime" BU_SG_REL_ GW_Routing_Derivate SG_ 256 ESP_Eingriff 500;
BA_REL_ "GenSigTimeoutTime" BU_SG_REL_ Getriebe_Derivate SG_ 256 ESP_Eingriff 500;
BA_REL_ "GenSigTimeoutTime" BU_SG_REL_ Motor_MED17_Hybrid SG_ 256 ESP_Eingriff 500;
BA_REL_ "GenSigTimeoutTime" BU_SG_REL_ Motor_EDC17_Pirol SG_ 256 ESP_ASP 500;
BA_REL_ "GenSigTimeoutTime" BU_SG_REL_ GW_Routing_Derivate SG_ 256 ESP_ASP 500;
BA_REL_ "GenSigTimeoutTime" BU_SG_REL_ Motor_MED17_Hybrid SG_ 256 ESP_ASP 500;
BA_REL_ "GenSigTimeoutTime" BU_SG_REL_ GW_Applikation_Derivate SG_ 256 ESP_KD_Fehler 500;
BA_REL_ "GenSigTimeoutTime" BU_SG_REL_ GW_Routing_Derivate SG_ 256 ESP_KD_Fehler 500;
BA_REL_ "GenSigTimeoutTime" BU_SG_REL_ Motor_EDC17_Pirol SG_ 257 ESP_02_CHK 500;
BA_REL_ "GenSigTimeoutTime" BU_SG_REL_ GW_Routing_Derivate SG_ 257 ESP_02_CHK 500;
BA_REL_ "GenSigTimeoutTime" BU_SG_REL_ Getriebe_Derivate SG_ 257 ESP_02_CHK 500;
BA_REL_ "GenSigTimeoutTime" BU_SG_REL_ Motor_MED17_Hybrid SG_ 257 ESP_02_CHK 500;
BA_REL_ "GenSigTimeoutTime" BU_SG_REL_ Motor_EDC17_Pirol SG_ 257 ESP_02_BZ 500;
BA_REL_ "GenSigTimeoutTime" BU_SG_REL_ GW_Routing_Derivate SG_ 257 ESP_02_BZ 500;
BA_REL_ "GenSigTimeoutTime" BU_SG_REL_ Getriebe_Derivate SG_ 257 ESP_02_BZ 500;
BA_REL_ "GenSigTimeoutTime" BU_SG_REL_ Motor_MED17_Hybrid SG_ 257 ESP_02_BZ 500;
BA_REL_ "GenSigTimeoutTime" BU_SG_REL_ GW_Routing_Derivate SG_ 257 ESP_QBit_Gierrate 500;
BA_REL_ "GenSigTimeoutTime" BU_SG_REL_ Motor_EDC17_Pirol SG_ 257 ESP_QBit_Laengsbeschl 500;
BA_REL_ "GenSigTimeoutTime" BU_SG_REL_ GW_Routing_Derivate SG_ 257 ESP_QBit_Laengsbeschl 500;
BA_REL_ "GenSigTimeoutTime" BU_SG_REL_ Motor_MED17_Hybrid SG_ 257 ESP_QBit_Laengsbeschl 500;
BA_REL_ "GenSigTimeoutTime" BU_SG_REL_ Motor_EDC17_Pirol SG_ 257 ESP_QBit_Querb 500;
BA_REL_ "GenSigTimeoutTime" BU_SG_REL_ GW_Routing_Derivate SG_ 257 ESP_QBit_Querb 500;
BA_REL_ "GenSigTimeoutTime" BU_SG_REL_ Motor_MED17_Hybrid SG_ 257 ESP_QBit_Querb 500;
BA_REL_ "GenSigTimeoutTime" BU_SG_REL_ Motor_EDC17_Pirol SG_ 257 ESP_Stillstandsflag 500;
BA_REL_ "GenSigTimeoutTime" BU_SG_REL_ GW_Routing_Derivate SG_ 257 ESP_Stillstandsflag 500;
BA_REL_ "GenSigTimeoutTime" BU_SG_REL_ Motor_MED17_Hybrid SG_ 257 ESP_Stillstandsflag 500;
BA_REL_ "GenSigTimeoutTime" BU_SG_REL_ Motor_EDC17_Pirol SG_ 257 ESP_Querbeschleunigung 500;
BA_REL_ "GenSigTimeoutTime" BU_SG_REL_ GW_Routing_Derivate SG_ 257 ESP_Querbeschleunigung 500;
BA_REL_ "GenSigTimeoutTime" BU_SG_REL_ Getriebe_Derivate SG_ 257 ESP_Querbeschleunigung 500;
BA_REL_ "GenSigTimeoutTime" BU_SG_REL_ Motor_MED17_Hybrid SG_ 257 ESP_Querbeschleunigung 500;
BA_REL_ "GenSigTimeoutTime" BU_SG_REL_ Motor_EDC17_Pirol SG_ 257 ESP_Laengsbeschl 500;
BA_REL_ "GenSigTimeoutTime" BU_SG_REL_ GW_Routing_Derivate SG_ 257 ESP_Laengsbeschl 500;
BA_REL_ "GenSigTimeoutTime" BU_SG_REL_ Getriebe_Derivate SG_ 257 ESP_Laengsbeschl 500;
BA_REL_ "GenSigTimeoutTime" BU_SG_REL_ Motor_MED17_Hybrid SG_ 257 ESP_Laengsbeschl 500;
BA_REL_ "GenSigTimeoutTime" BU_SG_REL_ GW_Routing_Derivate SG_ 257 ESP_Verteil_Wankmom 500;
BA_REL_ "GenSigTimeoutTime" BU_SG_REL_ GW_Routing_Derivate SG_ 257 ESP_QBit_Anf_Vert_Wank 500;
BA_REL_ "GenSigTimeoutTime" BU_SG_REL_ GW_Routing_Derivate SG_ 257 ESP_Gierrate 500;
BA_REL_ "GenSigTimeoutTime" BU_SG_REL_ GW_Routing_Derivate SG_ 257 ESP_VZ_Gierrate 500;
BA_REL_ "GenSigTimeoutTime" BU_SG_REL_ GW_Routing_Derivate SG_ 257 ESP_Notbremsanzeige 500;
BA_REL_ "GenSigTimeoutTime" BU_SG_REL_ GW_Routing_Derivate SG_ 257 ESP_SpannungsAnf 500;
BA_REL_ "GenSigTimeoutTime" BU_SG_REL_ Ladegeraet_PAG_PF SG_ 1795 ISO_Functionaler_Req_Abgas 500;
BA_REL_ "GenSigTimeoutTime" BU_SG_REL_ BMS_Hybrid SG_ 1795 ISO_Functionaler_Req_Abgas 500;
BA_REL_ "GenSigTimeoutTime" BU_SG_REL_ Motor_EDC17_Pirol SG_ 1795 ISO_Functionaler_Req_Abgas 500;
BA_REL_ "GenSigTimeoutTime" BU_SG_REL_ Motor_MED17_Hybrid SG_ 1795 ISO_Functionaler_Req_Abgas 500;
BA_REL_ "GenSigTimeoutTime" BU_SG_REL_ Getriebe_Derivate SG_ 1795 ISO_Functionaler_Req_Abgas 500;
BA_REL_ "GenSigTimeoutTime" BU_SG_REL_ LEH_Hybrid SG_ 1795 ISO_Functionaler_Req_Abgas 500;
BA_REL_ "GenSigTimeoutTime" BU_SG_REL_ Getriebe_Derivate SG_ 482 CCP_GE_CRO_01_Data 500;
BA_REL_ "GenSigTimeoutTime" BU_SG_REL_ Motor_EDC17_Pirol SG_ 259 ESP_03_CHK 500;
BA_REL_ "GenSigTimeoutTime" BU_SG_REL_ GW_Routing_Derivate SG_ 259 ESP_03_CHK 500;
BA_REL_ "GenSigTimeoutTime" BU_SG_REL_ Getriebe_Derivate SG_ 259 ESP_03_CHK 500;
BA_REL_ "GenSigTimeoutTime" BU_SG_REL_ Motor_MED17_Hybrid SG_ 259 ESP_03_CHK 500;
BA_REL_ "GenSigTimeoutTime" BU_SG_REL_ Motor_EDC17_Pirol SG_ 259 ESP_03_BZ 500;
BA_REL_ "GenSigTimeoutTime" BU_SG_REL_ GW_Routing_Derivate SG_ 259 ESP_03_BZ 500;
BA_REL_ "GenSigTimeoutTime" BU_SG_REL_ Getriebe_Derivate SG_ 259 ESP_03_BZ 500;
BA_REL_ "GenSigTimeoutTime" BU_SG_REL_ Motor_MED17_Hybrid SG_ 259 ESP_03_BZ 500;
BA_REL_ "GenSigTimeoutTime" BU_SG_REL_ Motor_EDC17_Pirol SG_ 259 ESP_VL_FR 500;
BA_REL_ "GenSigTimeoutTime" BU_SG_REL_ GW_Routing_Derivate SG_ 259 ESP_VL_FR 500;
BA_REL_ "GenSigTimeoutTime" BU_SG_REL_ Getriebe_Derivate SG_ 259 ESP_VL_FR 500;
BA_REL_ "GenSigTimeoutTime" BU_SG_REL_ Motor_MED17_Hybrid SG_ 259 ESP_VL_FR 500;
BA_REL_ "GenSigTimeoutTime" BU_SG_REL_ Motor_EDC17_Pirol SG_ 259 ESP_VR_FR 500;
BA_REL_ "GenSigTimeoutTime" BU_SG_REL_ GW_Routing_Derivate SG_ 259 ESP_VR_FR 500;
BA_REL_ "GenSigTimeoutTime" BU_SG_REL_ Getriebe_Derivate SG_ 259 ESP_VR_FR 500;
BA_REL_ "GenSigTimeoutTime" BU_SG_REL_ Motor_MED17_Hybrid SG_ 259 ESP_VR_FR 500;
BA_REL_ "GenSigTimeoutTime" BU_SG_REL_ Motor_EDC17_Pirol SG_ 259 ESP_HL_FR 500;
BA_REL_ "GenSigTimeoutTime" BU_SG_REL_ GW_Routing_Derivate SG_ 259 ESP_HL_FR 500;
BA_REL_ "GenSigTimeoutTime" BU_SG_REL_ Getriebe_Derivate SG_ 259 ESP_HL_FR 500;
BA_REL_ "GenSigTimeoutTime" BU_SG_REL_ Motor_MED17_Hybrid SG_ 259 ESP_HL_FR 500;
BA_REL_ "GenSigTimeoutTime" BU_SG_REL_ Motor_EDC17_Pirol SG_ 259 ESP_HR_FR 500;
BA_REL_ "GenSigTimeoutTime" BU_SG_REL_ GW_Routing_Derivate SG_ 259 ESP_HR_FR 500;
BA_REL_ "GenSigTimeoutTime" BU_SG_REL_ Getriebe_Derivate SG_ 259 ESP_HR_FR 500;
BA_REL_ "GenSigTimeoutTime" BU_SG_REL_ Motor_MED17_Hybrid SG_ 259 ESP_HR_FR 500;
BA_REL_ "GenSigTimeoutTime" BU_SG_REL_ Motor_MED17_Hybrid SG_ 259 ESP_VL_Radgeschw 500;
BA_REL_ "GenSigTimeoutTime" BU_SG_REL_ GW_Routing_Derivate SG_ 259 ESP_VL_Radgeschw 500;
BA_REL_ "GenSigTimeoutTime" BU_SG_REL_ Motor_EDC17_Pirol SG_ 259 ESP_VL_Radgeschw 500;
BA_REL_ "GenSigTimeoutTime" BU_SG_REL_ Getriebe_Derivate SG_ 259 ESP_VL_Radgeschw 500;
BA_REL_ "GenSigTimeoutTime" BU_SG_REL_ Motor_MED17_Hybrid SG_ 259 ESP_VR_Radgeschw 500;
BA_REL_ "GenSigTimeoutTime" BU_SG_REL_ GW_Routing_Derivate SG_ 259 ESP_VR_Radgeschw 500;
BA_REL_ "GenSigTimeoutTime" BU_SG_REL_ Motor_EDC17_Pirol SG_ 259 ESP_VR_Radgeschw 500;
BA_REL_ "GenSigTimeoutTime" BU_SG_REL_ Getriebe_Derivate SG_ 259 ESP_VR_Radgeschw 500;
BA_REL_ "GenSigTimeoutTime" BU_SG_REL_ Motor_MED17_Hybrid SG_ 259 ESP_HL_Radgeschw 500;
BA_REL_ "GenSigTimeoutTime" BU_SG_REL_ GW_Routing_Derivate SG_ 259 ESP_HL_Radgeschw 500;
BA_REL_ "GenSigTimeoutTime" BU_SG_REL_ Motor_EDC17_Pirol SG_ 259 ESP_HL_Radgeschw 500;
BA_REL_ "GenSigTimeoutTime" BU_SG_REL_ Getriebe_Derivate SG_ 259 ESP_HL_Radgeschw 500;
BA_REL_ "GenSigTimeoutTime" BU_SG_REL_ Motor_MED17_Hybrid SG_ 259 ESP_HR_Radgeschw 500;
BA_REL_ "GenSigTimeoutTime" BU_SG_REL_ Motor_EDC17_Pirol SG_ 259 ESP_HR_Radgeschw 500;
BA_REL_ "GenSigTimeoutTime" BU_SG_REL_ GW_Routing_Derivate SG_ 259 ESP_HR_Radgeschw 500;
BA_REL_ "GenSigTimeoutTime" BU_SG_REL_ Getriebe_Derivate SG_ 259 ESP_HR_Radgeschw 500;
BA_REL_ "GenSigTimeoutTime" BU_SG_REL_ GW_Routing_Derivate SG_ 776 ESP_Diagnose 500;
BA_REL_ "GenSigTimeoutTime" BU_SG_REL_ GW_Applikation_Derivate SG_ 776 ESP_Diagnose 500;
BA_REL_ "GenSigTimeoutTime" BU_SG_REL_ Getriebe_Derivate SG_ 776 ESP_Wegimp_VA 500;
BA_REL_ "GenSigTimeoutTime" BU_SG_REL_ Getriebe_Derivate SG_ 776 ESP_Zaehnezahl 500;
BA_REL_ "GenSigTimeoutTime" BU_SG_REL_ Motor_EDC17_Pirol SG_ 262 ESP_Status_Anfahrhilfe 500;
BA_REL_ "GenSigTimeoutTime" BU_SG_REL_ Motor_MED17_Hybrid SG_ 262 ESP_Status_Anfahrhilfe 500;
BA_REL_ "GenSigTimeoutTime" BU_SG_REL_ GW_Routing_Derivate SG_ 262 ESP_Status_Anfahrhilfe 500;
BA_REL_ "GenSigTimeoutTime" BU_SG_REL_ GW_Routing_Derivate SG_ 262 ESP_Anforderung_EPB 500;
BA_REL_ "GenSigTimeoutTime" BU_SG_REL_ GW_Routing_Derivate SG_ 262 ESP_Lenkeingriff_ADS 500;
BA_REL_ "GenSigTimeoutTime" BU_SG_REL_ GW_Routing_Derivate SG_ 262 ESP_Bremsruck_AWV2 500;
BA_REL_ "GenSigTimeoutTime" BU_SG_REL_ GW_Routing_Derivate SG_ 262 ESP_Konsistenz_AWV2 500;
BA_REL_ "GenSigTimeoutTime" BU_SG_REL_ Motor_EDC17_Pirol SG_ 262 ESP_05_CHK 500;
BA_REL_ "GenSigTimeoutTime" BU_SG_REL_ Motor_MED17_Hybrid SG_ 262 ESP_05_CHK 500;
BA_REL_ "GenSigTimeoutTime" BU_SG_REL_ GW_Routing_Derivate SG_ 262 ESP_05_CHK 500;
BA_REL_ "GenSigTimeoutTime" BU_SG_REL_ Getriebe_Derivate SG_ 262 ESP_05_CHK 500;
BA_REL_ "GenSigTimeoutTime" BU_SG_REL_ Motor_EDC17_Pirol SG_ 262 ESP_05_BZ 500;
BA_REL_ "GenSigTimeoutTime" BU_SG_REL_ Motor_MED17_Hybrid SG_ 262 ESP_05_BZ 500;
BA_REL_ "GenSigTimeoutTime" BU_SG_REL_ GW_Routing_Derivate SG_ 262 ESP_05_BZ 500;
BA_REL_ "GenSigTimeoutTime" BU_SG_REL_ Getriebe_Derivate SG_ 262 ESP_05_BZ 500;
BA_REL_ "GenSigTimeoutTime" BU_SG_REL_ Motor_EDC17_Pirol SG_ 262 ESP_QBit_Bremsdruck 500;
BA_REL_ "GenSigTimeoutTime" BU_SG_REL_ Motor_MED17_Hybrid SG_ 262 ESP_QBit_Bremsdruck 500;
BA_REL_ "GenSigTimeoutTime" BU_SG_REL_ GW_Routing_Derivate SG_ 262 ESP_QBit_Bremsdruck 500;
BA_REL_ "GenSigTimeoutTime" BU_SG_REL_ Getriebe_Derivate SG_ 262 ESP_QBit_Bremsdruck 500;
BA_REL_ "GenSigTimeoutTime" BU_SG_REL_ Motor_EDC17_Pirol SG_ 262 ESP_QBit_Fahrer_bremst 500;
BA_REL_ "GenSigTimeoutTime" BU_SG_REL_ Motor_MED17_Hybrid SG_ 262 ESP_QBit_Fahrer_bremst 500;
BA_REL_ "GenSigTimeoutTime" BU_SG_REL_ GW_Routing_Derivate SG_ 262 ESP_QBit_Fahrer_bremst 500;
BA_REL_ "GenSigTimeoutTime" BU_SG_REL_ Motor_EDC17_Pirol SG_ 262 ESP_Schwelle_Unterdruck 500;
BA_REL_ "GenSigTimeoutTime" BU_SG_REL_ Motor_MED17_Hybrid SG_ 262 ESP_Schwelle_Unterdruck 500;
BA_REL_ "GenSigTimeoutTime" BU_SG_REL_ GW_Routing_Derivate SG_ 262 ESP_Schwelle_Unterdruck 500;
BA_REL_ "GenSigTimeoutTime" BU_SG_REL_ Motor_EDC17_Pirol SG_ 262 ESP_Bremsdruck 500;
BA_REL_ "GenSigTimeoutTime" BU_SG_REL_ Motor_MED17_Hybrid SG_ 262 ESP_Bremsdruck 500;
BA_REL_ "GenSigTimeoutTime" BU_SG_REL_ GW_Routing_Derivate SG_ 262 ESP_Bremsdruck 500;
BA_REL_ "GenSigTimeoutTime" BU_SG_REL_ Getriebe_Derivate SG_ 262 ESP_Bremsdruck 500;
BA_REL_ "GenSigTimeoutTime" BU_SG_REL_ Motor_EDC17_Pirol SG_ 262 ESP_Fahrer_bremst 500;
BA_REL_ "GenSigTimeoutTime" BU_SG_REL_ Motor_MED17_Hybrid SG_ 262 ESP_Fahrer_bremst 500;
BA_REL_ "GenSigTimeoutTime" BU_SG_REL_ GW_Routing_Derivate SG_ 262 ESP_Fahrer_bremst 500;
BA_REL_ "GenSigTimeoutTime" BU_SG_REL_ Motor_EDC17_Pirol SG_ 262 ESP_Verz_TSK_aktiv 500;
BA_REL_ "GenSigTimeoutTime" BU_SG_REL_ Getriebe_Derivate SG_ 262 ESP_Verz_TSK_aktiv 500;
BA_REL_ "GenSigTimeoutTime" BU_SG_REL_ Motor_MED17_Hybrid SG_ 262 ESP_Verz_TSK_aktiv 500;
BA_REL_ "GenSigTimeoutTime" BU_SG_REL_ GW_Routing_Derivate SG_ 262 ESP_Verz_TSK_aktiv 500;
BA_REL_ "GenSigTimeoutTime" BU_SG_REL_ Motor_EDC17_Pirol SG_ 262 ESP_Konsistenz_TSK 500;
BA_REL_ "GenSigTimeoutTime" BU_SG_REL_ Motor_MED17_Hybrid SG_ 262 ESP_Konsistenz_TSK 500;
BA_REL_ "GenSigTimeoutTime" BU_SG_REL_ GW_Routing_Derivate SG_ 262 ESP_Konsistenz_TSK 500;
BA_REL_ "GenSigTimeoutTime" BU_SG_REL_ Motor_EDC17_Pirol SG_ 262 ECD_Fehler 500;
BA_REL_ "GenSigTimeoutTime" BU_SG_REL_ Motor_MED17_Hybrid SG_ 262 ECD_Fehler 500;
BA_REL_ "GenSigTimeoutTime" BU_SG_REL_ GW_Routing_Derivate SG_ 262 ECD_Fehler 500;
BA_REL_ "GenSigTimeoutTime" BU_SG_REL_ Motor_EDC17_Pirol SG_ 262 ECD_nicht_verfuegbar 500;
BA_REL_ "GenSigTimeoutTime" BU_SG_REL_ Motor_MED17_Hybrid SG_ 262 ECD_nicht_verfuegbar 500;
BA_REL_ "GenSigTimeoutTime" BU_SG_REL_ GW_Routing_Derivate SG_ 262 ECD_nicht_verfuegbar 500;
BA_REL_ "GenSigTimeoutTime" BU_SG_REL_ Motor_EDC17_Pirol SG_ 262 ESP_Status_Bremsentemp 500;
BA_REL_ "GenSigTimeoutTime" BU_SG_REL_ Motor_MED17_Hybrid SG_ 262 ESP_Status_Bremsentemp 500;
BA_REL_ "GenSigTimeoutTime" BU_SG_REL_ GW_Routing_Derivate SG_ 262 ESP_Status_Bremsentemp 500;
BA_REL_ "GenSigTimeoutTime" BU_SG_REL_ GW_Routing_Derivate SG_ 262 ESP_Autohold_Standby 500;
BA_REL_ "GenSigTimeoutTime" BU_SG_REL_ Motor_EDC17_Pirol SG_ 262 ESP_HDC_Standby 500;
BA_REL_ "GenSigTimeoutTime" BU_SG_REL_ Motor_MED17_Hybrid SG_ 262 ESP_HDC_Standby 500;
BA_REL_ "GenSigTimeoutTime" BU_SG_REL_ GW_Routing_Derivate SG_ 262 ESP_HDC_Standby 500;
BA_REL_ "GenSigTimeoutTime" BU_SG_REL_ GW_Routing_Derivate SG_ 262 ESP_HBA_aktiv 500;
BA_REL_ "GenSigTimeoutTime" BU_SG_REL_ GW_Routing_Derivate SG_ 262 ESP_Prefill_ausgeloest 500;
BA_REL_ "GenSigTimeoutTime" BU_SG_REL_ GW_Routing_Derivate SG_ 262 ESP_Rueckwaertsfahrt_erkannt 500;
BA_REL_ "GenSigTimeoutTime" BU_SG_REL_ Motor_EDC17_Pirol SG_ 262 ESP_StartStopp_Info 500;
BA_REL_ "GenSigTimeoutTime" BU_SG_REL_ Motor_MED17_Hybrid SG_ 262 ESP_StartStopp_Info 500;
BA_REL_ "GenSigTimeoutTime" BU_SG_REL_ GW_Routing_Derivate SG_ 262 ESP_StartStopp_Info 500;
BA_REL_ "GenSigTimeoutTime" BU_SG_REL_ GW_Routing_Derivate SG_ 262 ESP_Eingr_HL 500;
BA_REL_ "GenSigTimeoutTime" BU_SG_REL_ GW_Routing_Derivate SG_ 262 ESP_Eingr_HR 500;
BA_REL_ "GenSigTimeoutTime" BU_SG_REL_ GW_Routing_Derivate SG_ 262 ESP_Eingr_VL 500;
BA_REL_ "GenSigTimeoutTime" BU_SG_REL_ GW_Routing_Derivate SG_ 262 ESP_Eingr_VR 500;
BA_REL_ "GenSigTimeoutTime" BU_SG_REL_ Motor_EDC17_Pirol SG_ 262 ESP_BKV_Unterdruck 500;
BA_REL_ "GenSigTimeoutTime" BU_SG_REL_ Motor_MED17_Hybrid SG_ 262 ESP_BKV_Unterdruck 500;
BA_REL_ "GenSigTimeoutTime" BU_SG_REL_ GW_Routing_Derivate SG_ 262 ESP_BKV_Unterdruck 500;
BA_REL_ "GenSigTimeoutTime" BU_SG_REL_ Motor_EDC17_Pirol SG_ 262 ESP_Autohold_aktiv 500;
BA_REL_ "GenSigTimeoutTime" BU_SG_REL_ Motor_MED17_Hybrid SG_ 262 ESP_Autohold_aktiv 500;
BA_REL_ "GenSigTimeoutTime" BU_SG_REL_ GW_Routing_Derivate SG_ 262 ESP_Autohold_aktiv 500;
BA_REL_ "GenSigTimeoutTime" BU_SG_REL_ GW_Routing_Derivate SG_ 262 ESP_FStatus_Anfahrhilfe 500;
BA_REL_ "GenSigTimeoutTime" BU_SG_REL_ GW_Routing_Derivate SG_ 262 ESP_Verz_EPB_aktiv 500;
BA_REL_ "GenSigTimeoutTime" BU_SG_REL_ Getriebe_Derivate SG_ 262 ESP_Verz_EPB_aktiv 500;
BA_REL_ "GenSigTimeoutTime" BU_SG_REL_ Motor_EDC17_Pirol SG_ 262 ECD_Bremslicht 500;
BA_REL_ "GenSigTimeoutTime" BU_SG_REL_ Motor_MED17_Hybrid SG_ 262 ECD_Bremslicht 500;
BA_REL_ "GenSigTimeoutTime" BU_SG_REL_ GW_Routing_Derivate SG_ 262 ECD_Bremslicht 500;
BA_REL_ "GenSigTimeoutTime" BU_SG_REL_ GW_Routing_Derivate SG_ 262 ESP_Verzoeg_EPB_verf 500;
BA_REL_ "GenSigTimeoutTime" BU_SG_REL_ Motor_EDC17_Pirol SG_ 262 ESP_Status_Bremsdruck 500;
BA_REL_ "GenSigTimeoutTime" BU_SG_REL_ Motor_MED17_Hybrid SG_ 262 ESP_Status_Bremsdruck 500;
BA_REL_ "GenSigTimeoutTime" BU_SG_REL_ GW_Routing_Derivate SG_ 262 ESP_Status_Bremsdruck 500;
BA_REL_ "GenSigTimeoutTime" BU_SG_REL_ Motor_EDC17_Pirol SG_ 793 Fahrwerk_02_CHK 500;
BA_REL_ "GenSigTimeoutTime" BU_SG_REL_ Motor_MED17_Hybrid SG_ 793 Fahrwerk_02_CHK 500;
BA_REL_ "GenSigTimeoutTime" BU_SG_REL_ Motor_EDC17_Pirol SG_ 793 Fahrwerk_02_BZ 500;
BA_REL_ "GenSigTimeoutTime" BU_SG_REL_ Motor_MED17_Hybrid SG_ 793 Fahrwerk_02_BZ 500;
BA_REL_ "GenSigTimeoutTime" BU_SG_REL_ Motor_EDC17_Pirol SG_ 793 FA_MSG_Einschraenkung 500;
BA_REL_ "GenSigTimeoutTime" BU_SG_REL_ Motor_MED17_Hybrid SG_ 793 FA_MSG_Einschraenkung 500;
BA_REL_ "GenSigTimeoutTime" BU_SG_REL_ Getriebe_Derivate SG_ 924 ESP_Offroad_Modus 1000;
BA_REL_ "GenSigTimeoutTime" BU_SG_REL_ Motor_EDC17_Pirol SG_ 924 Wischer_vorne_aktiv 1000;
BA_REL_ "GenSigTimeoutTime" BU_SG_REL_ Motor_MED17_Hybrid SG_ 924 Wischer_vorne_aktiv 1000;
BA_REL_ "GenSigTimeoutTime" BU_SG_REL_ Motor_EDC17_Pirol SG_ 924 HR_Tuer_geoeffnet 1000;
BA_REL_ "GenSigTimeoutTime" BU_SG_REL_ Motor_MED17_Hybrid SG_ 924 HR_Tuer_geoeffnet 1000;
BA_REL_ "GenSigTimeoutTime" BU_SG_REL_ Motor_EDC17_Pirol SG_ 924 HL_Tuer_geoeffnet 1000;
BA_REL_ "GenSigTimeoutTime" BU_SG_REL_ Motor_MED17_Hybrid SG_ 924 HL_Tuer_geoeffnet 1000;
BA_REL_ "GenSigTimeoutTime" BU_SG_REL_ Motor_EDC17_Pirol SG_ 924 FT_Sperrklinke 1000;
BA_REL_ "GenSigTimeoutTime" BU_SG_REL_ Motor_MED17_Hybrid SG_ 924 FT_Sperrklinke 1000;
BA_REL_ "GenSigTimeoutTime" BU_SG_REL_ Motor_EDC17_Pirol SG_ 924 BT_Tuer_geoeffnet 1000;
BA_REL_ "GenSigTimeoutTime" BU_SG_REL_ Motor_MED17_Hybrid SG_ 924 BT_Tuer_geoeffnet 1000;
BA_REL_ "GenSigTimeoutTime" BU_SG_REL_ Motor_EDC17_Pirol SG_ 924 BCM1_02_alt 1000;
BA_REL_ "GenSigTimeoutTime" BU_SG_REL_ Motor_MED17_Hybrid SG_ 924 BCM1_02_alt 1000;
BA_REL_ "GenSigTimeoutTime" BU_SG_REL_ Motor_EDC17_Pirol SG_ 924 BCM1_01_alt 1000;
BA_REL_ "GenSigTimeoutTime" BU_SG_REL_ Motor_MED17_Hybrid SG_ 924 BCM1_01_alt 1000;
BA_REL_ "GenSigTimeoutTime" BU_SG_REL_ Motor_EDC17_Pirol SG_ 924 FT_Tuer_geoeffnet 1000;
BA_REL_ "GenSigTimeoutTime" BU_SG_REL_ Getriebe_Derivate SG_ 924 FT_Tuer_geoeffnet 1000;
BA_REL_ "GenSigTimeoutTime" BU_SG_REL_ Motor_MED17_Hybrid SG_ 924 FT_Tuer_geoeffnet 1000;
BA_REL_ "GenSigTimeoutTime" BU_SG_REL_ Motor_EDC17_Pirol SG_ 924 BCM1_Rueckfahrlicht_Schalter 1000;
BA_REL_ "GenSigTimeoutTime" BU_SG_REL_ Motor_MED17_Hybrid SG_ 924 BCM1_Rueckfahrlicht_Schalter 1000;
BA_REL_ "GenSigTimeoutTime" BU_SG_REL_ Motor_EDC17_Pirol SG_ 924 BCM1_MH_WIV_Schalter 1000;
BA_REL_ "GenSigTimeoutTime" BU_SG_REL_ Motor_MED17_Hybrid SG_ 924 BCM1_MH_WIV_Schalter 1000;
BA_REL_ "GenSigTimeoutTime" BU_SG_REL_ LEH_Hybrid SG_ 924 BCM1_Aussen_Temp_ungef 1000;
BA_REL_ "GenSigTimeoutTime" BU_SG_REL_ BMS_Hybrid SG_ 924 BCM1_Aussen_Temp_ungef 1000;
BA_REL_ "GenSigTimeoutTime" BU_SG_REL_ Motor_EDC17_Pirol SG_ 924 BCM1_Aussen_Temp_ungef 1000;
BA_REL_ "GenSigTimeoutTime" BU_SG_REL_ Motor_MED17_Hybrid SG_ 924 BCM1_Aussen_Temp_ungef 1000;
BA_REL_ "GenSigTimeoutTime" BU_SG_REL_ Motor_EDC17_Pirol SG_ 924 Wischer_01_alt 1000;
BA_REL_ "GenSigTimeoutTime" BU_SG_REL_ Motor_MED17_Hybrid SG_ 924 Wischer_01_alt 1000;
BA_REL_ "GenSigTimeoutTime" BU_SG_REL_ Motor_EDC17_Pirol SG_ 924 TSG_BT_1_alt 1000;
BA_REL_ "GenSigTimeoutTime" BU_SG_REL_ Motor_MED17_Hybrid SG_ 924 TSG_BT_1_alt 1000;
BA_REL_ "GenSigTimeoutTime" BU_SG_REL_ Motor_EDC17_Pirol SG_ 924 TSG_HL_1_alt 1000;
BA_REL_ "GenSigTimeoutTime" BU_SG_REL_ Motor_MED17_Hybrid SG_ 924 TSG_HL_1_alt 1000;
BA_REL_ "GenSigTimeoutTime" BU_SG_REL_ Motor_EDC17_Pirol SG_ 924 TSG_HR_1_alt 1000;
BA_REL_ "GenSigTimeoutTime" BU_SG_REL_ Motor_MED17_Hybrid SG_ 924 TSG_HR_1_alt 1000;
BA_REL_ "GenSigTimeoutTime" BU_SG_REL_ LEH_Hybrid SG_ 924 Klima_Sensor_02_alt 1000;
BA_REL_ "GenSigTimeoutTime" BU_SG_REL_ BMS_Hybrid SG_ 924 Klima_Sensor_02_alt 1000;
BA_REL_ "GenSigTimeoutTime" BU_SG_REL_ Motor_EDC17_Pirol SG_ 924 Klima_Sensor_02_alt 1000;
BA_REL_ "GenSigTimeoutTime" BU_SG_REL_ Motor_MED17_Hybrid SG_ 924 Klima_Sensor_02_alt 1000;
BA_REL_ "GenSigTimeoutTime" BU_SG_REL_ Motor_EDC17_Pirol SG_ 924 TSG_FT_1_alt 1000;
BA_REL_ "GenSigTimeoutTime" BU_SG_REL_ Getriebe_Derivate SG_ 924 TSG_FT_1_alt 1000;
BA_REL_ "GenSigTimeoutTime" BU_SG_REL_ Motor_MED17_Hybrid SG_ 924 TSG_FT_1_alt 1000;
BA_REL_ "GenSigTimeoutTime" BU_SG_REL_ Motor_EDC17_Pirol SG_ 924 Parkhilfe_01_alt 1000;
BA_REL_ "GenSigTimeoutTime" BU_SG_REL_ Motor_MED17_Hybrid SG_ 924 Parkhilfe_01_alt 1000;
BA_REL_ "GenSigTimeoutTime" BU_SG_REL_ Motor_EDC17_Pirol SG_ 924 Fahrwerk_02_alt 1000;
BA_REL_ "GenSigTimeoutTime" BU_SG_REL_ Motor_MED17_Hybrid SG_ 924 Fahrwerk_02_alt 1000;
BA_REL_ "GenSigTimeoutTime" BU_SG_REL_ Motor_EDC17_Pirol SG_ 924 FA_StartStopp_Info 1000;
BA_REL_ "GenSigTimeoutTime" BU_SG_REL_ Motor_MED17_Hybrid SG_ 924 FA_StartStopp_Info 1000;
BA_REL_ "GenSigTimeoutTime" BU_SG_REL_ Motor_EDC17_Pirol SG_ 924 PH_StartStopp_Info 1000;
BA_REL_ "GenSigTimeoutTime" BU_SG_REL_ Motor_MED17_Hybrid SG_ 924 PH_StartStopp_Info 1000;
BA_REL_ "GenSigTimeoutTime" BU_SG_REL_ Motor_EDC17_Pirol SG_ 924 BCM1_OBD_FStatus_ATemp 1000;
BA_REL_ "GenSigTimeoutTime" BU_SG_REL_ Motor_MED17_Hybrid SG_ 924 BCM1_OBD_FStatus_ATemp 1000;
BA_REL_ "GenSigTimeoutTime" BU_SG_REL_ Motor_EDC17_Pirol SG_ 924 BCM1_Schalter_StartStopp 1000;
BA_REL_ "GenSigTimeoutTime" BU_SG_REL_ Motor_MED17_Hybrid SG_ 924 BCM1_Schalter_StartStopp 1000;
BA_REL_ "GenSigTimeoutTime" BU_SG_REL_ Ladegeraet_PAG_PF SG_ 1604 ZV_verriegelt_extern_ist 5000;
BA_REL_ "GenSigTimeoutTime" BU_SG_REL_ Ladegeraet_PAG_PF SG_ 1604 Kessy_01_alt 5000;
BA_REL_ "GenSigTimeoutTime" BU_SG_REL_ Ladegeraet_PAG_PF SG_ 1604 FFB_CarFinder 5000;
BA_REL_ "GenSigTimeoutTime" BU_SG_REL_ Ladegeraet_PAG_PF SG_ 1604 FFB_Auf_Taste 5000;
BA_REL_ "GenSigTimeoutTime" BU_SG_REL_ Motor_EDC17_Pirol SG_ 1604 BCM1_MH_Schalter 5000;
BA_REL_ "GenSigTimeoutTime" BU_SG_REL_ Motor_MED17_Hybrid SG_ 1604 BCM1_MH_Schalter 5000;
BA_REL_ "GenSigTimeoutTime" BU_SG_REL_ Motor_EDC17_Pirol SG_ 1604 BH_Blinker_re 5000;
BA_REL_ "GenSigTimeoutTime" BU_SG_REL_ Motor_MED17_Hybrid SG_ 1604 BH_Blinker_re 5000;
BA_REL_ "GenSigTimeoutTime" BU_SG_REL_ Motor_EDC17_Pirol SG_ 1604 BH_Blinker_li 5000;
BA_REL_ "GenSigTimeoutTime" BU_SG_REL_ Motor_MED17_Hybrid SG_ 1604 BH_Blinker_li 5000;
BA_REL_ "GenSigTimeoutTime" BU_SG_REL_ Motor_EDC17_Pirol SG_ 1604 SMLS_01_alt 5000;
BA_REL_ "GenSigTimeoutTime" BU_SG_REL_ Motor_MED17_Hybrid SG_ 1604 SMLS_01_alt 5000;
BA_REL_ "GenSigTimeoutTime" BU_SG_REL_ Ladegeraet_PAG_PF SG_ 1604 BCM1_02_alt 5000;
BA_REL_ "GenSigTimeoutTime" BU_SG_REL_ Motor_EDC17_Pirol SG_ 1604 BCM1_02_alt 5000;
BA_REL_ "GenSigTimeoutTime" BU_SG_REL_ Motor_MED17_Hybrid SG_ 1604 BCM1_02_alt 5000;
BA_REL_ "GenSigTimeoutTime" BU_SG_REL_ Motor_MED17_Hybrid SG_ 1604 HYB_Anf_E_Mode_alt 5000;
BA_REL_ "GenSigTimeoutTime" BU_SG_REL_ Motor_MED17_Hybrid SG_ 1604 HYB_Anf_E_Mode 5000;
BA_REL_ "GenSigTimeoutTime" BU_SG_REL_ Motor_EDC17_Pirol SG_ 130 Getriebe_01_CHK 500;
BA_REL_ "GenSigTimeoutTime" BU_SG_REL_ PSM_Ant_Derivate SG_ 130 Getriebe_01_CHK 500;
BA_REL_ "GenSigTimeoutTime" BU_SG_REL_ GW_Routing_Derivate SG_ 130 Getriebe_01_CHK 500;
BA_REL_ "GenSigTimeoutTime" BU_SG_REL_ Motor_MED17_Hybrid SG_ 130 Getriebe_01_CHK 500;
BA_REL_ "GenSigTimeoutTime" BU_SG_REL_ Motor_EDC17_Pirol SG_ 130 Getriebe_01_BZ 500;
BA_REL_ "GenSigTimeoutTime" BU_SG_REL_ PSM_Ant_Derivate SG_ 130 Getriebe_01_BZ 500;
BA_REL_ "GenSigTimeoutTime" BU_SG_REL_ GW_Routing_Derivate SG_ 130 Getriebe_01_BZ 500;
BA_REL_ "GenSigTimeoutTime" BU_SG_REL_ Motor_MED17_Hybrid SG_ 130 Getriebe_01_BZ 500;
BA_REL_ "GenSigTimeoutTime" BU_SG_REL_ Motor_EDC17_Pirol SG_ 130 GE_Schaltvorgang 500;
BA_REL_ "GenSigTimeoutTime" BU_SG_REL_ PSM_Ant_Derivate SG_ 130 GE_Schaltvorgang 500;
BA_REL_ "GenSigTimeoutTime" BU_SG_REL_ GW_Routing_Derivate SG_ 130 GE_Schaltvorgang 500;
BA_REL_ "GenSigTimeoutTime" BU_SG_REL_ Motor_MED17_Hybrid SG_ 130 GE_Schaltvorgang 500;
BA_REL_ "GenSigTimeoutTime" BU_SG_REL_ Motor_EDC17_Pirol SG_ 130 GE_Status_Kupplung 500;
BA_REL_ "GenSigTimeoutTime" BU_SG_REL_ PSM_Ant_Derivate SG_ 130 GE_Status_Kupplung 500;
BA_REL_ "GenSigTimeoutTime" BU_SG_REL_ GW_Routing_Derivate SG_ 130 GE_Status_Kupplung 500;
BA_REL_ "GenSigTimeoutTime" BU_SG_REL_ Motor_MED17_Hybrid SG_ 130 GE_Status_Kupplung 500;
BA_REL_ "GenSigTimeoutTime" BU_SG_REL_ Motor_EDC17_Pirol SG_ 130 GE_MMom_Soll 500;
BA_REL_ "GenSigTimeoutTime" BU_SG_REL_ PSM_Ant_Derivate SG_ 130 GE_MMom_Soll 500;
BA_REL_ "GenSigTimeoutTime" BU_SG_REL_ GW_Routing_Derivate SG_ 130 GE_MMom_Soll 500;
BA_REL_ "GenSigTimeoutTime" BU_SG_REL_ Motor_MED17_Hybrid SG_ 130 GE_MMom_Soll 500;
BA_REL_ "GenSigTimeoutTime" BU_SG_REL_ Motor_EDC17_Pirol SG_ 130 GE_MMom_Status 500;
BA_REL_ "GenSigTimeoutTime" BU_SG_REL_ PSM_Ant_Derivate SG_ 130 GE_MMom_Status 500;
BA_REL_ "GenSigTimeoutTime" BU_SG_REL_ GW_Routing_Derivate SG_ 130 GE_MMom_Status 500;
BA_REL_ "GenSigTimeoutTime" BU_SG_REL_ Motor_MED17_Hybrid SG_ 130 GE_MMom_Status 500;
BA_REL_ "GenSigTimeoutTime" BU_SG_REL_ PSM_Ant_Derivate SG_ 130 GE_Freig_Mmom_Soll 500;
BA_REL_ "GenSigTimeoutTime" BU_SG_REL_ GW_Routing_Derivate SG_ 130 GE_Freig_Mmom_Soll 500;
BA_REL_ "GenSigTimeoutTime" BU_SG_REL_ PSM_Ant_Derivate SG_ 130 GE_Status_Schaltablauf 500;
BA_REL_ "GenSigTimeoutTime" BU_SG_REL_ GW_Routing_Derivate SG_ 130 GE_Status_Schaltablauf 500;
BA_REL_ "GenSigTimeoutTime" BU_SG_REL_ PSM_Ant_Derivate SG_ 130 GE_KD_Fehler 500;
BA_REL_ "GenSigTimeoutTime" BU_SG_REL_ GW_Applikation_Derivate SG_ 130 GE_KD_Fehler 500;
BA_REL_ "GenSigTimeoutTime" BU_SG_REL_ GW_Routing_Derivate SG_ 130 GE_KD_Fehler 500;
BA_REL_ "GenSigTimeoutTime" BU_SG_REL_ GW_Routing_Derivate SG_ 130 GE_Verbot_Ausblendung 500;
BA_REL_ "GenSigTimeoutTime" BU_SG_REL_ Motor_EDC17_Pirol SG_ 130 GE_Verbot_Ausblendung 500;
BA_REL_ "GenSigTimeoutTime" BU_SG_REL_ Motor_MED17_Hybrid SG_ 130 GE_Verbot_Ausblendung 500;
BA_REL_ "GenSigTimeoutTime" BU_SG_REL_ GW_Routing_Derivate SG_ 130 GE_MMom_Vorhalt 500;
BA_REL_ "GenSigTimeoutTime" BU_SG_REL_ Motor_EDC17_Pirol SG_ 130 GE_MMom_Vorhalt 500;
BA_REL_ "GenSigTimeoutTime" BU_SG_REL_ Motor_MED17_Hybrid SG_ 130 GE_MMom_Vorhalt 500;
BA_REL_ "GenSigTimeoutTime" BU_SG_REL_ GW_Routing_Derivate SG_ 130 GE_Freig_MMom_Vorhalt 500;
BA_REL_ "GenSigTimeoutTime" BU_SG_REL_ Motor_EDC17_Pirol SG_ 130 GE_Freig_MMom_Vorhalt 500;
BA_REL_ "GenSigTimeoutTime" BU_SG_REL_ Motor_MED17_Hybrid SG_ 130 GE_Freig_MMom_Vorhalt 500;
BA_REL_ "GenSigTimeoutTime" BU_SG_REL_ Motor_EDC17_Pirol SG_ 131 Getriebe_02_CHK 500;
BA_REL_ "GenSigTimeoutTime" BU_SG_REL_ Motor_MED17_Hybrid SG_ 131 Getriebe_02_CHK 500;
BA_REL_ "GenSigTimeoutTime" BU_SG_REL_ Motor_EDC17_Pirol SG_ 131 Getriebe_02_BZ 500;
BA_REL_ "GenSigTimeoutTime" BU_SG_REL_ Motor_MED17_Hybrid SG_ 131 Getriebe_02_BZ 500;
BA_REL_ "GenSigTimeoutTime" BU_SG_REL_ Motor_EDC17_Pirol SG_ 131 GE_Synchro_Wunschdrehz 500;
BA_REL_ "GenSigTimeoutTime" BU_SG_REL_ Motor_MED17_Hybrid SG_ 131 GE_Synchro_Wunschdrehz 500;
BA_REL_ "GenSigTimeoutTime" BU_SG_REL_ Motor_EDC17_Pirol SG_ 131 GE_Synchro_Zeit 500;
BA_REL_ "GenSigTimeoutTime" BU_SG_REL_ Motor_MED17_Hybrid SG_ 131 GE_Synchro_Zeit 500;
BA_REL_ "GenSigTimeoutTime" BU_SG_REL_ Motor_EDC17_Pirol SG_ 131 GE_Mom_Begr_Gradient 500;
BA_REL_ "GenSigTimeoutTime" BU_SG_REL_ Motor_MED17_Hybrid SG_ 131 GE_Mom_Begr_Gradient 500;
BA_REL_ "GenSigTimeoutTime" BU_SG_REL_ Motor_EDC17_Pirol SG_ 131 GE_Anheb_Solldrehz_Leerlauf 500;
BA_REL_ "GenSigTimeoutTime" BU_SG_REL_ Motor_MED17_Hybrid SG_ 131 GE_Anheb_Solldrehz_Leerlauf 500;
BA_REL_ "GenSigTimeoutTime" BU_SG_REL_ Motor_EDC17_Pirol SG_ 131 GE_Vorsteuermoment 500;
BA_REL_ "GenSigTimeoutTime" BU_SG_REL_ Motor_MED17_Hybrid SG_ 131 GE_Vorsteuermoment 500;
BA_REL_ "GenSigTimeoutTime" BU_SG_REL_ Motor_EDC17_Pirol SG_ 131 GE_Drehzahlmesser_Daempfung 500;
BA_REL_ "GenSigTimeoutTime" BU_SG_REL_ Motor_MED17_Hybrid SG_ 131 GE_Drehzahlmesser_Daempfung 500;
BA_REL_ "GenSigTimeoutTime" BU_SG_REL_ Motor_EDC17_Pirol SG_ 131 GE_Schubabschalt_Unt 500;
BA_REL_ "GenSigTimeoutTime" BU_SG_REL_ Motor_MED17_Hybrid SG_ 131 GE_Schubabschalt_Unt 500;
BA_REL_ "GenSigTimeoutTime" BU_SG_REL_ Motor_EDC17_Pirol SG_ 131 GE_Freigabe_Synchro 500;
BA_REL_ "GenSigTimeoutTime" BU_SG_REL_ Motor_MED17_Hybrid SG_ 131 GE_Freigabe_Synchro 500;
BA_REL_ "GenSigTimeoutTime" BU_SG_REL_ Motor_MED17_Hybrid SG_ 131 GE_HYB_DZ_Eingriff 500;
BA_REL_ "GenSigTimeoutTime" BU_SG_REL_ Motor_EDC17_Pirol SG_ 258 GE_Waehlhebel 500;
BA_REL_ "GenSigTimeoutTime" BU_SG_REL_ GW_Routing_Derivate SG_ 258 GE_Waehlhebel 500;
BA_REL_ "GenSigTimeoutTime" BU_SG_REL_ PSM_Ant_Derivate SG_ 258 GE_Waehlhebel 500;
BA_REL_ "GenSigTimeoutTime" BU_SG_REL_ Motor_MED17_Hybrid SG_ 258 GE_Waehlhebel 500;
BA_REL_ "GenSigTimeoutTime" BU_SG_REL_ Motor_EDC17_Pirol SG_ 258 GE_StartStopp_Info 500;
BA_REL_ "GenSigTimeoutTime" BU_SG_REL_ GW_Routing_Derivate SG_ 258 GE_StartStopp_Info 500;
BA_REL_ "GenSigTimeoutTime" BU_SG_REL_ PSM_Ant_Derivate SG_ 258 GE_StartStopp_Info 500;
BA_REL_ "GenSigTimeoutTime" BU_SG_REL_ Motor_MED17_Hybrid SG_ 258 GE_StartStopp_Info 500;
BA_REL_ "GenSigTimeoutTime" BU_SG_REL_ Motor_EDC17_Pirol SG_ 258 Getriebe_03_CHK 500;
BA_REL_ "GenSigTimeoutTime" BU_SG_REL_ PSM_Ant_Derivate SG_ 258 Getriebe_03_CHK 500;
BA_REL_ "GenSigTimeoutTime" BU_SG_REL_ GW_Routing_Derivate SG_ 258 Getriebe_03_CHK 500;
BA_REL_ "GenSigTimeoutTime" BU_SG_REL_ Motor_MED17_Hybrid SG_ 258 Getriebe_03_CHK 500;
BA_REL_ "GenSigTimeoutTime" BU_SG_REL_ Motor_EDC17_Pirol SG_ 258 Getriebe_03_BZ 500;
BA_REL_ "GenSigTimeoutTime" BU_SG_REL_ PSM_Ant_Derivate SG_ 258 Getriebe_03_BZ 500;
BA_REL_ "GenSigTimeoutTime" BU_SG_REL_ GW_Routing_Derivate SG_ 258 Getriebe_03_BZ 500;
BA_REL_ "GenSigTimeoutTime" BU_SG_REL_ Motor_MED17_Hybrid SG_ 258 Getriebe_03_BZ 500;
BA_REL_ "GenSigTimeoutTime" BU_SG_REL_ Motor_EDC17_Pirol SG_ 258 GE_Freig_Langfr_Schutzmom 500;
BA_REL_ "GenSigTimeoutTime" BU_SG_REL_ PSM_Ant_Derivate SG_ 258 GE_Freig_Langfr_Schutzmom 500;
BA_REL_ "GenSigTimeoutTime" BU_SG_REL_ GW_Routing_Derivate SG_ 258 GE_Freig_Langfr_Schutzmom 500;
BA_REL_ "GenSigTimeoutTime" BU_SG_REL_ Motor_MED17_Hybrid SG_ 258 GE_Freig_Langfr_Schutzmom 500;
BA_REL_ "GenSigTimeoutTime" BU_SG_REL_ Motor_EDC17_Pirol SG_ 258 GE_Uefkt 500;
BA_REL_ "GenSigTimeoutTime" BU_SG_REL_ PSM_Ant_Derivate SG_ 258 GE_Uefkt 500;
BA_REL_ "GenSigTimeoutTime" BU_SG_REL_ GW_Routing_Derivate SG_ 258 GE_Uefkt 500;
BA_REL_ "GenSigTimeoutTime" BU_SG_REL_ Motor_MED17_Hybrid SG_ 258 GE_Uefkt 500;
BA_REL_ "GenSigTimeoutTime" BU_SG_REL_ Motor_EDC17_Pirol SG_ 258 GE_Zielgang 500;
BA_REL_ "GenSigTimeoutTime" BU_SG_REL_ PSM_Ant_Derivate SG_ 258 GE_Zielgang 500;
BA_REL_ "GenSigTimeoutTime" BU_SG_REL_ GW_Routing_Derivate SG_ 258 GE_Zielgang 500;
BA_REL_ "GenSigTimeoutTime" BU_SG_REL_ Motor_MED17_Hybrid SG_ 258 GE_Zielgang 500;
BA_REL_ "GenSigTimeoutTime" BU_SG_REL_ Motor_EDC17_Pirol SG_ 258 GE_Langfr_Schutzmom 500;
BA_REL_ "GenSigTimeoutTime" BU_SG_REL_ PSM_Ant_Derivate SG_ 258 GE_Langfr_Schutzmom 500;
BA_REL_ "GenSigTimeoutTime" BU_SG_REL_ GW_Routing_Derivate SG_ 258 GE_Langfr_Schutzmom 500;
BA_REL_ "GenSigTimeoutTime" BU_SG_REL_ Motor_MED17_Hybrid SG_ 258 GE_Langfr_Schutzmom 500;
BA_REL_ "GenSigTimeoutTime" BU_SG_REL_ PSM_Ant_Derivate SG_ 258 GE_reserv_Waehlhebel 500;
BA_REL_ "GenSigTimeoutTime" BU_SG_REL_ GW_Routing_Derivate SG_ 258 GE_reserv_Waehlhebel 500;
BA_REL_ "GenSigTimeoutTime" BU_SG_REL_ Motor_EDC17_Pirol SG_ 258 GE_Eingangsdrehz 500;
BA_REL_ "GenSigTimeoutTime" BU_SG_REL_ PSM_Ant_Derivate SG_ 258 GE_Eingangsdrehz 500;
BA_REL_ "GenSigTimeoutTime" BU_SG_REL_ GW_Routing_Derivate SG_ 258 GE_Eingangsdrehz 500;
BA_REL_ "GenSigTimeoutTime" BU_SG_REL_ Motor_MED17_Hybrid SG_ 258 GE_Eingangsdrehz 500;
BA_REL_ "GenSigTimeoutTime" BU_SG_REL_ Motor_EDC17_Pirol SG_ 258 GE_Notlauf 500;
BA_REL_ "GenSigTimeoutTime" BU_SG_REL_ PSM_Ant_Derivate SG_ 258 GE_Notlauf 500;
BA_REL_ "GenSigTimeoutTime" BU_SG_REL_ GW_Routing_Derivate SG_ 258 GE_Notlauf 500;
BA_REL_ "GenSigTimeoutTime" BU_SG_REL_ Motor_MED17_Hybrid SG_ 258 GE_Notlauf 500;
BA_REL_ "GenSigTimeoutTime" BU_SG_REL_ PSM_Ant_Derivate SG_ 258 GE_Codierung_MSG 500;
BA_REL_ "GenSigTimeoutTime" BU_SG_REL_ GW_Routing_Derivate SG_ 258 GE_Codierung_MSG 500;
BA_REL_ "HYB_Tx_Baureihe" BU_BO_REL_ GW_Routing_Derivate 906 2;
BA_REL_ "HYB_Tx_Verwendung" BU_BO_REL_ GW_Routing_Derivate 906 1;
BA_REL_ "HYB_Tx_Baureihe" BU_BO_REL_ GW_Routing_Derivate 1795 2;
BA_REL_ "HYB_Tx_Baureihe" BU_BO_REL_ GW_Routing_Derivate 482 2;
BA_REL_ "HYB_Tx_Baureihe" BU_BO_REL_ GW_Routing_Derivate 793 1;
BA_REL_ "HYB_Tx_Baureihe" BU_BO_REL_ GW_Routing_Derivate 924 2;
BA_REL_ "HYB_Tx_Verwendung" BU_BO_REL_ GW_Routing_Derivate 924 1;
BA_REL_ "HYB_Tx_Baureihe" BU_BO_REL_ GW_Routing_Derivate 1604 2;
VAL_ 3221225472 KBI_Service_km 1022 "Init" 1023 "Fehler" ;
VAL_ 3221225472 KBI_Service_Zeit 2046 "Init" 2047 "Fehler" ;
VAL_ 3221225472 KBI_Service_Typ 0 "Init" 1 "naechste_Wartung_ist_Zwischenwartung" 2 "naechste_Wartung_ist_Hauptwartung" 3 "naechste_Wartung_ist_Oelservice" ;
VAL_ 3221225472 Mo_HVEM_HV_Abschaltanf 0 "keine_Anforderung" 1 "Abschaltung_HV_Verbraucher_gefordert" ;
VAL_ 3221225472 MO_HVEM_HV_Maxleistung 254 "Init" 255 "Fehler" ;
VAL_ 3221225472 HVEM_Istleistung_Nebenverbrauch 251 "reserviert" 252 "reserviert" 253 "reserviert" 254 "Init" 255 "Fehler" ;
VAL_ 3221225472 SVB_IVB_FS_Fond 0 "SG nicht verbaut" 1 "SG verbaut" ;
VAL_ 3221225472 SVB_IVB_FS 0 "SG nicht verbaut" 1 "SG verbaut" ;
VAL_ 3221225472 SVB_IVB_BFS_Fond 0 "SG nicht verbaut" 1 "SG verbaut" ;
VAL_ 3221225472 SVB_IVB_BFS 0 "SG nicht verbaut" 1 "SG verbaut" ;
VAL_ 3221225472 SVB_KameraLow_FLA 1 "SG verbaut" 0 "SG nicht verbaut" ;
VAL_ 3221225472 AWV_Halten 0 "keine_Anforderung" 1 "Anforderung_das_Fzg_im_Stillstand_zu_halten" ;
VAL_ 305 MO_ePowermeter 0 "Init_keine_Anzeige" 254 "Funktion_deaktiv_Anzeige_ausgegraut" 255 "Fehler_keine_Anzeige" ;
VAL_ 305 MO_W_Reku_normiert_ueberlauf 1 "Rekuperationssignal_min_1_mal_uebergelaufen" 0 "kein_Ueberlauf" ;
VAL_ 305 Ladezustand 255 "Fehler" ;
VAL_ 305 Enrgfluss_State 1 "no_torques" 2 "pos_tor_EE" 3 "pos_tor_ICE" 4 "pos_tor_ICE_bat_charge" 5 "pos_tor_EE_ICE" 6 "neg_tor_EE_bar_charge" 7 "neg_tor_EE_bat_discharge" 8 "neg_tor_EE" 9 "ICE_charge_bat" 10 "neg_tor_EE_and_ICE" 11 "no_tor_sailing" 12 "no_tor_sailing_and_ICE" 255 "Fehler" ;
VAL_ 305 MO_Powermeter 4093 "Off" ;
VAL_ 914 ESP_OBD_Status 0 "MIL_aus" 1 "MIL_ein" ;
VAL_ 914 OBD_Fehler_Radsensor_VR 0 "kein_Fehler" 1 "KS- (Kurzschluss nach minus)" 2 "KS+ (Kurzschluss nach plus)" 3 "OC (Leitungsunterbrechung)" 4 "OOR+ (Signal zu gross)" 5 "OOR- (Signal zu klein)" 6 "RC+ (Signal unplausibel zu gross)" 7 "RC- (Signal unplausibel zu klein)" 8 "KS+/OC (Kurzschluss nach plus/Unterbrechung)" 9 "KS-/OC  (Kurzschluss nach minus/Unterbrechung)" 10 "KS-/KS+  (Kurzschluss nach minus/plus)" 11 "KS-/KS+/OC (Kurzschluss nach minus/plus/Unterbrechung)" 12 "frei" 13 "frei" 14 "frei" 15 "frei" ;
VAL_ 914 OBD_Fehler_Radsensor_VL 0 "kein_Fehler" 1 "KS- (Kurzschluss nach minus)" 2 "KS+ (Kurzschluss nach plus)" 3 "OC (Leitungsunterbrechung)" 4 "OOR+ (Signal zu gross)" 5 "OOR- (Signal zu klein)" 6 "RC+ (Signal unplausibel zu gross)" 7 "RC- (Signal unplausibel zu klein)" 8 "KS+/OC (Kurzschluss nach plus/Unterbrechung)" 9 "KS-/OC  (Kurzschluss nach minus/Unterbrechung)" 10 "KS-/KS+  (Kurzschluss nach minus/plus)" 11 "KS-/KS+/OC (Kurzschluss nach minus/plus/Unterbrechung)" 12 "frei" 13 "frei" 14 "frei" 15 "frei" ;
VAL_ 914 OBD_Fehler_Radsensor_HR 0 "kein_Fehler" 1 "KS- (Kurzschluss nach minus)" 2 "KS+ (Kurzschluss nach plus)" 3 "OC (Leitungsunterbrechung)" 4 "OOR+ (Signal zu gross)" 5 "OOR- (Signal zu klein)" 6 "RC+ (Signal unplausibel zu gross)" 7 "RC- (Signal unplausibel zu klein)" 8 "KS+/OC (Kurzschluss nach plus/Unterbrechung)" 9 "KS-/OC  (Kurzschluss nach minus/Unterbrechung)" 10 "KS-/KS+  (Kurzschluss nach minus/plus)" 11 "KS-/KS+/OC (Kurzschluss nach minus/plus/Unterbrechung)" 12 "frei" 13 "frei" 14 "frei" 15 "frei" ;
VAL_ 914 OBD_Fehler_Radsensor_HL 0 "kein_Fehler" 1 "KS- (Kurzschluss nach minus)" 2 "KS+ (Kurzschluss nach plus)" 3 "OC (Leitungsunterbrechung)" 4 "OOR+ (Signal zu gross)" 5 "OOR- (Signal zu klein)" 6 "RC+ (Signal unplausibel zu gross)" 7 "RC- (Signal unplausibel zu klein)" 8 "KS+/OC (Kurzschluss nach plus/Unterbrechung)" 9 "KS-/OC  (Kurzschluss nach minus/Unterbrechung)" 10 "KS-/KS+  (Kurzschluss nach minus/plus)" 11 "KS-/KS+/OC (Kurzschluss nach minus/plus/Unterbrechung)" 12 "frei" 13 "frei" 14 "frei" 15 "frei" ;
VAL_ 906 KL_Sportmodus 0 "Normal" 7 "Reserve" 1 "Sport 1" 3 "Reserve" 4 "Reserve" 2 "Sport 2" 6 "Reserve" 5 "Reserve" ;
VAL_ 906 KL_T_PSM_off 0 "Taste nicht betaetigt" 1 "Taste betaetigt" ;
VAL_ 906 F_Klima_08_PAG_Fwk 1 "veraltet" 0 "aktuell" ;
VAL_ 906 F_Klima_03_Ant 1 "veraltet" 0 "aktuell" ;
VAL_ 906 ESP_Rollenmodus 0 "Rollenmodus nicht aktiv" 1 "Rollenmodus aktiv" ;
VAL_ 906 KL_T_Abgasklappe 1 "Taster betätigt" 0 "Taster nicht betätigt" ;
VAL_ 906 KL_Magnetventil 1 "Wasserventil geschlossen" 0 "Wasserventil geoeffnet" ;
VAL_ 906 F_ESP_11_Ant 1 "veraltet" 0 "aktuell" ;
VAL_ 1731 NMH_ESP_Start_1 1 "Zustand Start (<--Sleep)" ;
VAL_ 1731 NMH_ESP_Start_2 1 "Zustand Start (<--Prepare to Sle" ;
VAL_ 1731 NMH_ESP_Normal_Mode_1 1 "Zustand Normal Mode (<-- Start)" ;
VAL_ 1731 NMH_ESP_Normal_Mode_2 1 "Zustand Normal Mode (<-- Ready t" ;
VAL_ 1731 NMH_ESP_Per_WakeUp 3 "Klemme 15 HW (falls vorhanden)" 0 "Wenn Funktions-Wakeup" 1 "CAN-Wakeup" 2 "Periphrie-Wakeup Ursache nicht b" ;
VAL_ 1731 NMH_ESP_Fkt_WakeUp 0 "wenn Peripheriewakeup" ;
VAL_ 1731 NMH_ESP_NM_aktiv_Klemme_15 1 "Klemme 15 EIN" ;
VAL_ 1731 NMH_ESP_NM_aktiv_Diagnose 1 "Diagnose bei Kl 15 aus" ;
VAL_ 1731 NMH_ESP_NM_aktiv_Start 1 "Zustand 'START' (NM-high)" ;
VAL_ 1731 NMH_ESP_NM_aktiv_v_groesser_Null 1 "v > 0" ;
VAL_ 1731 NMH_ESP_Mindestaktivzeit 1 "aktiv" ;
VAL_ 1731 NMH_ESP_kein_NL 1 "kein lokaler Nachlauf" ;
VAL_ 1731 NMH_ESP_NL_Daten_EEPROM 1 "EEPROM Datenspeicherung" ;
VAL_ 1731 NMH_ESP_TimeOut_Fehler 1 "Aktiver Timeout Fehlerspeicherei" ;
VAL_ 1731 NMH_ESP_CAN_Diag_deaktiv 1 "CAN-Diagnose deaktiv" ;
VAL_ 1731 NMH_ESP_KompSchutz 1 "KS aktiv" ;
VAL_ 1731 NMH_ESP_Mute_Mode 1 "MuteMode aktiv" ;
VAL_ 1731 NMH_ESP_Transport_Mode 1 "Transportmodus aktiv" ;
VAL_ 1731 NMH_ESP_Abschaltstufe_aktiv 1 "Abschaltstufe aktiv" ;
VAL_ 1731 NMH_ESP_Eindraht_Fehler 1 "Eindrahtbetrieb erkannt" ;
VAL_ 1731 NMH_ESP_Lokalaktiv 1 "war Lokalaktiv" 0 "war nicht Lokalaktiv" ;
VAL_ 1731 NMH_ESP_Subsystemaktiv 1 "war Lokalaktiv" 0 "Subsystem war nicht lokalaktiv" ;
VAL_ 946 BEM_NV_NachladAnf 0 "keine_Anforderung" 1 "Anforderung_NV_Nachladung" 2 "Init" 3 "Fehler" ;
VAL_ 946 BEM_Freigabe_HV_Ladung 0 "HV_Ladung_nicht_freigegeben" 1 "HV_Ladung_freigegeben" ;
VAL_ 1628 BMS_IstSpannung_HV 255 "Fehler" ;
VAL_ 1628 BMS_Temperatur_Ansaugluft 254 "Init" 255 "Fehler" ;
VAL_ 1628 BMS_Temperatur 254 "Init" 255 "Fehler" ;
VAL_ 1628 BMS_HYB_Spuelbetrieb_Status 0 "Umluftbetrieb" 1 "Spuelbetrieb" ;
VAL_ 1628 BMS_HYB_Temp_vor_Verd 254 "Init" 255 "Fehler" ;
VAL_ 1628 BMS_HYB_Temp_nach_Verd 254 "Init" 255 "Fehler" ;
VAL_ 1628 BMS_HYB_Kuehlung_Anf 2 "aktive_Kuehlung_Stufe_2" 3 "Kuehlung_max" 0 "keine_Kuehlanforderung" 1 "aktive_Kuehlung_Stufe_1" ;
VAL_ 1628 BMS_HYB_ASV_vorne_Status 0 "Ventil_offen" 1 "Ventil_geschlossen" ;
VAL_ 1628 BMS_HYB_ASV_hinten_Status 0 "Ventil_offen" 1 "Ventil_geschlossen" ;
VAL_ 1628 BMS_HYB_KD_Fehler 1 "mind. ein KD-Fehler vorhanden" 0 "kein KD-Fehler" ;
VAL_ 1628 BMS_HYB_BattFanSpd 14 "Init" 15 "Fehler" ;
VAL_ 1628 BMS_HYB_VentilationReq 1 "Ventilation_Request" ;
VAL_ 945 DC_TiefsetzBereit 0 "Standby" 1 "Tiefsetzbereit" ;
VAL_ 945 DC_HYB_iAktLV 1022 "Init" 1023 "Fehler" ;
VAL_ 945 DC_HYB_iAktReserveLV 1022 "Init" 1023 "Fehler" ;
VAL_ 945 DC_HYB_uAktLV 254 "Init" 255 "Fehler" ;
VAL_ 945 DC_HYB_LangsRegelung 0 "normale_Regelung" 1 "langsame_Regelung" ;
VAL_ 945 DC_HYB_Abregelung_Temperatur 0 "keine_Begrenzung" 1 "Abregelung_Temperatur" ;
VAL_ 945 DC_HYB_Fehler_RedLeistung 0 "kein_Fehler" 1 "Fehler_RedLeistung" ;
VAL_ 945 DC_HYB_Fehler_intern 0 "kein_Fehler" 1 "Fehler_intern" ;
VAL_ 945 DC_HYB_Fehler_Spannung 0 "kein_Fehler" 1 "Fehler_Spannung" ;
VAL_ 945 DC_Verbrauch_Ueberlauf 0 "kein_Ueberlauf" 1 "Ueberlauf" ;
VAL_ 945 DC_HYB_Auslastungsgrad 254 "Initwert" 255 "Fehler" ;
VAL_ 1627 EM_HYB_KD_Fehler 0 "kein_KD_Fehler" 1 "KD_Fehler" ;
VAL_ 256 ESP_v_Signal 65534 "Init" 65533 "Unterspannung" 65535 "Fehler" ;
VAL_ 256 ASR_Moment_langsam 1022 "Init" 1023 "Fehler" ;
VAL_ 256 ASR_MSR_Moment_schnell 1022 "Init" 1023 "Fehler" ;
VAL_ 256 ASR_Tastung_passiv 1 "ASR_passiv_getastet" 0 "ASR_aktiviert" ;
VAL_ 256 ESP_Tastung_passiv 1 "ESP passiv getastet" 0 "ESP aktiviert" ;
VAL_ 256 ESP_Systemstatus 0 "iO" 1 "Fehler" ;
VAL_ 256 ASR_Schalteingriff 0 "keine Anforderung" 3 "Schaltverbot" 2 "Rückschaltung" 1 "ASR_Schaltkennfeld" ;
VAL_ 256 OBD_Schlechtweg 1 "Schlechtweg erkannt" 0 "kein Schlechtweg erkannt" ;
VAL_ 256 OBD_QBit_Schlechtweg 0 "gueltiger_Wert" 1 "Ersatz_Init_oder_Fehlerwert" ;
VAL_ 256 ESP_QBit_v_Signal 0 "gueltiger_Wert" 1 "Ersatz_Init_oder_Fehlerwert" ;
VAL_ 256 ABS_Bremsung 1 "ABS_Regelung_aktiv" 0 "keine_ABS_Regelung" ;
VAL_ 256 ASR_Anf 1 "ASR_Anforderung" 0 "keine_Anforderung" ;
VAL_ 256 MSR_Anf 0 "keine Anfoderung" 1 "MSR-Anforderung" ;
VAL_ 256 EBV_Eingriff 0 "kein EBV-Eingriff" 1 "EBV-Eingriff" ;
VAL_ 256 EDS_Eingriff 1 "EDS-Eingriff" 0 "kein EDS-Eingriff" ;
VAL_ 256 ESP_Eingriff 1 "ESP_Eingriff_aktiv" 0 "kein_ESP_Eingriff" ;
VAL_ 256 ESP_ASP 1 "ASP_aktiv" 0 "ASP_inaktiv" ;
VAL_ 256 ESP_KD_Fehler 1 "KD_Fehler" 0 "kein_KD_Fehler" ;
VAL_ 257 ESP_QBit_Gierrate 0 "gueltiger_Wert" 1 "Ersatz_Init_oder_Fehlerwert" ;
VAL_ 257 ESP_QBit_Laengsbeschl 0 "gueltiger_Wert" 1 "Ersatz_Init_oder_Fehlerwert" ;
VAL_ 257 ESP_QBit_Querb 0 "gueltiger_Wert" 1 "Ersatz_Init_oder_Fehlerwert" ;
VAL_ 257 ESP_Stillstandsflag 0 "kein Stillstand erkannt" 1 "Stillstand erkannt" ;
VAL_ 257 ESP_Querbeschleunigung 255 "Fehler" ;
VAL_ 257 ESP_Laengsbeschl 1022 "Signal_nicht_vorhanden" 1023 "Fehler" ;
VAL_ 257 ESP_Verteil_Wankmom 30 "Init" 31 "Fehler" ;
VAL_ 257 ESP_QBit_Anf_Vert_Wank 0 "gueltiger_Wert" 1 "Ersatz_Init_oder_Fehlerwert" ;
VAL_ 257 ESP_Gierrate 16383 "Fehler" ;
VAL_ 257 ESP_VZ_Gierrate 1 "negativ" 0 "positiv" ;
VAL_ 257 ESP_Notbremsanzeige 0 "keine_Notbremsung_erkannt" 1 "Notbremsung_erkannt" ;
VAL_ 257 ESP_SpannungsAnf 1 "Anforderung Spannungswert 1" 0 "keine Anforderung" ;
VAL_ 259 ESP_VL_FR 0 "Vorwaerts" 1 "Rueckwaerts" ;
VAL_ 259 ESP_VR_FR 0 "Vorwaerts" 1 "Rueckwaerts" ;
VAL_ 259 ESP_HL_FR 0 "Vorwaerts" 1 "Rueckwaerts" ;
VAL_ 259 ESP_HR_FR 1 "Rueckwaerts" 0 "Vorwaerts" ;
VAL_ 259 ESP_VL_Radgeschw 4093 "Unterspannung" 4094 "Init" 4095 "Fehler" ;
VAL_ 259 ESP_VR_Radgeschw 4094 "Init" 4093 "Unterspannung" 4095 "Fehler" ;
VAL_ 259 ESP_HL_Radgeschw 4094 "Init" 4093 "Unterspannung" 4095 "Fehler" ;
VAL_ 259 ESP_HR_Radgeschw 4094 "Init" 4093 "Unterspannung" 4095 "Fehler" ;
VAL_ 776 ESP_HDC_FktLampe 0 "Aus" 1 "Ein" ;
VAL_ 776 ESP_ASR_Lampe 0 "ESP_ASR_Lampe_aus" 1 "ESP_ASR_Lampe_an" ;
VAL_ 776 ESP_Meldungen 0 "keine_Anzeige_kein_Gong" 3 "Stoerung_Hillholder_und_1x_Gong" 1 "Autohold_Hinweis_1_und_kein_Gong" 2 "Stoerung_Autohold_und_1x_Gong" 4 "Uebernehmen_und_1x_Gong" ;
VAL_ 776 ESP_Lampe 0 "Aus" 1 "Ein" ;
VAL_ 776 ABS_Lampe 0 "Aus" 1 "Ein" ;
VAL_ 776 BK_Lampe 0 "Aus" 1 "Ein" ;
VAL_ 776 ESP_Akustik 0 "keine_Akustik" 1 "1x_Beep" ;
VAL_ 776 ESP_Diagnose 1 "ESP_in_Diagnose" 0 "ESP_nicht_in_Diagnose" ;
VAL_ 776 ESP_Textanzeigen_02 1 "ESP_Stoerung" 7 "ASR_off" 6 "ESP_switched_off" 10 "keine_Bremskraftverstaerkung" 3 "ESP_ABS_Stoerung" 0 "kein_Text" 8 "ESP_ASR_on" 5 "ASR_Stoerung" 9 "Stoerung_Hillholder" 2 "ABS_Stoerung" 15 "ESP_offroad" 16 "Autohold_Hinweis_1" 12 "ABS_ASR_Stoerung" 14 "Stoerung_Autohold" 11 "ASR_aktiviert" 13 "bitte_Reifen_pruefen" 4 "nicht_definiert" 17 "ESP_sport" ;
VAL_ 776 ESP_Off_Lampe 1 "Lampe_ein" 0 "Lampe_aus" ;
VAL_ 776 ESP_m_Raddrehz 32766 "Init" 32765 "Unterspannung" 32767 "Fehler" ;
VAL_ 776 ESP_Fehlerstatus_Wegimp 1 "Fehler" 0 "Wegimpulse_iO" ;
VAL_ 776 ESP_Wegimp_Ueberlauf 0 "Reset und kein Überlauf" 1 "mindestens 1x Überlauf" ;
VAL_ 776 ESP_QBit_Wegimp_VA 0 "gueltiger_Wert" 1 "Ersatz_Init_oder_Fehlerwert" ;
VAL_ 776 ESP_Displaywarnungen 1 "BKL_Display_Warnung" 0 "keine_Warnung" ;
VAL_ 776 ESP_HDC_Regelgeschw 0 "nicht_verbaut" 125 "HDC_Standby" 127 "Fehler" ;
VAL_ 776 ESP_BKV_Warnung 1 "keine_Bremskraftverstaerkung_plu" 0 "keine_Anzeige_kein_Gong" ;
VAL_ 262 ESP_Status_Anfahrhilfe 0 "Aus" 1 "Ein" ;
VAL_ 262 ESP_Anforderung_EPB 1 "Anforderung_Oeffnen" 0 "keine_Anforderung" 2 "Anforderung_Schliessen" 3 "reserviert" ;
VAL_ 262 ESP_Lenkeingriff_ADS 0 "kein_Lenkeingriff" 1 "stabilisierender_Lenkeingriff" ;
VAL_ 262 ESP_Bremsruck_AWV2 1 "Bremsruck_ausgefuehrt" 0 "kein_Bremsruck_ausgefuehrt" ;
VAL_ 262 ESP_Konsistenz_AWV2 1 "Botschaft_fuer_AWV2_nicht_konsis" 0 "Botschaft_fuer_AWV2_konsistent" ;
VAL_ 262 ESP_QBit_Bremsdruck 0 "gueltiger_Wert" 1 "Ersatz_Init_oder_Fehlerwert" ;
VAL_ 262 ESP_QBit_Fahrer_bremst 0 "gueltiger_Wert" 1 "Ersatz_Init_oder_Fehlerwert" ;
VAL_ 262 ESP_Schwelle_Unterdruck 1 "Unterdruck_kleiner_gleich_450_mb" 0 "kein_Signal" 2 "Unterdruck_groesser_450_mbar" 3 "Fehler_Unterdrucksensor" ;
VAL_ 262 ESP_Bremsdruck 1023 "Fehler" ;
VAL_ 262 ESP_Fahrer_bremst 1 "Fahrer_bremst" 0 "Fahrer_bremst_nicht" ;
VAL_ 262 ESP_Verz_TSK_aktiv 0 "TSK_Verzoegerung_inaktiv" 1 "TSK_Verzoegerung_aktiv" ;
VAL_ 262 ESP_Konsistenz_TSK 1 "Botschaft_fuer_Verzoegerungsanfo" 0 "Botschaft_fuer_Verzoegerungsanfo" ;
VAL_ 262 ECD_Fehler 0 "ECD_iO" 1 "ECD_Fehler" ;
VAL_ 262 ECD_nicht_verfuegbar 0 "ECD_Funktion_verfuegbar" 1 "ECD_Funktion_nicht_verfuegbar" ;
VAL_ 262 ESP_Status_Bremsentemp 0 "Bremse nicht überhitzt" 1 "Bremse überhitzt" ;
VAL_ 262 ESP_Autohold_Standby 0 "Autohold_nicht_im_Standby" 1 "Autohold_im_Standby" ;
VAL_ 262 ESP_HDC_Standby 0 "HDC_Funktion_nicht_im_Standby" 1 "HDC_Funktion_im_Standby" ;
VAL_ 262 ESP_HBA_aktiv 1 "HBA_aktiv" 0 "HBA_nicht_aktiv" ;
VAL_ 262 ESP_Prefill_ausgeloest 1 "Prefill_ausgeloest" 0 "nicht_ausgeloest" ;
VAL_ 262 ESP_Rueckwaertsfahrt_erkannt 0 "keine_Rueckwaetsfahrt" 1 "Rueckwaertsfahrt_erkannt" ;
VAL_ 262 ESP_StartStopp_Info 2 "Motoranlauf_zwingend_notwendig_(" 3 "Systemfehler" 0 "Motorlauf_nicht_notwendig_(Stopp" 1 "Motoranlauf_nicht_zwingend_notwe" ;
VAL_ 262 ESP_Eingr_HL 1 "ESP_Eingriff_HL" 0 "kein_Eingriff" ;
VAL_ 262 ESP_Eingr_HR 0 "kein_Eingriff" 1 "ESP_Eingriff_HR" ;
VAL_ 262 ESP_Eingr_VL 1 "ESP_Eingriff_VL" 0 "kein_Eingriff" ;
VAL_ 262 ESP_Eingr_VR 0 "kein_Eingriff" 1 "ESP_Eingriff_VR" ;
VAL_ 262 ESP_BKV_Unterdruck 255 "Fehler" ;
VAL_ 262 ESP_Autohold_aktiv 1 "Autohold aktiv" 0 "Autohold inaktiv" ;
VAL_ 262 ESP_FStatus_Anfahrhilfe 0 "kein_Fehler" 1 "Fehler" ;
VAL_ 262 ESP_Verz_EPB_aktiv 0 "nicht aktiviert" 1 "aktiviert" ;
VAL_ 262 ECD_Bremslicht 0 "Aus" 1 "Ein" ;
VAL_ 262 ESP_Verzoeg_EPB_verf 0 "nicht verfuegbar" 1 "System verfuegbar" ;
VAL_ 262 ESP_Status_Bremsdruck 0 "Bremse drucklos" 1 "mit Bremsdruck" ;
VAL_ 924 KL_Beschlagsgefahr 0 "keine_Beschlagsgefahr" 1 "Beschlagsgefahr" ;
VAL_ 924 ESP_07_alt 0 "aktuell" 1 "veraltet" ;
VAL_ 924 BCM1_GLW_Fernlicht_Anf 0 "Aus" 1 "Ein" ;
VAL_ 924 BCM1_Gleitende_Leuchtw_Anf 0 "Aus" 1 "Ein" ;
VAL_ 924 BCM1_Adaptive_Lichtvert_Anf 0 "Aus" 1 "Ein" ;
VAL_ 924 ESP_Offroad_Modus 0 "kein_ESP_Offroadmodus" 1 "ESP_Offroadmodus" ;
VAL_ 924 Wischer_vorne_aktiv 1 "Wischer vorne läuft" ;
VAL_ 924 HR_Tuer_geoeffnet 1 "Tuer geoeffnet" 0 "Tuer nicht geoeffnet" ;
VAL_ 924 HL_Tuer_geoeffnet 1 "Tuer geoeffnet" 0 "Tuer nicht geoeffnet" ;
VAL_ 924 BT_Tuer_geoeffnet 1 "Tuer geoeffnet" 0 "Tuer nicht geoeffnet" ;
VAL_ 924 BCM1_02_alt 1 "veraltet" 0 "aktuell" ;
VAL_ 924 BCM1_01_alt 1 "veraltet" 0 "aktuell" ;
VAL_ 924 FT_Tuer_geoeffnet 1 "Tuer geoeffnet" 0 "Tuer nicht geoeffnet" ;
VAL_ 924 BCM1_Rueckfahrlicht_Schalter 0 "aus" 1 "betaetigt" ;
VAL_ 924 BCM1_MH_WIV_Schalter 1 "MH offen" 0 "MH geschlossen" ;
VAL_ 924 BCM1_Aussen_Temp_ungef 253 "nicht verbaut" 254 "Initwert" 255 "Fehler" ;
VAL_ 924 BCM2_03_PAG_alt 1 "veraltet" 0 "aktuell" ;
VAL_ 924 Klima_02_alt 1 "veraltet" 0 "aktuell" ;
VAL_ 924 KL_Zuheizer_Freigabe 1 "Zuheizerfreigabe" 0 "keine Freigabe Zuheizer" ;
VAL_ 924 BCM_Handshake_STH 1 "EKP-Ansteuerung durch STH-Anforderung" 0 "keine EKP-Ansteuerung durch STH-Anforderung" ;
VAL_ 924 Wischer_01_alt 1 "veraltet" 0 "aktuell" ;
VAL_ 924 TSG_BT_1_alt 1 "veraltet" 0 "aktuell" ;
VAL_ 924 TSG_HL_1_alt 1 "veraltet" 0 "aktuell" ;
VAL_ 924 TSG_HR_1_alt 1 "veraltet" 0 "aktuell" ;
VAL_ 924 Klima_Sensor_02_alt 1 "veraltet" 0 "aktuell" ;
VAL_ 924 TSG_FT_1_alt 1 "veraltet" 0 "aktuell" ;
VAL_ 924 Parkhilfe_01_alt 1 "veraltet" 0 "aktuell" ;
VAL_ 924 Fahrwerk_02_alt 1 "veraltet" 0 "aktuell" ;
VAL_ 924 BCM1_OBD_FStatus_ATemp 0 "kein Fehler" 1 "KS-" 2 "KS+" 3 "OC (Leitungsunterbrechung)" 4 "OOR+ (out of range high)" 5 "OOR- (out of range low)" 6 "RC+ (Signal unplausibel hoch)" 7 "RC- (Signal unplausibel niedrig)" 8 "KS+/OC" 9 "KS-/OC" 10 "KS-/KS+" 11 "KS-/KS+/OC (allgemeiner Fehler)" ;
VAL_ 1604 ESP_Diagnose 1 "ESP_in_Diagnose" 0 "ESP_nicht_in_Diagnose" ;
VAL_ 1604 ESP_04_alt 0 "aktuell" 1 "veraltet" ;
VAL_ 1604 ZV_Tankklappe_offen 0 "Tankklappe_geschlossen" 1 "Tankklappe_offen" ;
VAL_ 1604 BCM_Tankwunsch 0 "Fehler_keine_Drucktankfunktionalitaet" 1 "keine_Betankung_erwuenscht" 2 "Betankung_erwuenscht" ;
VAL_ 1604 ZV_verriegelt_extern_ist 1 "Fahrzeug_aussen_verriegelt_Istzustand" ;
VAL_ 1604 BCM2_02_alt 1 "veraltet" 0 "aktuell" ;
VAL_ 1604 Kessy_01_alt 1 "veraltet" 0 "aktuell" ;
VAL_ 1604 FFB_CarFinder 0 "nicht aktiv" 1 "aktiv" ;
VAL_ 1604 FFB_Auf_Taste 1 "Taste am Funkschlüssel betätigt" 0 "Taste nicht betätigt" ;
VAL_ 1604 BCM1_01_alt 1 "veraltet" 0 "aktuell" ;
VAL_ 1604 LV_Nebelschlusslicht_Anzeige 1 "Aktiv" 0 "Inaktiv" ;
VAL_ 1604 LV_Abblendlicht_re_def 1 "defekt" 0 "OK" ;
VAL_ 1604 LV_Abblendlicht_li_def 1 "defekt" 0 "OK" ;
VAL_ 1604 BM_Autobahn 1 "Aktiv" 0 "Inaktiv" ;
VAL_ 1604 BCM1_Linksverkehr 0 "Rechtsverkehr" 1 "Linksverkehr" ;
VAL_ 1604 BCM1_Licht_Dunkelheit_aktiv 1 "Licht wegen Dunkelheit aktiv, nicht bei Autobahnlicht, Tagfahrlicht oder Regenlicht" ;
VAL_ 1604 BCM1_Allwetterlicht_Anf 0 "Licht_nicht_angefordert" 1 "Licht_ist_einzuschalten" ;
VAL_ 1604 BCM1_MH_Schalter 0 "MH_geschlossen" 1 "MH_offen" ;
VAL_ 1604 BH_Blinker_re 1 "Blinkerhebel_Richtung_rechts_betaetigt" 0 "nicht_betaetigt" ;
VAL_ 1604 BH_Blinker_li 1 "Blinkerhebel_Richtung_links_betaetigt" 0 "nicht_betaetigt" ;
VAL_ 1604 SMLS_01_alt 1 "veraltet" 0 "aktuell" ;
VAL_ 1604 BCM1_02_alt 1 "veraltet" 0 "aktuell" ;
VAL_ 1604 HYB_Anf_E_Mode_alt 1 "veraltet" 0 "aktuell" ;
VAL_ 1604 HYB_Anf_E_Mode 1 "Taster betätigt" 0 "Taster nicht betätigt" ;
VAL_ 130 GE_Schaltvorgang 1 "Schaltung aktiv" 0 "keine Schaltung" ;
VAL_ 130 GE_Status_Kupplung 3 "Fehler" 2 "Kupplung geschlossen" 1 "Kupplung geregelt" 0 "Kupplung geöffnet" ;
VAL_ 130 GE_MMom_Soll 1023 "Fehler" 1022 "kein Eingriff" ;
VAL_ 130 GE_MMom_Status 3 "Änderung mit Sprung" 2 "erhöhender Getriebeeingriff" 1 "reduzierender Getriebeeingriff" 0 "keine Anforderung" ;
VAL_ 130 GE_KD_Fehler 1 "mind. ein KD-Fehler vorhanden" 0 "kein KD-Fehler" ;
VAL_ 130 GE_Verbot_Ausblendung 1 "Verbot" 0 "kein_Verbot" ;
VAL_ 130 GE_MMom_Vorhalt 1022 "keine_Anforderung" 1023 "Fehler" ;
VAL_ 130 GE_Freig_MMom_Vorhalt 1 "freigegeben" 0 "nicht_freigegeben" ;
VAL_ 131 GE_Anf_Zylabsch 0 "Umschaltung erlaubt" 1 "Umschaltung verboten" 3 "VMB-Empfehlung" ;
VAL_ 131 GE_Synchro_Wunschdrehz 511 "Fehler" ;
VAL_ 131 GE_Synchro_Zeit 255 "Fehler" ;
VAL_ 131 GE_Mom_Begr_Gradient 255 "keine Begrenzung (Init)" ;
VAL_ 131 GE_Anheb_Solldrehz_Leerlauf 255 "Fehler" ;
VAL_ 131 GE_Vorsteuermoment 510 "Init" 511 "Fehler" ;
VAL_ 131 GE_Drehzahlmesser_Daempfung 0 "normale Dämpfung" 1 "dynamische Dämpfung" ;
VAL_ 131 GE_Schubabschalt_Unt 0 "inaktiv" 1 "aktiv" ;
VAL_ 131 GE_Freigabe_Synchro 0 "inaktiv" 1 "aktiv" ;
VAL_ 131 GE_HYB_DZ_Eingriff 0 "kein_Drehzahleingriff" 1 "Slip_Start" 2 "Low_Speed_Modus" ;
VAL_ 258 GE_Waehlhebel 15 "Fehler" 14 "Tippfunktion" 13 "frei" 12 "frei" 11 "frei" 10 "frei" 9 "Position S" 8 "Position D" 7 "Position N" 6 "Position R" 5 "Position P" 4 "frei" 3 "frei" 2 "frei" 1 "Init" 0 "Zwischenstellung" ;
VAL_ 258 GE_StartStopp_Info 3 "Systemfehler" 2 "Motoranlauf zwingend notwendig (Startanforderung)" 1 "Motoranlauf nicht zwingend notwendig (Stoppverbot, keine Startanforderung, evtl. Komforteinbussen)" 0 "Motorlauf langfristig nicht notwendig (Stoppfreigabe)" ;
VAL_ 258 GE_Freig_Langfr_Schutzmom 0 "nicht freigegeben" 1 "freigegeben" ;
VAL_ 258 GE_Uefkt 1023 "Fehler" ;
VAL_ 258 GE_Zielgang 0 "Gang P/N (ausgekuppelt)" 1 "Gang 1" 2 "Gang 2" 3 "Gang 3" 4 "Gang 4" 5 "Gang 5" 6 "Gang 6" 7 "Gang 7" 8 "Gang R" 11 "Gang 8" 12 "Gang 9" 14 "Istgang nicht definiert" 15 "Fehler" ;
VAL_ 258 GE_Langfr_Schutzmom 1022 "Init" 1023 "Fehler" ;
VAL_ 258 GE_Eingangsdrehz 16382 "Init" 16383 "Fehler" ;
VAL_ 258 GE_Notlauf 0 "kein Notlauf / Init" 1 "Getriebe im Notlauf" ;
VAL_ 258 GE_Codierung_MSG 0 "Codierung iO / Init" 1 "Codierung niO" ;
